VERSION "created by canmatrix"

NS_ :

BS_:

BU_: RadarFrontCenter VideoFrontCenter DASy ReceiveECU

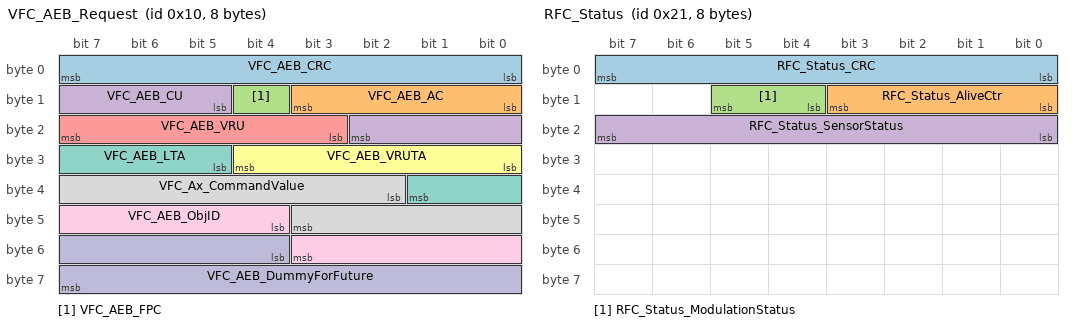
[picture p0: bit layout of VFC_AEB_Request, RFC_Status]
BO_ 16 VFC_AEB_Request: 8 VideoFrontCenter
 SG_ VFC_AEB_CRC : 0|8@1+ (1,0) [0|255] ""  DASy
 SG_ VFC_AEB_AC : 8|4@1+ (1,0) [0|15] ""  DASy
 SG_ VFC_AEB_FPC : 12|1@1+ (1,0) [0|1] ""  DASy
 SG_ VFC_AEB_CU : 13|6@1+ (1,0) [0|63] ""  DASy
 SG_ VFC_AEB_VRU : 19|5@1+ (1,0) [0|31] ""  DASy
 SG_ VFC_AEB_VRUTA : 24|5@1+ (1,0) [0|31] ""  DASy
 SG_ VFC_AEB_LTA : 29|5@1+ (1,0) [0|31] ""  DASy
 SG_ VFC_Ax_CommandValue : 34|10@1+ (0.024,-20.016) [-20.016|4.536] "m/s^2"  DASy
 SG_ VFC_AEB_ObjID : 44|8@1+ (1,0) [0|255] ""  DASy
 SG_ VFC_AEB_DummyForFuture : 52|12@1+ (1,0) [0|4095] ""  DASy

BO_ 32 VFC_Status: 20 VideoFrontCenter
 SG_ VFC_Status_CRC : 0|16@1+ (1,0) [0|65535] ""  DASy
 SG_ VFC_Status_AliveCtr : 16|8@1+ (1,0) [0|255] ""  DASy
 SG_ VFC_Status_SensorOrientYaw : 24|10@1+ (0.0005,-0.256) [-0.256|0.2555] "rad"  DASy
 SG_ VFC_Status_SensorOrientPitch : 34|10@1+ (0.0005,-0.256) [-0.256|0.2555] "rad"  DASy
 SG_ VFC_Status_SensorOrientRoll : 44|10@1+ (0.0005,-0.256) [-0.256|0.2555] "rad"  DASy
 SG_ VFC_Status_TimeStampStatus : 56|8@1+ (1,0) [0|255] ""  DASy
 SG_ VFC_Status_TimeStamp : 64|26@1+ (1,0) [0|67108863] "ms"  DASy
 SG_ VFC_Status_FrameNumber : 96|16@1+ (1,0) [0|65535] ""  DASy
 SG_ VFC_Status_SensorOriginPointX : 112|13@1+ (0.001,-4.096) [-4.096|4.095] "m"  DASy
 SG_ VFC_Status_SensorOriginPointY : 125|12@1+ (0.001,-2.048) [-2.048|2.047] "m"  DASy
 SG_ VFC_Status_SensorOriginPointZ : 137|13@1+ (0.001,0) [0|5] "m"  DASy
 SG_ VFC_Status_RollerBenchState : 150|2@1+ (1,0) [0|3] ""  DASy
 SG_ VFC_Status_SensorState : 152|4@1+ (1,0) [0|15] ""  DASy
 SG_ VFC_Status_CalibrationState : 156|3@1+ (1,0) [0|7] ""  DASy
 SG_ VFC_Status_TrafficFlowType : 159|1@1+ (1,0) [0|1] ""  DASy

BO_ 33 RFC_Status: 8 RadarFrontCenter
 SG_ RFC_Status_CRC : 0|8@1+ (1,0) [0|255] ""  VideoFrontCenter,DASy
 SG_ RFC_Status_AliveCtr : 8|4@1+ (1,0) [0|15] ""  VideoFrontCenter,DASy
 SG_ RFC_Status_ModulationStatus : 12|2@1+ (1,0) [0|3] ""  VideoFrontCenter,DASy
 SG_ RFC_Status_SensorStatus : 16|8@1+ (1,0) [0|255] ""  VideoFrontCenter,DASy

BO_ 52 VFC_ObjectHdr: 24 VideoFrontCenter
 SG_ VFC_ObjHdr_CRC : 0|16@1+ (1,0) [0|65535] ""  DASy
 SG_ VFC_ObjHdr_AliveCtr : 16|8@1+ (1,0) [0|255] ""  DASy
 SG_ VFC_ObjHdr_ProtBlockCtr : 24|4@1+ (1,0) [0|15] ""  DASy
 SG_ VFC_ObjHdr_IfVersionIdMajor : 32|8@1+ (1,0) [0|255] ""  DASy
 SG_ VFC_ObjHdr_IfVersionIdMinor : 40|8@1+ (1,0) [0|255] ""  DASy
 SG_ VFC_ObjHdr_NumValidObjects : 48|6@1+ (1,0) [0|32] ""  DASy
 SG_ VFC_ObjHdr_TimeStampStatus : 56|8@1+ (1,0) [0|255] ""  DASy
 SG_ VFC_ObjHdr_TimeStamp : 64|26@1+ (1,0) [0|67108863] "ms"  DASy
 SG_ VFC_ObjHdr_SensorStatus : 96|3@1+ (1,0) [0|7] ""  DASy
 SG_ VFC_ObjHdr_FocalLengthX : 112|8@1+ (1,1572) [1572|1827] "pixel"  DASy
 SG_ VFC_ObjHdr_FocalLengthY : 120|8@1+ (1,1572) [1572|1827] "pixel"  DASy
 SG_ VFC_ObjHdr_PrincipalPointU : 128|11@1+ (1,0) [0|2047] "pixel"  DASy
 SG_ VFC_ObjHdr_PrincipalPointV : 139|10@1+ (1,0) [0|1023] "pixel"  DASy

BO_ 54 VFC_Object00: 64 VideoFrontCenter
 SG_ VFC_Obj00_CRC : 0|16@1+ (1,0) [0|65535] ""  DASy
 SG_ VFC_Obj00_AliveCtr : 16|8@1+ (1,0) [0|255] ""  DASy
 SG_ VFC_Obj00_ProtBlockCtr : 24|4@1+ (1,0) [0|15] ""  DASy
 SG_ VFC_Obj00_ExistProb : 32|6@1+ (2,0) [0|100] "%"  DASy
 SG_ VFC_Obj00_MeasurementStatus : 38|2@1+ (1,0) [0|3] ""  DASy
 SG_ VFC_Obj00_ObjId : 40|6@1+ (1,0) [1|63] ""  DASy
 SG_ VFC_Obj00_Type : 46|4@1+ (1,0) [0|15] ""  DASy
 SG_ VFC_Obj00_TypeConf : 50|6@1+ (2,0) [0|100] "%"  DASy
 SG_ VFC_Obj00_VisibleView : 56|3@1+ (1,0) [0|7] ""  DASy
 SG_ VFC_Obj00_ClassifiedView : 59|3@1+ (1,0) [0|7] ""  DASy
 SG_ VFC_Obj00_Px : 62|12@1+ (0.05,0) [0|204.75] "m"  DASy
 SG_ VFC_Obj00_Py : 74|14@1+ (0.01,-81.92) [-81.92|81.91] "m"  DASy
 SG_ VFC_Obj00_PxStdDev : 88|10@1+ (0.05,0) [0|51.15] "m"  DASy
 SG_ VFC_Obj00_PyStdDev : 98|10@1+ (0.02,0) [0|20.46] "m"  DASy
 SG_ VFC_Obj00_OrientationYaw : 108|9@1+ (0.01,-2.56) [-1.57|1.57] "rad"  DASy
 SG_ VFC_Obj00_OrientationYawStdDev : 117|6@1+ (0.01,0) [0|0.63] "rad"  DASy
 SG_ VFC_Obj00_Length : 123|9@1+ (0.05,0) [0|25.55] "m"  DASy
 SG_ VFC_Obj00_Width : 132|10@1+ (0.01,0) [0|10.23] "m"  DASy
 SG_ VFC_Obj00_Height : 142|9@1+ (0.01,0) [0|5.11] "m"  DASy
 SG_ VFC_Obj00_LengthStdDev : 151|7@1+ (0.05,0) [0|6.35] "m"  DASy
 SG_ VFC_Obj00_WidthStdDev : 158|7@1+ (0.01,0) [0|1.27] "m"  DASy
 SG_ VFC_Obj00_HeightStdDev : 165|7@1+ (0.01,0) [0|1.27] "m"  DASy
 SG_ VFC_Obj00_Vx : 172|11@1+ (0.1,-154) [-154|50.7] "m/s"  DASy
 SG_ VFC_Obj00_Vy : 183|10@1+ (0.1,-51.2) [-51.2|51.1] "m/s"  DASy
 SG_ VFC_Obj00_VxStdDev : 193|10@1+ (0.1,0) [0|102.3] "m/s"  DASy
 SG_ VFC_Obj00_VyStdDev : 203|9@1+ (0.1,0) [0|51.1] "m/s"  DASy
 SG_ VFC_Obj00_Ax : 212|9@1+ (0.1,-25.6) [-25.6|25.5] "m/s^2"  DASy
 SG_ VFC_Obj00_LightStatTurnIndicator : 221|3@1+ (1,0) [0|7] ""  DASy
 SG_ VFC_Obj00_Ay : 224|8@1+ (0.1,-12.8) [-12.8|12.7] "m/s^2"  DASy
 SG_ VFC_Obj00_AxStdDev : 232|8@1+ (0.1,0) [0|25.5] "m/s^2"  DASy
 SG_ VFC_Obj00_AyStdDev : 240|8@1+ (0.1,0) [0|25.5] "m/s^2"  DASy
 SG_ VFC_Obj00_MovementProbLat : 248|6@1+ (2,0) [0|100] "%"  DASy
 SG_ VFC_Obj00_MovementProbLong : 254|6@1+ (2,0) [0|100] "%"  DASy
 SG_ VFC_Obj00_2DAngPosEdgeLeft : 260|13@1+ (0.00025,-1.024) [-1.024|1.02375] "unitless"  DASy
 SG_ VFC_Obj00_2DAngPosEdgeRight : 273|13@1+ (0.00025,-1.024) [-1.024|1.02375] "unitless"  DASy
 SG_ VFC_Obj00_2DAngPosEdgeFar : 286|13@1+ (0.00025,-1.024) [-1.024|1.02375] "unitless"  DASy
 SG_ VFC_Obj00_2DAngPosEdgeBot : 299|12@1+ (0.00025,-0.512) [-0.512|0.51175] "unitless"  DASy
 SG_ VFC_Obj00_OutsideRoad : 311|1@1+ (1,0) [0|1] "unitless"  DASy
 SG_ VFC_Obj00_2DAngPosEdgeLeftStdDev : 312|8@1+ (0.0002,0) [0|0.051] "unitless"  DASy
 SG_ VFC_Obj00_2DAngPosEdgeRightStdDe : 320|8@1+ (0.0002,0) [0|0.051] "unitless"  DASy
 SG_ VFC_Obj00_2DAngPosEdgeFarStdDev : 328|8@1+ (0.0002,0) [0|0.051] "unitless"  DASy
 SG_ VFC_Obj00_2DAngPosEdgeBotStdDev : 336|8@1+ (0.0002,0) [0|0.051] "unitless"  DASy
 SG_ VFC_Obj00_2DNormVx : 344|16@1+ (0.001,-40) [-40|25.535] "1/s"  DASy
 SG_ VFC_Obj00_2DNormVy : 360|13@1+ (0.001,-4.096) [-4.096|4.095] "1/s"  DASy
 SG_ VFC_Obj00_2DNormAx : 373|13@1+ (0.002,-10) [-10|6.382] "1/s^2"  DASy
 SG_ VFC_Obj00_2DNormVxStdDev : 386|10@1+ (0.001,0) [0|1.023] "1/s"  DASy
 SG_ VFC_Obj00_MeasurementSource : 396|4@1+ (1,0) [0|15] ""  DASy
 SG_ VFC_Obj00_2DNormVyStdDev : 400|8@1+ (0.001,0) [0|0.255] "1/s"  DASy
 SG_ VFC_Obj00_2DNormAxStdDev : 408|10@1+ (0.0025,0) [0|2.5575] "1/s^2"  DASy
 SG_ VFC_Obj00_2DScaleChange : 418|14@1+ (0.0001,0.5) [0.5|2.1383] "unitless"  DASy
 SG_ VFC_Obj00_2DScaleChangeStdDev : 432|10@1+ (0.0001,0) [0|0.1023] "unitless"  DASy
 SG_ VFC_Obj00_Reliability : 442|6@1+ (1,0) [0|63] ""  DASy
 SG_ VFC_Obj00_LightStatBrakeLight : 448|3@1+ (1,0) [0|7] ""  DASy
 SG_ VFC_Obj00_OutsideRoadMeasStatus : 451|2@1+ (1,0) [0|3] ""  DASy
 SG_ VFC_Obj00_Oncoming : 453|1@1+ (1,0) [0|1] "unitless"  DASy
 SG_ VFC_Obj00_OncomingMeasStatus : 454|2@1+ (1,0) [0|3] ""  DASy
 SG_ VFC_Obj00_MovementStanding : 456|1@1+ (1,0) [0|1] "unitless"  DASy
 SG_ VFC_Obj00_MovementStandingMeasSt : 457|2@1+ (1,0) [0|3] ""  DASy
 SG_ VFC_Obj00_MovementObserved : 459|1@1+ (1,0) [0|1] "unitless"  DASy
 SG_ VFC_Obj00_MovementObservedMeasSt : 460|1@1+ (1,0) [0|1] ""  DASy
 SG_ VFC_Obj00_TargetObjTypeAcc : 461|3@1+ (1,0) [0|7] ""  DASy
 SG_ VFC_Obj00_TargetObjTypeAccConf : 464|6@1+ (2,0) [0|100] "%"  DASy

BO_ 55 VFC_Object01: 64 VideoFrontCenter
 SG_ VFC_Obj01_CRC : 0|16@1+ (1,0) [0|65535] ""  DASy
 SG_ VFC_Obj01_AliveCtr : 16|8@1+ (1,0) [0|255] ""  DASy
 SG_ VFC_Obj01_ProtBlockCtr : 24|4@1+ (1,0) [0|15] ""  DASy
 SG_ VFC_Obj01_ExistProb : 32|6@1+ (2,0) [0|100] "%"  DASy
 SG_ VFC_Obj01_MeasurementStatus : 38|2@1+ (1,0) [0|3] ""  DASy
 SG_ VFC_Obj01_ObjId : 40|6@1+ (1,0) [1|63] ""  DASy
 SG_ VFC_Obj01_Type : 46|4@1+ (1,0) [0|15] ""  DASy
 SG_ VFC_Obj01_TypeConf : 50|6@1+ (2,0) [0|100] "%"  DASy
 SG_ VFC_Obj01_VisibleView : 56|3@1+ (1,0) [0|7] ""  DASy
 SG_ VFC_Obj01_ClassifiedView : 59|3@1+ (1,0) [0|7] ""  DASy
 SG_ VFC_Obj01_Px : 62|12@1+ (0.05,0) [0|204.75] "m"  DASy
 SG_ VFC_Obj01_Py : 74|14@1+ (0.01,-81.92) [-81.92|81.91] "m"  DASy
 SG_ VFC_Obj01_PxStdDev : 88|10@1+ (0.05,0) [0|51.15] "m"  DASy
 SG_ VFC_Obj01_PyStdDev : 98|10@1+ (0.02,0) [0|20.46] "m"  DASy
 SG_ VFC_Obj01_OrientationYaw : 108|9@1+ (0.01,-2.56) [-1.57|1.57] "rad"  DASy
 SG_ VFC_Obj01_OrientationYawStdDev : 117|6@1+ (0.01,0) [0|0.63] "rad"  DASy
 SG_ VFC_Obj01_Length : 123|9@1+ (0.05,0) [0|25.55] "m"  DASy
 SG_ VFC_Obj01_Width : 132|10@1+ (0.01,0) [0|10.23] "m"  DASy
 SG_ VFC_Obj01_Height : 142|9@1+ (0.01,0) [0|5.11] "m"  DASy
 SG_ VFC_Obj01_LengthStdDev : 151|7@1+ (0.05,0) [0|6.35] "m"  DASy
 SG_ VFC_Obj01_WidthStdDev : 158|7@1+ (0.01,0) [0|1.27] "m"  DASy
 SG_ VFC_Obj01_HeightStdDev : 165|7@1+ (0.01,0) [0|1.27] "m"  DASy
 SG_ VFC_Obj01_Vx : 172|11@1+ (0.1,-154) [-154|50.7] "m/s"  DASy
 SG_ VFC_Obj01_Vy : 183|10@1+ (0.1,-51.2) [-51.2|51.1] "m/s"  DASy
 SG_ VFC_Obj01_VxStdDev : 193|10@1+ (0.1,0) [0|102.3] "m/s"  DASy
 SG_ VFC_Obj01_VyStdDev : 203|9@1+ (0.1,0) [0|51.1] "m/s"  DASy
 SG_ VFC_Obj01_Ax : 212|9@1+ (0.1,-25.6) [-25.6|25.5] "m/s^2"  DASy
 SG_ VFC_Obj01_LightStatTurnIndicator : 221|3@1+ (1,0) [0|7] ""  DASy
 SG_ VFC_Obj01_Ay : 224|8@1+ (0.1,-12.8) [-12.8|12.7] "m/s^2"  DASy
 SG_ VFC_Obj01_AxStdDev : 232|8@1+ (0.1,0) [0|25.5] "m/s^2"  DASy
 SG_ VFC_Obj01_AyStdDev : 240|8@1+ (0.1,0) [0|25.5] "m/s^2"  DASy
 SG_ VFC_Obj01_MovementProbLat : 248|6@1+ (2,0) [0|100] "%"  DASy
 SG_ VFC_Obj01_MovementProbLong : 254|6@1+ (2,0) [0|100] "%"  DASy
 SG_ VFC_Obj01_2DAngPosEdgeLeft : 260|13@1+ (0.00025,-1.024) [-1.024|1.02375] "unitless"  DASy
 SG_ VFC_Obj01_2DAngPosEdgeRight : 273|13@1+ (0.00025,-1.024) [-1.024|1.02375] "unitless"  DASy
 SG_ VFC_Obj01_2DAngPosEdgeFar : 286|13@1+ (0.00025,-1.024) [-1.024|1.02375] "unitless"  DASy
 SG_ VFC_Obj01_2DAngPosEdgeBot : 299|12@1+ (0.00025,-0.512) [-0.512|0.51175] "unitless"  DASy
 SG_ VFC_Obj01_OutsideRoad : 311|1@1+ (1,0) [0|1] "unitless"  DASy
 SG_ VFC_Obj01_2DAngPosEdgeLeftStdDev : 312|8@1+ (0.0002,0) [0|0.051] "unitless"  DASy
 SG_ VFC_Obj01_2DAngPosEdgeRightStdDe : 320|8@1+ (0.0002,0) [0|0.051] "unitless"  DASy
 SG_ VFC_Obj01_2DAngPosEdgeFarStdDev : 328|8@1+ (0.0002,0) [0|0.051] "unitless"  DASy
 SG_ VFC_Obj01_2DAngPosEdgeBotStdDev : 336|8@1+ (0.0002,0) [0|0.051] "unitless"  DASy
 SG_ VFC_Obj01_2DNormVx : 344|16@1+ (0.001,-40) [-40|25.535] "1/s"  DASy
 SG_ VFC_Obj01_2DNormVy : 360|13@1+ (0.001,-4.096) [-4.096|4.095] "1/s"  DASy
 SG_ VFC_Obj01_2DNormAx : 373|13@1+ (0.002,-10) [-10|6.382] "1/s^2"  DASy
 SG_ VFC_Obj01_2DNormVxStdDev : 386|10@1+ (0.001,0) [0|1.023] "1/s"  DASy
 SG_ VFC_Obj01_MeasurementSource : 396|4@1+ (1,0) [0|15] ""  DASy
 SG_ VFC_Obj01_2DNormVyStdDev : 400|8@1+ (0.001,0) [0|0.255] "1/s"  DASy
 SG_ VFC_Obj01_2DNormAxStdDev : 408|10@1+ (0.0025,0) [0|2.5575] "1/s^2"  DASy
 SG_ VFC_Obj01_2DScaleChange : 418|14@1+ (0.0001,0.5) [0.5|2.1383] "unitless"  DASy
 SG_ VFC_Obj01_2DScaleChangeStdDev : 432|10@1+ (0.0001,0) [0|0.1023] "unitless"  DASy
 SG_ VFC_Obj01_Reliability : 442|6@1+ (1,0) [0|63] ""  DASy
 SG_ VFC_Obj01_LightStatBrakeLight : 448|3@1+ (1,0) [0|7] ""  DASy
 SG_ VFC_Obj01_OutsideRoadMeasStatus : 451|2@1+ (1,0) [0|3] ""  DASy
 SG_ VFC_Obj01_Oncoming : 453|1@1+ (1,0) [0|1] "unitless"  DASy
 SG_ VFC_Obj01_OncomingMeasStatus : 454|2@1+ (1,0) [0|3] ""  DASy
 SG_ VFC_Obj01_MovementStanding : 456|1@1+ (1,0) [0|1] "unitless"  DASy
 SG_ VFC_Obj01_MovementStandingMeasSt : 457|2@1+ (1,0) [0|3] ""  DASy
 SG_ VFC_Obj01_MovementObserved : 459|1@1+ (1,0) [0|1] "unitless"  DASy
 SG_ VFC_Obj01_MovementObservedMeasSt : 460|1@1+ (1,0) [0|1] ""  DASy
 SG_ VFC_Obj01_TargetObjTypeAcc : 461|3@1+ (1,0) [0|7] ""  DASy
 SG_ VFC_Obj01_TargetObjTypeAccConf : 464|6@1+ (2,0) [0|100] "%"  DASy

BO_ 56 VFC_Object02: 64 VideoFrontCenter
 SG_ VFC_Obj02_CRC : 0|16@1+ (1,0) [0|65535] ""  DASy
 SG_ VFC_Obj02_AliveCtr : 16|8@1+ (1,0) [0|255] ""  DASy
 SG_ VFC_Obj02_ProtBlockCtr : 24|4@1+ (1,0) [0|15] ""  DASy
 SG_ VFC_Obj02_ExistProb : 32|6@1+ (2,0) [0|100] "%"  DASy
 SG_ VFC_Obj02_MeasurementStatus : 38|2@1+ (1,0) [0|3] ""  DASy
 SG_ VFC_Obj02_ObjId : 40|6@1+ (1,0) [1|63] ""  DASy
 SG_ VFC_Obj02_Type : 46|4@1+ (1,0) [0|15] ""  DASy
 SG_ VFC_Obj02_TypeConf : 50|6@1+ (2,0) [0|100] "%"  DASy
 SG_ VFC_Obj02_VisibleView : 56|3@1+ (1,0) [0|7] ""  DASy
 SG_ VFC_Obj02_ClassifiedView : 59|3@1+ (1,0) [0|7] ""  DASy
 SG_ VFC_Obj02_Px : 62|12@1+ (0.05,0) [0|204.75] "m"  DASy
 SG_ VFC_Obj02_Py : 74|14@1+ (0.01,-81.92) [-81.92|81.91] "m"  DASy
 SG_ VFC_Obj02_PxStdDev : 88|10@1+ (0.05,0) [0|51.15] "m"  DASy
 SG_ VFC_Obj02_PyStdDev : 98|10@1+ (0.02,0) [0|20.46] "m"  DASy
 SG_ VFC_Obj02_OrientationYaw : 108|9@1+ (0.01,-2.56) [-1.57|1.57] "rad"  DASy
 SG_ VFC_Obj02_OrientationYawStdDev : 117|6@1+ (0.01,0) [0|0.63] "rad"  DASy
 SG_ VFC_Obj02_Length : 123|9@1+ (0.05,0) [0|25.55] "m"  DASy
 SG_ VFC_Obj02_Width : 132|10@1+ (0.01,0) [0|10.23] "m"  DASy
 SG_ VFC_Obj02_Height : 142|9@1+ (0.01,0) [0|5.11] "m"  DASy
 SG_ VFC_Obj02_LengthStdDev : 151|7@1+ (0.05,0) [0|6.35] "m"  DASy
 SG_ VFC_Obj02_WidthStdDev : 158|7@1+ (0.01,0) [0|1.27] "m"  DASy
 SG_ VFC_Obj02_HeightStdDev : 165|7@1+ (0.01,0) [0|1.27] "m"  DASy
 SG_ VFC_Obj02_Vx : 172|11@1+ (0.1,-154) [-154|50.7] "m/s"  DASy
 SG_ VFC_Obj02_Vy : 183|10@1+ (0.1,-51.2) [-51.2|51.1] "m/s"  DASy
 SG_ VFC_Obj02_VxStdDev : 193|10@1+ (0.1,0) [0|102.3] "m/s"  DASy
 SG_ VFC_Obj02_VyStdDev : 203|9@1+ (0.1,0) [0|51.1] "m/s"  DASy
 SG_ VFC_Obj02_Ax : 212|9@1+ (0.1,-25.6) [-25.6|25.5] "m/s^2"  DASy
 SG_ VFC_Obj02_LightStatTurnIndicator : 221|3@1+ (1,0) [0|7] ""  DASy
 SG_ VFC_Obj02_Ay : 224|8@1+ (0.1,-12.8) [-12.8|12.7] "m/s^2"  DASy
 SG_ VFC_Obj02_AxStdDev : 232|8@1+ (0.1,0) [0|25.5] "m/s^2"  DASy
 SG_ VFC_Obj02_AyStdDev : 240|8@1+ (0.1,0) [0|25.5] "m/s^2"  DASy
 SG_ VFC_Obj02_MovementProbLat : 248|6@1+ (2,0) [0|100] "%"  DASy
 SG_ VFC_Obj02_MovementProbLong : 254|6@1+ (2,0) [0|100] "%"  DASy
 SG_ VFC_Obj02_2DAngPosEdgeLeft : 260|13@1+ (0.00025,-1.024) [-1.024|1.02375] "unitless"  DASy
 SG_ VFC_Obj02_2DAngPosEdgeRight : 273|13@1+ (0.00025,-1.024) [-1.024|1.02375] "unitless"  DASy
 SG_ VFC_Obj02_2DAngPosEdgeFar : 286|13@1+ (0.00025,-1.024) [-1.024|1.02375] "unitless"  DASy
 SG_ VFC_Obj02_2DAngPosEdgeBot : 299|12@1+ (0.00025,-0.512) [-0.512|0.51175] "unitless"  DASy
 SG_ VFC_Obj02_OutsideRoad : 311|1@1+ (1,0) [0|1] "unitless"  DASy
 SG_ VFC_Obj02_2DAngPosEdgeLeftStdDev : 312|8@1+ (0.0002,0) [0|0.051] "unitless"  DASy
 SG_ VFC_Obj02_2DAngPosEdgeRightStdDe : 320|8@1+ (0.0002,0) [0|0.051] "unitless"  DASy
 SG_ VFC_Obj02_2DAngPosEdgeFarStdDev : 328|8@1+ (0.0002,0) [0|0.051] "unitless"  DASy
 SG_ VFC_Obj02_2DAngPosEdgeBotStdDev : 336|8@1+ (0.0002,0) [0|0.051] "unitless"  DASy
 SG_ VFC_Obj02_2DNormVx : 344|16@1+ (0.001,-40) [-40|25.535] "1/s"  DASy
 SG_ VFC_Obj02_2DNormVy : 360|13@1+ (0.001,-4.096) [-4.096|4.095] "1/s"  DASy
 SG_ VFC_Obj02_2DNormAx : 373|13@1+ (0.002,-10) [-10|6.382] "1/s^2"  DASy
 SG_ VFC_Obj02_2DNormVxStdDev : 386|10@1+ (0.001,0) [0|1.023] "1/s"  DASy
 SG_ VFC_Obj02_MeasurementSource : 396|4@1+ (1,0) [0|15] ""  DASy
 SG_ VFC_Obj02_2DNormVyStdDev : 400|8@1+ (0.001,0) [0|0.255] "1/s"  DASy
 SG_ VFC_Obj02_2DNormAxStdDev : 408|10@1+ (0.0025,0) [0|2.5575] "1/s^2"  DASy
 SG_ VFC_Obj02_2DScaleChange : 418|14@1+ (0.0001,0.5) [0.5|2.1383] "unitless"  DASy
 SG_ VFC_Obj02_2DScaleChangeStdDev : 432|10@1+ (0.0001,0) [0|0.1023] "unitless"  DASy
 SG_ VFC_Obj02_Reliability : 442|6@1+ (1,0) [0|63] ""  DASy
 SG_ VFC_Obj02_LightStatBrakeLight : 448|3@1+ (1,0) [0|7] ""  DASy
 SG_ VFC_Obj02_OutsideRoadMeasStatus : 451|2@1+ (1,0) [0|3] ""  DASy
 SG_ VFC_Obj02_Oncoming : 453|1@1+ (1,0) [0|1] "unitless"  DASy
 SG_ VFC_Obj02_OncomingMeasStatus : 454|2@1+ (1,0) [0|3] ""  DASy
 SG_ VFC_Obj02_MovementStanding : 456|1@1+ (1,0) [0|1] "unitless"  DASy
 SG_ VFC_Obj02_MovementStandingMeasSt : 457|2@1+ (1,0) [0|3] ""  DASy
 SG_ VFC_Obj02_MovementObserved : 459|1@1+ (1,0) [0|1] "unitless"  DASy
 SG_ VFC_Obj02_MovementObservedMeasSt : 460|1@1+ (1,0) [0|1] ""  DASy
 SG_ VFC_Obj02_TargetObjTypeAcc : 461|3@1+ (1,0) [0|7] ""  DASy
 SG_ VFC_Obj02_TargetObjTypeAccConf : 464|6@1+ (2,0) [0|100] "%"  DASy

BO_ 57 VFC_Object03: 64 VideoFrontCenter
 SG_ VFC_Obj03_CRC : 0|16@1+ (1,0) [0|65535] ""  DASy
 SG_ VFC_Obj03_AliveCtr : 16|8@1+ (1,0) [0|255] ""  DASy
 SG_ VFC_Obj03_ProtBlockCtr : 24|4@1+ (1,0) [0|15] ""  DASy
 SG_ VFC_Obj03_ExistProb : 32|6@1+ (2,0) [0|100] "%"  DASy
 SG_ VFC_Obj03_MeasurementStatus : 38|2@1+ (1,0) [0|3] ""  DASy
 SG_ VFC_Obj03_ObjId : 40|6@1+ (1,0) [1|63] ""  DASy
 SG_ VFC_Obj03_Type : 46|4@1+ (1,0) [0|15] ""  DASy
 SG_ VFC_Obj03_TypeConf : 50|6@1+ (2,0) [0|100] "%"  DASy
 SG_ VFC_Obj03_VisibleView : 56|3@1+ (1,0) [0|7] ""  DASy
 SG_ VFC_Obj03_ClassifiedView : 59|3@1+ (1,0) [0|7] ""  DASy
 SG_ VFC_Obj03_Px : 62|12@1+ (0.05,0) [0|204.75] "m"  DASy
 SG_ VFC_Obj03_Py : 74|14@1+ (0.01,-81.92) [-81.92|81.91] "m"  DASy
 SG_ VFC_Obj03_PxStdDev : 88|10@1+ (0.05,0) [0|51.15] "m"  DASy
 SG_ VFC_Obj03_PyStdDev : 98|10@1+ (0.02,0) [0|20.46] "m"  DASy
 SG_ VFC_Obj03_OrientationYaw : 108|9@1+ (0.01,-2.56) [-1.57|1.57] "rad"  DASy
 SG_ VFC_Obj03_OrientationYawStdDev : 117|6@1+ (0.01,0) [0|0.63] "rad"  DASy
 SG_ VFC_Obj03_Length : 123|9@1+ (0.05,0) [0|25.55] "m"  DASy
 SG_ VFC_Obj03_Width : 132|10@1+ (0.01,0) [0|10.23] "m"  DASy
 SG_ VFC_Obj03_Height : 142|9@1+ (0.01,0) [0|5.11] "m"  DASy
 SG_ VFC_Obj03_LengthStdDev : 151|7@1+ (0.05,0) [0|6.35] "m"  DASy
 SG_ VFC_Obj03_WidthStdDev : 158|7@1+ (0.01,0) [0|1.27] "m"  DASy
 SG_ VFC_Obj03_HeightStdDev : 165|7@1+ (0.01,0) [0|1.27] "m"  DASy
 SG_ VFC_Obj03_Vx : 172|11@1+ (0.1,-154) [-154|50.7] "m/s"  DASy
 SG_ VFC_Obj03_Vy : 183|10@1+ (0.1,-51.2) [-51.2|51.1] "m/s"  DASy
 SG_ VFC_Obj03_VxStdDev : 193|10@1+ (0.1,0) [0|102.3] "m/s"  DASy
 SG_ VFC_Obj03_VyStdDev : 203|9@1+ (0.1,0) [0|51.1] "m/s"  DASy
 SG_ VFC_Obj03_Ax : 212|9@1+ (0.1,-25.6) [-25.6|25.5] "m/s^2"  DASy
 SG_ VFC_Obj03_LightStatTurnIndicator : 221|3@1+ (1,0) [0|7] ""  DASy
 SG_ VFC_Obj03_Ay : 224|8@1+ (0.1,-12.8) [-12.8|12.7] "m/s^2"  DASy
 SG_ VFC_Obj03_AxStdDev : 232|8@1+ (0.1,0) [0|25.5] "m/s^2"  DASy
 SG_ VFC_Obj03_AyStdDev : 240|8@1+ (0.1,0) [0|25.5] "m/s^2"  DASy
 SG_ VFC_Obj03_MovementProbLat : 248|6@1+ (2,0) [0|100] "%"  DASy
 SG_ VFC_Obj03_MovementProbLong : 254|6@1+ (2,0) [0|100] "%"  DASy
 SG_ VFC_Obj03_2DAngPosEdgeLeft : 260|13@1+ (0.00025,-1.024) [-1.024|1.02375] "unitless"  DASy
 SG_ VFC_Obj03_2DAngPosEdgeRight : 273|13@1+ (0.00025,-1.024) [-1.024|1.02375] "unitless"  DASy
 SG_ VFC_Obj03_2DAngPosEdgeFar : 286|13@1+ (0.00025,-1.024) [-1.024|1.02375] "unitless"  DASy
 SG_ VFC_Obj03_2DAngPosEdgeBot : 299|12@1+ (0.00025,-0.512) [-0.512|0.51175] "unitless"  DASy
 SG_ VFC_Obj03_OutsideRoad : 311|1@1+ (1,0) [0|1] "unitless"  DASy
 SG_ VFC_Obj03_2DAngPosEdgeLeftStdDev : 312|8@1+ (0.0002,0) [0|0.051] "unitless"  DASy
 SG_ VFC_Obj03_2DAngPosEdgeRightStdDe : 320|8@1+ (0.0002,0) [0|0.051] "unitless"  DASy
 SG_ VFC_Obj03_2DAngPosEdgeFarStdDev : 328|8@1+ (0.0002,0) [0|0.051] "unitless"  DASy
 SG_ VFC_Obj03_2DAngPosEdgeBotStdDev : 336|8@1+ (0.0002,0) [0|0.051] "unitless"  DASy
 SG_ VFC_Obj03_2DNormVx : 344|16@1+ (0.001,-40) [-40|25.535] "1/s"  DASy
 SG_ VFC_Obj03_2DNormVy : 360|13@1+ (0.001,-4.096) [-4.096|4.095] "1/s"  DASy
 SG_ VFC_Obj03_2DNormAx : 373|13@1+ (0.002,-10) [-10|6.382] "1/s^2"  DASy
 SG_ VFC_Obj03_2DNormVxStdDev : 386|10@1+ (0.001,0) [0|1.023] "1/s"  DASy
 SG_ VFC_Obj03_MeasurementSource : 396|4@1+ (1,0) [0|15] ""  DASy
 SG_ VFC_Obj03_2DNormVyStdDev : 400|8@1+ (0.001,0) [0|0.255] "1/s"  DASy
 SG_ VFC_Obj03_2DNormAxStdDev : 408|10@1+ (0.0025,0) [0|2.5575] "1/s^2"  DASy
 SG_ VFC_Obj03_2DScaleChange : 418|14@1+ (0.0001,0.5) [0.5|2.1383] "unitless"  DASy
 SG_ VFC_Obj03_2DScaleChangeStdDev : 432|10@1+ (0.0001,0) [0|0.1023] "unitless"  DASy
 SG_ VFC_Obj03_Reliability : 442|6@1+ (1,0) [0|63] ""  DASy
 SG_ VFC_Obj03_LightStatBrakeLight : 448|3@1+ (1,0) [0|7] ""  DASy
 SG_ VFC_Obj03_OutsideRoadMeasStatus : 451|2@1+ (1,0) [0|3] ""  DASy
 SG_ VFC_Obj03_Oncoming : 453|1@1+ (1,0) [0|1] "unitless"  DASy
 SG_ VFC_Obj03_OncomingMeasStatus : 454|2@1+ (1,0) [0|3] ""  DASy
 SG_ VFC_Obj03_MovementStanding : 456|1@1+ (1,0) [0|1] "unitless"  DASy
 SG_ VFC_Obj03_MovementStandingMeasSt : 457|2@1+ (1,0) [0|3] ""  DASy
 SG_ VFC_Obj03_MovementObserved : 459|1@1+ (1,0) [0|1] "unitless"  DASy
 SG_ VFC_Obj03_MovementObservedMeasSt : 460|1@1+ (1,0) [0|1] ""  DASy
 SG_ VFC_Obj03_TargetObjTypeAcc : 461|3@1+ (1,0) [0|7] ""  DASy
 SG_ VFC_Obj03_TargetObjTypeAccConf : 464|6@1+ (2,0) [0|100] "%"  DASy

BO_ 58 VFC_Object04: 64 VideoFrontCenter
 SG_ VFC_Obj04_CRC : 0|16@1+ (1,0) [0|65535] ""  DASy
 SG_ VFC_Obj04_AliveCtr : 16|8@1+ (1,0) [0|255] ""  DASy
 SG_ VFC_Obj04_ProtBlockCtr : 24|4@1+ (1,0) [0|15] ""  DASy
 SG_ VFC_Obj04_ExistProb : 32|6@1+ (2,0) [0|100] "%"  DASy
 SG_ VFC_Obj04_MeasurementStatus : 38|2@1+ (1,0) [0|3] ""  DASy
 SG_ VFC_Obj04_ObjId : 40|6@1+ (1,0) [1|63] ""  DASy
 SG_ VFC_Obj04_Type : 46|4@1+ (1,0) [0|15] ""  DASy
 SG_ VFC_Obj04_TypeConf : 50|6@1+ (2,0) [0|100] "%"  DASy
 SG_ VFC_Obj04_VisibleView : 56|3@1+ (1,0) [0|7] ""  DASy
 SG_ VFC_Obj04_ClassifiedView : 59|3@1+ (1,0) [0|7] ""  DASy
 SG_ VFC_Obj04_Px : 62|12@1+ (0.05,0) [0|204.75] "m"  DASy
 SG_ VFC_Obj04_Py : 74|14@1+ (0.01,-81.92) [-81.92|81.91] "m"  DASy
 SG_ VFC_Obj04_PxStdDev : 88|10@1+ (0.05,0) [0|51.15] "m"  DASy
 SG_ VFC_Obj04_PyStdDev : 98|10@1+ (0.02,0) [0|20.46] "m"  DASy
 SG_ VFC_Obj04_OrientationYaw : 108|9@1+ (0.01,-2.56) [-1.57|1.57] "rad"  DASy
 SG_ VFC_Obj04_OrientationYawStdDev : 117|6@1+ (0.01,0) [0|0.63] "rad"  DASy
 SG_ VFC_Obj04_Length : 123|9@1+ (0.05,0) [0|25.55] "m"  DASy
 SG_ VFC_Obj04_Width : 132|10@1+ (0.01,0) [0|10.23] "m"  DASy
 SG_ VFC_Obj04_Height : 142|9@1+ (0.01,0) [0|5.11] "m"  DASy
 SG_ VFC_Obj04_LengthStdDev : 151|7@1+ (0.05,0) [0|6.35] "m"  DASy
 SG_ VFC_Obj04_WidthStdDev : 158|7@1+ (0.01,0) [0|1.27] "m"  DASy
 SG_ VFC_Obj04_HeightStdDev : 165|7@1+ (0.01,0) [0|1.27] "m"  DASy
 SG_ VFC_Obj04_Vx : 172|11@1+ (0.1,-154) [-154|50.7] "m/s"  DASy
 SG_ VFC_Obj04_Vy : 183|10@1+ (0.1,-51.2) [-51.2|51.1] "m/s"  DASy
 SG_ VFC_Obj04_VxStdDev : 193|10@1+ (0.1,0) [0|102.3] "m/s"  DASy
 SG_ VFC_Obj04_VyStdDev : 203|9@1+ (0.1,0) [0|51.1] "m/s"  DASy
 SG_ VFC_Obj04_Ax : 212|9@1+ (0.1,-25.6) [-25.6|25.5] "m/s^2"  DASy
 SG_ VFC_Obj04_LightStatTurnIndicator : 221|3@1+ (1,0) [0|7] ""  DASy
 SG_ VFC_Obj04_Ay : 224|8@1+ (0.1,-12.8) [-12.8|12.7] "m/s^2"  DASy
 SG_ VFC_Obj04_AxStdDev : 232|8@1+ (0.1,0) [0|25.5] "m/s^2"  DASy
 SG_ VFC_Obj04_AyStdDev : 240|8@1+ (0.1,0) [0|25.5] "m/s^2"  DASy
 SG_ VFC_Obj04_MovementProbLat : 248|6@1+ (2,0) [0|100] "%"  DASy
 SG_ VFC_Obj04_MovementProbLong : 254|6@1+ (2,0) [0|100] "%"  DASy
 SG_ VFC_Obj04_2DAngPosEdgeLeft : 260|13@1+ (0.00025,-1.024) [-1.024|1.02375] "unitless"  DASy
 SG_ VFC_Obj04_2DAngPosEdgeRight : 273|13@1+ (0.00025,-1.024) [-1.024|1.02375] "unitless"  DASy
 SG_ VFC_Obj04_2DAngPosEdgeFar : 286|13@1+ (0.00025,-1.024) [-1.024|1.02375] "unitless"  DASy
 SG_ VFC_Obj04_2DAngPosEdgeBot : 299|12@1+ (0.00025,-0.512) [-0.512|0.51175] "unitless"  DASy
 SG_ VFC_Obj04_OutsideRoad : 311|1@1+ (1,0) [0|1] "unitless"  DASy
 SG_ VFC_Obj04_2DAngPosEdgeLeftStdDev : 312|8@1+ (0.0002,0) [0|0.051] "unitless"  DASy
 SG_ VFC_Obj04_2DAngPosEdgeRightStdDe : 320|8@1+ (0.0002,0) [0|0.051] "unitless"  DASy
 SG_ VFC_Obj04_2DAngPosEdgeFarStdDev : 328|8@1+ (0.0002,0) [0|0.051] "unitless"  DASy
 SG_ VFC_Obj04_2DAngPosEdgeBotStdDev : 336|8@1+ (0.0002,0) [0|0.051] "unitless"  DASy
 SG_ VFC_Obj04_2DNormVx : 344|16@1+ (0.001,-40) [-40|25.535] "1/s"  DASy
 SG_ VFC_Obj04_2DNormVy : 360|13@1+ (0.001,-4.096) [-4.096|4.095] "1/s"  DASy
 SG_ VFC_Obj04_2DNormAx : 373|13@1+ (0.002,-10) [-10|6.382] "1/s^2"  DASy
 SG_ VFC_Obj04_2DNormVxStdDev : 386|10@1+ (0.001,0) [0|1.023] "1/s"  DASy
 SG_ VFC_Obj04_MeasurementSource : 396|4@1+ (1,0) [0|15] ""  DASy
 SG_ VFC_Obj04_2DNormVyStdDev : 400|8@1+ (0.001,0) [0|0.255] "1/s"  DASy
 SG_ VFC_Obj04_2DNormAxStdDev : 408|10@1+ (0.0025,0) [0|2.5575] "1/s^2"  DASy
 SG_ VFC_Obj04_2DScaleChange : 418|14@1+ (0.0001,0.5) [0.5|2.1383] "unitless"  DASy
 SG_ VFC_Obj04_2DScaleChangeStdDev : 432|10@1+ (0.0001,0) [0|0.1023] "unitless"  DASy
 SG_ VFC_Obj04_Reliability : 442|6@1+ (1,0) [0|63] ""  DASy
 SG_ VFC_Obj04_LightStatBrakeLight : 448|3@1+ (1,0) [0|7] ""  DASy
 SG_ VFC_Obj04_OutsideRoadMeasStatus : 451|2@1+ (1,0) [0|3] ""  DASy
 SG_ VFC_Obj04_Oncoming : 453|1@1+ (1,0) [0|1] "unitless"  DASy
 SG_ VFC_Obj04_OncomingMeasStatus : 454|2@1+ (1,0) [0|3] ""  DASy
 SG_ VFC_Obj04_MovementStanding : 456|1@1+ (1,0) [0|1] "unitless"  DASy
 SG_ VFC_Obj04_MovementStandingMeasSt : 457|2@1+ (1,0) [0|3] ""  DASy
 SG_ VFC_Obj04_MovementObserved : 459|1@1+ (1,0) [0|1] "unitless"  DASy
 SG_ VFC_Obj04_MovementObservedMeasSt : 460|1@1+ (1,0) [0|1] ""  DASy
 SG_ VFC_Obj04_TargetObjTypeAcc : 461|3@1+ (1,0) [0|7] ""  DASy
 SG_ VFC_Obj04_TargetObjTypeAccConf : 464|6@1+ (2,0) [0|100] "%"  DASy

BO_ 59 VFC_Object05: 64 VideoFrontCenter
 SG_ VFC_Obj05_CRC : 0|16@1+ (1,0) [0|65535] ""  DASy
 SG_ VFC_Obj05_AliveCtr : 16|8@1+ (1,0) [0|255] ""  DASy
 SG_ VFC_Obj05_ProtBlockCtr : 24|4@1+ (1,0) [0|15] ""  DASy
 SG_ VFC_Obj05_ExistProb : 32|6@1+ (2,0) [0|100] "%"  DASy
 SG_ VFC_Obj05_MeasurementStatus : 38|2@1+ (1,0) [0|3] ""  DASy
 SG_ VFC_Obj05_ObjId : 40|6@1+ (1,0) [1|63] ""  DASy
 SG_ VFC_Obj05_Type : 46|4@1+ (1,0) [0|15] ""  DASy
 SG_ VFC_Obj05_TypeConf : 50|6@1+ (2,0) [0|100] "%"  DASy
 SG_ VFC_Obj05_VisibleView : 56|3@1+ (1,0) [0|7] ""  DASy
 SG_ VFC_Obj05_ClassifiedView : 59|3@1+ (1,0) [0|7] ""  DASy
 SG_ VFC_Obj05_Px : 62|12@1+ (0.05,0) [0|204.75] "m"  DASy
 SG_ VFC_Obj05_Py : 74|14@1+ (0.01,-81.92) [-81.92|81.91] "m"  DASy
 SG_ VFC_Obj05_PxStdDev : 88|10@1+ (0.05,0) [0|51.15] "m"  DASy
 SG_ VFC_Obj05_PyStdDev : 98|10@1+ (0.02,0) [0|20.46] "m"  DASy
 SG_ VFC_Obj05_OrientationYaw : 108|9@1+ (0.01,-2.56) [-1.57|1.57] "rad"  DASy
 SG_ VFC_Obj05_OrientationYawStdDev : 117|6@1+ (0.01,0) [0|0.63] "rad"  DASy
 SG_ VFC_Obj05_Length : 123|9@1+ (0.05,0) [0|25.55] "m"  DASy
 SG_ VFC_Obj05_Width : 132|10@1+ (0.01,0) [0|10.23] "m"  DASy
 SG_ VFC_Obj05_Height : 142|9@1+ (0.01,0) [0|5.11] "m"  DASy
 SG_ VFC_Obj05_LengthStdDev : 151|7@1+ (0.05,0) [0|6.35] "m"  DASy
 SG_ VFC_Obj05_WidthStdDev : 158|7@1+ (0.01,0) [0|1.27] "m"  DASy
 SG_ VFC_Obj05_HeightStdDev : 165|7@1+ (0.01,0) [0|1.27] "m"  DASy
 SG_ VFC_Obj05_Vx : 172|11@1+ (0.1,-154) [-154|50.7] "m/s"  DASy
 SG_ VFC_Obj05_Vy : 183|10@1+ (0.1,-51.2) [-51.2|51.1] "m/s"  DASy
 SG_ VFC_Obj05_VxStdDev : 193|10@1+ (0.1,0) [0|102.3] "m/s"  DASy
 SG_ VFC_Obj05_VyStdDev : 203|9@1+ (0.1,0) [0|51.1] "m/s"  DASy
 SG_ VFC_Obj05_Ax : 212|9@1+ (0.1,-25.6) [-25.6|25.5] "m/s^2"  DASy
 SG_ VFC_Obj05_LightStatTurnIndicator : 221|3@1+ (1,0) [0|7] ""  DASy
 SG_ VFC_Obj05_Ay : 224|8@1+ (0.1,-12.8) [-12.8|12.7] "m/s^2"  DASy
 SG_ VFC_Obj05_AxStdDev : 232|8@1+ (0.1,0) [0|25.5] "m/s^2"  DASy
 SG_ VFC_Obj05_AyStdDev : 240|8@1+ (0.1,0) [0|25.5] "m/s^2"  DASy
 SG_ VFC_Obj05_MovementProbLat : 248|6@1+ (2,0) [0|100] "%"  DASy
 SG_ VFC_Obj05_MovementProbLong : 254|6@1+ (2,0) [0|100] "%"  DASy
 SG_ VFC_Obj05_2DAngPosEdgeLeft : 260|13@1+ (0.00025,-1.024) [-1.024|1.02375] "unitless"  DASy
 SG_ VFC_Obj05_2DAngPosEdgeRight : 273|13@1+ (0.00025,-1.024) [-1.024|1.02375] "unitless"  DASy
 SG_ VFC_Obj05_2DAngPosEdgeFar : 286|13@1+ (0.00025,-1.024) [-1.024|1.02375] "unitless"  DASy
 SG_ VFC_Obj05_2DAngPosEdgeBot : 299|12@1+ (0.00025,-0.512) [-0.512|0.51175] "unitless"  DASy
 SG_ VFC_Obj05_OutsideRoad : 311|1@1+ (1,0) [0|1] "unitless"  DASy
 SG_ VFC_Obj05_2DAngPosEdgeLeftStdDev : 312|8@1+ (0.0002,0) [0|0.051] "unitless"  DASy
 SG_ VFC_Obj05_2DAngPosEdgeRightStdDe : 320|8@1+ (0.0002,0) [0|0.051] "unitless"  DASy
 SG_ VFC_Obj05_2DAngPosEdgeFarStdDev : 328|8@1+ (0.0002,0) [0|0.051] "unitless"  DASy
 SG_ VFC_Obj05_2DAngPosEdgeBotStdDev : 336|8@1+ (0.0002,0) [0|0.051] "unitless"  DASy
 SG_ VFC_Obj05_2DNormVx : 344|16@1+ (0.001,-40) [-40|25.535] "1/s"  DASy
 SG_ VFC_Obj05_2DNormVy : 360|13@1+ (0.001,-4.096) [-4.096|4.095] "1/s"  DASy
 SG_ VFC_Obj05_2DNormAx : 373|13@1+ (0.002,-10) [-10|6.382] "1/s^2"  DASy
 SG_ VFC_Obj05_2DNormVxStdDev : 386|10@1+ (0.001,0) [0|1.023] "1/s"  DASy
 SG_ VFC_Obj05_MeasurementSource : 396|4@1+ (1,0) [0|15] ""  DASy
 SG_ VFC_Obj05_2DNormVyStdDev : 400|8@1+ (0.001,0) [0|0.255] "1/s"  DASy
 SG_ VFC_Obj05_2DNormAxStdDev : 408|10@1+ (0.0025,0) [0|2.5575] "1/s^2"  DASy
 SG_ VFC_Obj05_2DScaleChange : 418|14@1+ (0.0001,0.5) [0.5|2.1383] "unitless"  DASy
 SG_ VFC_Obj05_2DScaleChangeStdDev : 432|10@1+ (0.0001,0) [0|0.1023] "unitless"  DASy
 SG_ VFC_Obj05_Reliability : 442|6@1+ (1,0) [0|63] ""  DASy
 SG_ VFC_Obj05_LightStatBrakeLight : 448|3@1+ (1,0) [0|7] ""  DASy
 SG_ VFC_Obj05_OutsideRoadMeasStatus : 451|2@1+ (1,0) [0|3] ""  DASy
 SG_ VFC_Obj05_Oncoming : 453|1@1+ (1,0) [0|1] "unitless"  DASy
 SG_ VFC_Obj05_OncomingMeasStatus : 454|2@1+ (1,0) [0|3] ""  DASy
 SG_ VFC_Obj05_MovementStanding : 456|1@1+ (1,0) [0|1] "unitless"  DASy
 SG_ VFC_Obj05_MovementStandingMeasSt : 457|2@1+ (1,0) [0|3] ""  DASy
 SG_ VFC_Obj05_MovementObserved : 459|1@1+ (1,0) [0|1] "unitless"  DASy
 SG_ VFC_Obj05_MovementObservedMeasSt : 460|1@1+ (1,0) [0|1] ""  DASy
 SG_ VFC_Obj05_TargetObjTypeAcc : 461|3@1+ (1,0) [0|7] ""  DASy
 SG_ VFC_Obj05_TargetObjTypeAccConf : 464|6@1+ (2,0) [0|100] "%"  DASy

BO_ 60 VFC_Object06: 64 VideoFrontCenter
 SG_ VFC_Obj06_CRC : 0|16@1+ (1,0) [0|65535] ""  DASy
 SG_ VFC_Obj06_AliveCtr : 16|8@1+ (1,0) [0|255] ""  DASy
 SG_ VFC_Obj06_ProtBlockCtr : 24|4@1+ (1,0) [0|15] ""  DASy
 SG_ VFC_Obj06_ExistProb : 32|6@1+ (2,0) [0|100] "%"  DASy
 SG_ VFC_Obj06_MeasurementStatus : 38|2@1+ (1,0) [0|3] ""  DASy
 SG_ VFC_Obj06_ObjId : 40|6@1+ (1,0) [1|63] ""  DASy
 SG_ VFC_Obj06_Type : 46|4@1+ (1,0) [0|15] ""  DASy
 SG_ VFC_Obj06_TypeConf : 50|6@1+ (2,0) [0|100] "%"  DASy
 SG_ VFC_Obj06_VisibleView : 56|3@1+ (1,0) [0|7] ""  DASy
 SG_ VFC_Obj06_ClassifiedView : 59|3@1+ (1,0) [0|7] ""  DASy
 SG_ VFC_Obj06_Px : 62|12@1+ (0.05,0) [0|204.75] "m"  DASy
 SG_ VFC_Obj06_Py : 74|14@1+ (0.01,-81.92) [-81.92|81.91] "m"  DASy
 SG_ VFC_Obj06_PxStdDev : 88|10@1+ (0.05,0) [0|51.15] "m"  DASy
 SG_ VFC_Obj06_PyStdDev : 98|10@1+ (0.02,0) [0|20.46] "m"  DASy
 SG_ VFC_Obj06_OrientationYaw : 108|9@1+ (0.01,-2.56) [-1.57|1.57] "rad"  DASy
 SG_ VFC_Obj06_OrientationYawStdDev : 117|6@1+ (0.01,0) [0|0.63] "rad"  DASy
 SG_ VFC_Obj06_Length : 123|9@1+ (0.05,0) [0|25.55] "m"  DASy
 SG_ VFC_Obj06_Width : 132|10@1+ (0.01,0) [0|10.23] "m"  DASy
 SG_ VFC_Obj06_Height : 142|9@1+ (0.01,0) [0|5.11] "m"  DASy
 SG_ VFC_Obj06_LengthStdDev : 151|7@1+ (0.05,0) [0|6.35] "m"  DASy
 SG_ VFC_Obj06_WidthStdDev : 158|7@1+ (0.01,0) [0|1.27] "m"  DASy
 SG_ VFC_Obj06_HeightStdDev : 165|7@1+ (0.01,0) [0|1.27] "m"  DASy
 SG_ VFC_Obj06_Vx : 172|11@1+ (0.1,-154) [-154|50.7] "m/s"  DASy
 SG_ VFC_Obj06_Vy : 183|10@1+ (0.1,-51.2) [-51.2|51.1] "m/s"  DASy
 SG_ VFC_Obj06_VxStdDev : 193|10@1+ (0.1,0) [0|102.3] "m/s"  DASy
 SG_ VFC_Obj06_VyStdDev : 203|9@1+ (0.1,0) [0|51.1] "m/s"  DASy
 SG_ VFC_Obj06_Ax : 212|9@1+ (0.1,-25.6) [-25.6|25.5] "m/s^2"  DASy
 SG_ VFC_Obj06_LightStatTurnIndicator : 221|3@1+ (1,0) [0|7] ""  DASy
 SG_ VFC_Obj06_Ay : 224|8@1+ (0.1,-12.8) [-12.8|12.7] "m/s^2"  DASy
 SG_ VFC_Obj06_AxStdDev : 232|8@1+ (0.1,0) [0|25.5] "m/s^2"  DASy
 SG_ VFC_Obj06_AyStdDev : 240|8@1+ (0.1,0) [0|25.5] "m/s^2"  DASy
 SG_ VFC_Obj06_MovementProbLat : 248|6@1+ (2,0) [0|100] "%"  DASy
 SG_ VFC_Obj06_MovementProbLong : 254|6@1+ (2,0) [0|100] "%"  DASy
 SG_ VFC_Obj06_2DAngPosEdgeLeft : 260|13@1+ (0.00025,-1.024) [-1.024|1.02375] "unitless"  DASy
 SG_ VFC_Obj06_2DAngPosEdgeRight : 273|13@1+ (0.00025,-1.024) [-1.024|1.02375] "unitless"  DASy
 SG_ VFC_Obj06_2DAngPosEdgeFar : 286|13@1+ (0.00025,-1.024) [-1.024|1.02375] "unitless"  DASy
 SG_ VFC_Obj06_2DAngPosEdgeBot : 299|12@1+ (0.00025,-0.512) [-0.512|0.51175] "unitless"  DASy
 SG_ VFC_Obj06_OutsideRoad : 311|1@1+ (1,0) [0|1] "unitless"  DASy
 SG_ VFC_Obj06_2DAngPosEdgeLeftStdDev : 312|8@1+ (0.0002,0) [0|0.051] "unitless"  DASy
 SG_ VFC_Obj06_2DAngPosEdgeRightStdDe : 320|8@1+ (0.0002,0) [0|0.051] "unitless"  DASy
 SG_ VFC_Obj06_2DAngPosEdgeFarStdDev : 328|8@1+ (0.0002,0) [0|0.051] "unitless"  DASy
 SG_ VFC_Obj06_2DAngPosEdgeBotStdDev : 336|8@1+ (0.0002,0) [0|0.051] "unitless"  DASy
 SG_ VFC_Obj06_2DNormVx : 344|16@1+ (0.001,-40) [-40|25.535] "1/s"  DASy
 SG_ VFC_Obj06_2DNormVy : 360|13@1+ (0.001,-4.096) [-4.096|4.095] "1/s"  DASy
 SG_ VFC_Obj06_2DNormAx : 373|13@1+ (0.002,-10) [-10|6.382] "1/s^2"  DASy
 SG_ VFC_Obj06_2DNormVxStdDev : 386|10@1+ (0.001,0) [0|1.023] "1/s"  DASy
 SG_ VFC_Obj06_MeasurementSource : 396|4@1+ (1,0) [0|15] ""  DASy
 SG_ VFC_Obj06_2DNormVyStdDev : 400|8@1+ (0.001,0) [0|0.255] "1/s"  DASy
 SG_ VFC_Obj06_2DNormAxStdDev : 408|10@1+ (0.0025,0) [0|2.5575] "1/s^2"  DASy
 SG_ VFC_Obj06_2DScaleChange : 418|14@1+ (0.0001,0.5) [0.5|2.1383] "unitless"  DASy
 SG_ VFC_Obj06_2DScaleChangeStdDev : 432|10@1+ (0.0001,0) [0|0.1023] "unitless"  DASy
 SG_ VFC_Obj06_Reliability : 442|6@1+ (1,0) [0|63] ""  DASy
 SG_ VFC_Obj06_LightStatBrakeLight : 448|3@1+ (1,0) [0|7] ""  DASy
 SG_ VFC_Obj06_OutsideRoadMeasStatus : 451|2@1+ (1,0) [0|3] ""  DASy
 SG_ VFC_Obj06_Oncoming : 453|1@1+ (1,0) [0|1] "unitless"  DASy
 SG_ VFC_Obj06_OncomingMeasStatus : 454|2@1+ (1,0) [0|3] ""  DASy
 SG_ VFC_Obj06_MovementStanding : 456|1@1+ (1,0) [0|1] "unitless"  DASy
 SG_ VFC_Obj06_MovementStandingMeasSt : 457|2@1+ (1,0) [0|3] ""  DASy
 SG_ VFC_Obj06_MovementObserved : 459|1@1+ (1,0) [0|1] "unitless"  DASy
 SG_ VFC_Obj06_MovementObservedMeasSt : 460|1@1+ (1,0) [0|1] ""  DASy
 SG_ VFC_Obj06_TargetObjTypeAcc : 461|3@1+ (1,0) [0|7] ""  DASy
 SG_ VFC_Obj06_TargetObjTypeAccConf : 464|6@1+ (2,0) [0|100] "%"  DASy

BO_ 61 VFC_Object07: 64 VideoFrontCenter
 SG_ VFC_Obj07_CRC : 0|16@1+ (1,0) [0|65535] ""  DASy
 SG_ VFC_Obj07_AliveCtr : 16|8@1+ (1,0) [0|255] ""  DASy
 SG_ VFC_Obj07_ProtBlockCtr : 24|4@1+ (1,0) [0|15] ""  DASy
 SG_ VFC_Obj07_ExistProb : 32|6@1+ (2,0) [0|100] "%"  DASy
 SG_ VFC_Obj07_MeasurementStatus : 38|2@1+ (1,0) [0|3] ""  DASy
 SG_ VFC_Obj07_ObjId : 40|6@1+ (1,0) [1|63] ""  DASy
 SG_ VFC_Obj07_Type : 46|4@1+ (1,0) [0|15] ""  DASy
 SG_ VFC_Obj07_TypeConf : 50|6@1+ (2,0) [0|100] "%"  DASy
 SG_ VFC_Obj07_VisibleView : 56|3@1+ (1,0) [0|7] ""  DASy
 SG_ VFC_Obj07_ClassifiedView : 59|3@1+ (1,0) [0|7] ""  DASy
 SG_ VFC_Obj07_Px : 62|12@1+ (0.05,0) [0|204.75] "m"  DASy
 SG_ VFC_Obj07_Py : 74|14@1+ (0.01,-81.92) [-81.92|81.91] "m"  DASy
 SG_ VFC_Obj07_PxStdDev : 88|10@1+ (0.05,0) [0|51.15] "m"  DASy
 SG_ VFC_Obj07_PyStdDev : 98|10@1+ (0.02,0) [0|20.46] "m"  DASy
 SG_ VFC_Obj07_OrientationYaw : 108|9@1+ (0.01,-2.56) [-1.57|1.57] "rad"  DASy
 SG_ VFC_Obj07_OrientationYawStdDev : 117|6@1+ (0.01,0) [0|0.63] "rad"  DASy
 SG_ VFC_Obj07_Length : 123|9@1+ (0.05,0) [0|25.55] "m"  DASy
 SG_ VFC_Obj07_Width : 132|10@1+ (0.01,0) [0|10.23] "m"  DASy
 SG_ VFC_Obj07_Height : 142|9@1+ (0.01,0) [0|5.11] "m"  DASy
 SG_ VFC_Obj07_LengthStdDev : 151|7@1+ (0.05,0) [0|6.35] "m"  DASy
 SG_ VFC_Obj07_WidthStdDev : 158|7@1+ (0.01,0) [0|1.27] "m"  DASy
 SG_ VFC_Obj07_HeightStdDev : 165|7@1+ (0.01,0) [0|1.27] "m"  DASy
 SG_ VFC_Obj07_Vx : 172|11@1+ (0.1,-154) [-154|50.7] "m/s"  DASy
 SG_ VFC_Obj07_Vy : 183|10@1+ (0.1,-51.2) [-51.2|51.1] "m/s"  DASy
 SG_ VFC_Obj07_VxStdDev : 193|10@1+ (0.1,0) [0|102.3] "m/s"  DASy
 SG_ VFC_Obj07_VyStdDev : 203|9@1+ (0.1,0) [0|51.1] "m/s"  DASy
 SG_ VFC_Obj07_Ax : 212|9@1+ (0.1,-25.6) [-25.6|25.5] "m/s^2"  DASy
 SG_ VFC_Obj07_LightStatTurnIndicator : 221|3@1+ (1,0) [0|7] ""  DASy
 SG_ VFC_Obj07_Ay : 224|8@1+ (0.1,-12.8) [-12.8|12.7] "m/s^2"  DASy
 SG_ VFC_Obj07_AxStdDev : 232|8@1+ (0.1,0) [0|25.5] "m/s^2"  DASy
 SG_ VFC_Obj07_AyStdDev : 240|8@1+ (0.1,0) [0|25.5] "m/s^2"  DASy
 SG_ VFC_Obj07_MovementProbLat : 248|6@1+ (2,0) [0|100] "%"  DASy
 SG_ VFC_Obj07_MovementProbLong : 254|6@1+ (2,0) [0|100] "%"  DASy
 SG_ VFC_Obj07_2DAngPosEdgeLeft : 260|13@1+ (0.00025,-1.024) [-1.024|1.02375] "unitless"  DASy
 SG_ VFC_Obj07_2DAngPosEdgeRight : 273|13@1+ (0.00025,-1.024) [-1.024|1.02375] "unitless"  DASy
 SG_ VFC_Obj07_2DAngPosEdgeFar : 286|13@1+ (0.00025,-1.024) [-1.024|1.02375] "unitless"  DASy
 SG_ VFC_Obj07_2DAngPosEdgeBot : 299|12@1+ (0.00025,-0.512) [-0.512|0.51175] "unitless"  DASy
 SG_ VFC_Obj07_OutsideRoad : 311|1@1+ (1,0) [0|1] "unitless"  DASy
 SG_ VFC_Obj07_2DAngPosEdgeLeftStdDev : 312|8@1+ (0.0002,0) [0|0.051] "unitless"  DASy
 SG_ VFC_Obj07_2DAngPosEdgeRightStdDe : 320|8@1+ (0.0002,0) [0|0.051] "unitless"  DASy
 SG_ VFC_Obj07_2DAngPosEdgeFarStdDev : 328|8@1+ (0.0002,0) [0|0.051] "unitless"  DASy
 SG_ VFC_Obj07_2DAngPosEdgeBotStdDev : 336|8@1+ (0.0002,0) [0|0.051] "unitless"  DASy
 SG_ VFC_Obj07_2DNormVx : 344|16@1+ (0.001,-40) [-40|25.535] "1/s"  DASy
 SG_ VFC_Obj07_2DNormVy : 360|13@1+ (0.001,-4.096) [-4.096|4.095] "1/s"  DASy
 SG_ VFC_Obj07_2DNormAx : 373|13@1+ (0.002,-10) [-10|6.382] "1/s^2"  DASy
 SG_ VFC_Obj07_2DNormVxStdDev : 386|10@1+ (0.001,0) [0|1.023] "1/s"  DASy
 SG_ VFC_Obj07_MeasurementSource : 396|4@1+ (1,0) [0|15] ""  DASy
 SG_ VFC_Obj07_2DNormVyStdDev : 400|8@1+ (0.001,0) [0|0.255] "1/s"  DASy
 SG_ VFC_Obj07_2DNormAxStdDev : 408|10@1+ (0.0025,0) [0|2.5575] "1/s^2"  DASy
 SG_ VFC_Obj07_2DScaleChange : 418|14@1+ (0.0001,0.5) [0.5|2.1383] "unitless"  DASy
 SG_ VFC_Obj07_2DScaleChangeStdDev : 432|10@1+ (0.0001,0) [0|0.1023] "unitless"  DASy
 SG_ VFC_Obj07_Reliability : 442|6@1+ (1,0) [0|63] ""  DASy
 SG_ VFC_Obj07_LightStatBrakeLight : 448|3@1+ (1,0) [0|7] ""  DASy
 SG_ VFC_Obj07_OutsideRoadMeasStatus : 451|2@1+ (1,0) [0|3] ""  DASy
 SG_ VFC_Obj07_Oncoming : 453|1@1+ (1,0) [0|1] "unitless"  DASy
 SG_ VFC_Obj07_OncomingMeasStatus : 454|2@1+ (1,0) [0|3] ""  DASy
 SG_ VFC_Obj07_MovementStanding : 456|1@1+ (1,0) [0|1] "unitless"  DASy
 SG_ VFC_Obj07_MovementStandingMeasSt : 457|2@1+ (1,0) [0|3] ""  DASy
 SG_ VFC_Obj07_MovementObserved : 459|1@1+ (1,0) [0|1] "unitless"  DASy
 SG_ VFC_Obj07_MovementObservedMeasSt : 460|1@1+ (1,0) [0|1] ""  DASy
 SG_ VFC_Obj07_TargetObjTypeAcc : 461|3@1+ (1,0) [0|7] ""  DASy
 SG_ VFC_Obj07_TargetObjTypeAccConf : 464|6@1+ (2,0) [0|100] "%"  DASy

BO_ 62 VFC_Object08: 64 VideoFrontCenter
 SG_ VFC_Obj08_CRC : 0|16@1+ (1,0) [0|65535] ""  DASy
 SG_ VFC_Obj08_AliveCtr : 16|8@1+ (1,0) [0|255] ""  DASy
 SG_ VFC_Obj08_ProtBlockCtr : 24|4@1+ (1,0) [0|15] ""  DASy
 SG_ VFC_Obj08_ExistProb : 32|6@1+ (2,0) [0|100] "%"  DASy
 SG_ VFC_Obj08_MeasurementStatus : 38|2@1+ (1,0) [0|3] ""  DASy
 SG_ VFC_Obj08_ObjId : 40|6@1+ (1,0) [1|63] ""  DASy
 SG_ VFC_Obj08_Type : 46|4@1+ (1,0) [0|15] ""  DASy
 SG_ VFC_Obj08_TypeConf : 50|6@1+ (2,0) [0|100] "%"  DASy
 SG_ VFC_Obj08_VisibleView : 56|3@1+ (1,0) [0|7] ""  DASy
 SG_ VFC_Obj08_ClassifiedView : 59|3@1+ (1,0) [0|7] ""  DASy
 SG_ VFC_Obj08_Px : 62|12@1+ (0.05,0) [0|204.75] "m"  DASy
 SG_ VFC_Obj08_Py : 74|14@1+ (0.01,-81.92) [-81.92|81.91] "m"  DASy
 SG_ VFC_Obj08_PxStdDev : 88|10@1+ (0.05,0) [0|51.15] "m"  DASy
 SG_ VFC_Obj08_PyStdDev : 98|10@1+ (0.02,0) [0|20.46] "m"  DASy
 SG_ VFC_Obj08_OrientationYaw : 108|9@1+ (0.01,-2.56) [-1.57|1.57] "rad"  DASy
 SG_ VFC_Obj08_OrientationYawStdDev : 117|6@1+ (0.01,0) [0|0.63] "rad"  DASy
 SG_ VFC_Obj08_Length : 123|9@1+ (0.05,0) [0|25.55] "m"  DASy
 SG_ VFC_Obj08_Width : 132|10@1+ (0.01,0) [0|10.23] "m"  DASy
 SG_ VFC_Obj08_Height : 142|9@1+ (0.01,0) [0|5.11] "m"  DASy
 SG_ VFC_Obj08_LengthStdDev : 151|7@1+ (0.05,0) [0|6.35] "m"  DASy
 SG_ VFC_Obj08_WidthStdDev : 158|7@1+ (0.01,0) [0|1.27] "m"  DASy
 SG_ VFC_Obj08_HeightStdDev : 165|7@1+ (0.01,0) [0|1.27] "m"  DASy
 SG_ VFC_Obj08_Vx : 172|11@1+ (0.1,-154) [-154|50.7] "m/s"  DASy
 SG_ VFC_Obj08_Vy : 183|10@1+ (0.1,-51.2) [-51.2|51.1] "m/s"  DASy
 SG_ VFC_Obj08_VxStdDev : 193|10@1+ (0.1,0) [0|102.3] "m/s"  DASy
 SG_ VFC_Obj08_VyStdDev : 203|9@1+ (0.1,0) [0|51.1] "m/s"  DASy
 SG_ VFC_Obj08_Ax : 212|9@1+ (0.1,-25.6) [-25.6|25.5] "m/s^2"  DASy
 SG_ VFC_Obj08_LightStatTurnIndicator : 221|3@1+ (1,0) [0|7] ""  DASy
 SG_ VFC_Obj08_Ay : 224|8@1+ (0.1,-12.8) [-12.8|12.7] "m/s^2"  DASy
 SG_ VFC_Obj08_AxStdDev : 232|8@1+ (0.1,0) [0|25.5] "m/s^2"  DASy
 SG_ VFC_Obj08_AyStdDev : 240|8@1+ (0.1,0) [0|25.5] "m/s^2"  DASy
 SG_ VFC_Obj08_MovementProbLat : 248|6@1+ (2,0) [0|100] "%"  DASy
 SG_ VFC_Obj08_MovementProbLong : 254|6@1+ (2,0) [0|100] "%"  DASy
 SG_ VFC_Obj08_2DAngPosEdgeLeft : 260|13@1+ (0.00025,-1.024) [-1.024|1.02375] "unitless"  DASy
 SG_ VFC_Obj08_2DAngPosEdgeRight : 273|13@1+ (0.00025,-1.024) [-1.024|1.02375] "unitless"  DASy
 SG_ VFC_Obj08_2DAngPosEdgeFar : 286|13@1+ (0.00025,-1.024) [-1.024|1.02375] "unitless"  DASy
 SG_ VFC_Obj08_2DAngPosEdgeBot : 299|12@1+ (0.00025,-0.512) [-0.512|0.51175] "unitless"  DASy
 SG_ VFC_Obj08_OutsideRoad : 311|1@1+ (1,0) [0|1] "unitless"  DASy
 SG_ VFC_Obj08_2DAngPosEdgeLeftStdDev : 312|8@1+ (0.0002,0) [0|0.051] "unitless"  DASy
 SG_ VFC_Obj08_2DAngPosEdgeRightStdDe : 320|8@1+ (0.0002,0) [0|0.051] "unitless"  DASy
 SG_ VFC_Obj08_2DAngPosEdgeFarStdDev : 328|8@1+ (0.0002,0) [0|0.051] "unitless"  DASy
 SG_ VFC_Obj08_2DAngPosEdgeBotStdDev : 336|8@1+ (0.0002,0) [0|0.051] "unitless"  DASy
 SG_ VFC_Obj08_2DNormVx : 344|16@1+ (0.001,-40) [-40|25.535] "1/s"  DASy
 SG_ VFC_Obj08_2DNormVy : 360|13@1+ (0.001,-4.096) [-4.096|4.095] "1/s"  DASy
 SG_ VFC_Obj08_2DNormAx : 373|13@1+ (0.002,-10) [-10|6.382] "1/s^2"  DASy
 SG_ VFC_Obj08_2DNormVxStdDev : 386|10@1+ (0.001,0) [0|1.023] "1/s"  DASy
 SG_ VFC_Obj08_MeasurementSource : 396|4@1+ (1,0) [0|15] ""  DASy
 SG_ VFC_Obj08_2DNormVyStdDev : 400|8@1+ (0.001,0) [0|0.255] "1/s"  DASy
 SG_ VFC_Obj08_2DNormAxStdDev : 408|10@1+ (0.0025,0) [0|2.5575] "1/s^2"  DASy
 SG_ VFC_Obj08_2DScaleChange : 418|14@1+ (0.0001,0.5) [0.5|2.1383] "unitless"  DASy
 SG_ VFC_Obj08_2DScaleChangeStdDev : 432|10@1+ (0.0001,0) [0|0.1023] "unitless"  DASy
 SG_ VFC_Obj08_Reliability : 442|6@1+ (1,0) [0|63] ""  DASy
 SG_ VFC_Obj08_LightStatBrakeLight : 448|3@1+ (1,0) [0|7] ""  DASy
 SG_ VFC_Obj08_OutsideRoadMeasStatus : 451|2@1+ (1,0) [0|3] ""  DASy
 SG_ VFC_Obj08_Oncoming : 453|1@1+ (1,0) [0|1] "unitless"  DASy
 SG_ VFC_Obj08_OncomingMeasStatus : 454|2@1+ (1,0) [0|3] ""  DASy
 SG_ VFC_Obj08_MovementStanding : 456|1@1+ (1,0) [0|1] "unitless"  DASy
 SG_ VFC_Obj08_MovementStandingMeasSt : 457|2@1+ (1,0) [0|3] ""  DASy
 SG_ VFC_Obj08_MovementObserved : 459|1@1+ (1,0) [0|1] "unitless"  DASy
 SG_ VFC_Obj08_MovementObservedMeasSt : 460|1@1+ (1,0) [0|1] ""  DASy
 SG_ VFC_Obj08_TargetObjTypeAcc : 461|3@1+ (1,0) [0|7] ""  DASy
 SG_ VFC_Obj08_TargetObjTypeAccConf : 464|6@1+ (2,0) [0|100] "%"  DASy

BO_ 63 VFC_Object09: 64 VideoFrontCenter
 SG_ VFC_Obj09_CRC : 0|16@1+ (1,0) [0|65535] ""  DASy
 SG_ VFC_Obj09_AliveCtr : 16|8@1+ (1,0) [0|255] ""  DASy
 SG_ VFC_Obj09_ProtBlockCtr : 24|4@1+ (1,0) [0|15] ""  DASy
 SG_ VFC_Obj09_ExistProb : 32|6@1+ (2,0) [0|100] "%"  DASy
 SG_ VFC_Obj09_MeasurementStatus : 38|2@1+ (1,0) [0|3] ""  DASy
 SG_ VFC_Obj09_ObjId : 40|6@1+ (1,0) [1|63] ""  DASy
 SG_ VFC_Obj09_Type : 46|4@1+ (1,0) [0|15] ""  DASy
 SG_ VFC_Obj09_TypeConf : 50|6@1+ (2,0) [0|100] "%"  DASy
 SG_ VFC_Obj09_VisibleView : 56|3@1+ (1,0) [0|7] ""  DASy
 SG_ VFC_Obj09_ClassifiedView : 59|3@1+ (1,0) [0|7] ""  DASy
 SG_ VFC_Obj09_Px : 62|12@1+ (0.05,0) [0|204.75] "m"  DASy
 SG_ VFC_Obj09_Py : 74|14@1+ (0.01,-81.92) [-81.92|81.91] "m"  DASy
 SG_ VFC_Obj09_PxStdDev : 88|10@1+ (0.05,0) [0|51.15] "m"  DASy
 SG_ VFC_Obj09_PyStdDev : 98|10@1+ (0.02,0) [0|20.46] "m"  DASy
 SG_ VFC_Obj09_OrientationYaw : 108|9@1+ (0.01,-2.56) [-1.57|1.57] "rad"  DASy
 SG_ VFC_Obj09_OrientationYawStdDev : 117|6@1+ (0.01,0) [0|0.63] "rad"  DASy
 SG_ VFC_Obj09_Length : 123|9@1+ (0.05,0) [0|25.55] "m"  DASy
 SG_ VFC_Obj09_Width : 132|10@1+ (0.01,0) [0|10.23] "m"  DASy
 SG_ VFC_Obj09_Height : 142|9@1+ (0.01,0) [0|5.11] "m"  DASy
 SG_ VFC_Obj09_LengthStdDev : 151|7@1+ (0.05,0) [0|6.35] "m"  DASy
 SG_ VFC_Obj09_WidthStdDev : 158|7@1+ (0.01,0) [0|1.27] "m"  DASy
 SG_ VFC_Obj09_HeightStdDev : 165|7@1+ (0.01,0) [0|1.27] "m"  DASy
 SG_ VFC_Obj09_Vx : 172|11@1+ (0.1,-154) [-154|50.7] "m/s"  DASy
 SG_ VFC_Obj09_Vy : 183|10@1+ (0.1,-51.2) [-51.2|51.1] "m/s"  DASy
 SG_ VFC_Obj09_VxStdDev : 193|10@1+ (0.1,0) [0|102.3] "m/s"  DASy
 SG_ VFC_Obj09_VyStdDev : 203|9@1+ (0.1,0) [0|51.1] "m/s"  DASy
 SG_ VFC_Obj09_Ax : 212|9@1+ (0.1,-25.6) [-25.6|25.5] "m/s^2"  DASy
 SG_ VFC_Obj09_LightStatTurnIndicator : 221|3@1+ (1,0) [0|7] ""  DASy
 SG_ VFC_Obj09_Ay : 224|8@1+ (0.1,-12.8) [-12.8|12.7] "m/s^2"  DASy
 SG_ VFC_Obj09_AxStdDev : 232|8@1+ (0.1,0) [0|25.5] "m/s^2"  DASy
 SG_ VFC_Obj09_AyStdDev : 240|8@1+ (0.1,0) [0|25.5] "m/s^2"  DASy
 SG_ VFC_Obj09_MovementProbLat : 248|6@1+ (2,0) [0|100] "%"  DASy
 SG_ VFC_Obj09_MovementProbLong : 254|6@1+ (2,0) [0|100] "%"  DASy
 SG_ VFC_Obj09_2DAngPosEdgeLeft : 260|13@1+ (0.00025,-1.024) [-1.024|1.02375] "unitless"  DASy
 SG_ VFC_Obj09_2DAngPosEdgeRight : 273|13@1+ (0.00025,-1.024) [-1.024|1.02375] "unitless"  DASy
 SG_ VFC_Obj09_2DAngPosEdgeFar : 286|13@1+ (0.00025,-1.024) [-1.024|1.02375] "unitless"  DASy
 SG_ VFC_Obj09_2DAngPosEdgeBot : 299|12@1+ (0.00025,-0.512) [-0.512|0.51175] "unitless"  DASy
 SG_ VFC_Obj09_OutsideRoad : 311|1@1+ (1,0) [0|1] "unitless"  DASy
 SG_ VFC_Obj09_2DAngPosEdgeLeftStdDev : 312|8@1+ (0.0002,0) [0|0.051] "unitless"  DASy
 SG_ VFC_Obj09_2DAngPosEdgeRightStdDe : 320|8@1+ (0.0002,0) [0|0.051] "unitless"  DASy
 SG_ VFC_Obj09_2DAngPosEdgeFarStdDev : 328|8@1+ (0.0002,0) [0|0.051] "unitless"  DASy
 SG_ VFC_Obj09_2DAngPosEdgeBotStdDev : 336|8@1+ (0.0002,0) [0|0.051] "unitless"  DASy
 SG_ VFC_Obj09_2DNormVx : 344|16@1+ (0.001,-40) [-40|25.535] "1/s"  DASy
 SG_ VFC_Obj09_2DNormVy : 360|13@1+ (0.001,-4.096) [-4.096|4.095] "1/s"  DASy
 SG_ VFC_Obj09_2DNormAx : 373|13@1+ (0.002,-10) [-10|6.382] "1/s^2"  DASy
 SG_ VFC_Obj09_2DNormVxStdDev : 386|10@1+ (0.001,0) [0|1.023] "1/s"  DASy
 SG_ VFC_Obj09_MeasurementSource : 396|4@1+ (1,0) [0|15] ""  DASy
 SG_ VFC_Obj09_2DNormVyStdDev : 400|8@1+ (0.001,0) [0|0.255] "1/s"  DASy
 SG_ VFC_Obj09_2DNormAxStdDev : 408|10@1+ (0.0025,0) [0|2.5575] "1/s^2"  DASy
 SG_ VFC_Obj09_2DScaleChange : 418|14@1+ (0.0001,0.5) [0.5|2.1383] "unitless"  DASy
 SG_ VFC_Obj09_2DScaleChangeStdDev : 432|10@1+ (0.0001,0) [0|0.1023] "unitless"  DASy
 SG_ VFC_Obj09_Reliability : 442|6@1+ (1,0) [0|63] ""  DASy
 SG_ VFC_Obj09_LightStatBrakeLight : 448|3@1+ (1,0) [0|7] ""  DASy
 SG_ VFC_Obj09_OutsideRoadMeasStatus : 451|2@1+ (1,0) [0|3] ""  DASy
 SG_ VFC_Obj09_Oncoming : 453|1@1+ (1,0) [0|1] "unitless"  DASy
 SG_ VFC_Obj09_OncomingMeasStatus : 454|2@1+ (1,0) [0|3] ""  DASy
 SG_ VFC_Obj09_MovementStanding : 456|1@1+ (1,0) [0|1] "unitless"  DASy
 SG_ VFC_Obj09_MovementStandingMeasSt : 457|2@1+ (1,0) [0|3] ""  DASy
 SG_ VFC_Obj09_MovementObserved : 459|1@1+ (1,0) [0|1] "unitless"  DASy
 SG_ VFC_Obj09_MovementObservedMeasSt : 460|1@1+ (1,0) [0|1] ""  DASy
 SG_ VFC_Obj09_TargetObjTypeAcc : 461|3@1+ (1,0) [0|7] ""  DASy
 SG_ VFC_Obj09_TargetObjTypeAccConf : 464|6@1+ (2,0) [0|100] "%"  DASy

CM_ SG_ 16 VFC_AEB_CRC "CRC - E2E Profile decision by customer project. Possible options: AUTOSAR Profile 1A,1B,1C,2,11A,11C,22, OEM specified E2E profile (Platform proposal Profile 22)";
CM_ SG_ 16 VFC_AEB_AC "Alive Counter - E2E Profile decision by customer project. Possible options: AUTOSAR Profile 1A,1B,1C,2,11A,11C,22, OEM specified E2E profile (Platform proposal Profile 22)";
CM_ SG_ 16 VFC_AEB_FPC "Trigger recommendation of AEB FPC (Front Pre Crash)";
CM_ SG_ 16 VFC_AEB_CU "Trigger recommendations of AEB CU (CityUrban)
Bit 0 : AEB_CU_EMERGENCY_BRAKE 
Bit 1 : AEB_CU_WARNING
Bit 2 : AEB_CU_EBA_REACTION
Bit 3 : AEB_CU_PREFILL
Bit 4 : AEB_CU_HAPTIC
Bit 5 : AEB_CU_PARTIAL_BRAKE";
CM_ SG_ 16 VFC_AEB_VRU "Trigger recommendations of AEB VRU (Vulnerable Road User)
Bit 0 : AEB_VRU_EMERGENCY_BRAKE
Bit 1 : AEB_VRU_WARNINGÂ 
Bit 2 : AEB_VRU_PREFILL
Bit 3 : AEB_VRU_EBA_REACTION
Bit 4 : AEB_VRU_HAPTIC";
CM_ SG_ 16 VFC_AEB_VRUTA "Trigger recommendations of AEB VRUTA (Vulnerable Road User Turning Assist)
Bit 0 :  AEB_VRUTA_EMERGENCY_BRAKE
Bit 1 :  AEB_VRUTA_WARNING 
Bit 2 :  AEB_VRUTA_EBA_REACTION
Bit 3 :  AEB_VRUTA_PREFILL
Bit 4 :  AEB_VRUTA_HAPTIC";
CM_ SG_ 16 VFC_AEB_LTA "Trigger recommendations of AEB LTA (Left Turn Assist)
Bit 0 : AEB_LTA_EMERGENCY_BRAKE
Bit 1 : AEB_LTA_WARNING 
Bit 2 : AEB_LTA_EBA_REACTION
Bit 3 : AEB_LTA_PREFILL
Bit 4 : AEB_LTA_HAPTIC";
CM_ SG_ 16 VFC_AEB_ObjID "Object ID of AEB event";
CM_ SG_ 32 VFC_Status_CRC "CRC - Autosar E2E Profile 5";
CM_ SG_ 32 VFC_Status_AliveCtr "Alive counter - Autosar E2E Profile 5";
CM_ SG_ 32 VFC_Status_SensorOrientYaw "The calibrated yaw angle of the camera. Only similar to ISO 23150:2023: Sensor orientation {yaw} - header (A.1.23) but with high dynamic orientation estimation";
CM_ SG_ 32 VFC_Status_SensorOrientPitch "The calibrated pitch angle of the camera ISO 23150:2023: Sensor orientation {pitch} - header (A.1.23) but with high dynamic orientation estimation";
CM_ SG_ 32 VFC_Status_SensorOrientRoll "The calibrated roll angle of the camera ISO 23150:2023: Sensor orientation {roll} - header (A.1.23) but with high dynamic orientation estimation";
CM_ SG_ 32 VFC_Status_TimeStampStatus "Autosar StbM_TimeBaseStatusType bitfield with extension:
Bit 0: TIMEOUT
Bit 1: Reserved1
Bit 2: SYNC_TO_GATEWAY
Bit 3: GLOBAL_TIME_BASE
Bit 4: TIMELEAP_FUTURE
Bit 5: TIMELEAP_PAST
Bit 6: Reserved6
Bit 7: Extension: GENERAL_ERROR";
CM_ SG_ 32 VFC_Status_TimeStamp "TimeStamp of frame ISO 23150:2023: Time stamp - measurement (A.1.5.2)";
CM_ SG_ 32 VFC_Status_FrameNumber "The frame number that the data belongs to";
CM_ SG_ 32 VFC_Status_SensorOriginPointX "The current estimation of mounting position of the camera in the longitudinal direction, similar to ISO 23150:2023: Sensor origin point {X} - header (A.1.21) but contains only the initial calibration value";
CM_ SG_ 32 VFC_Status_SensorOriginPointY "The current estimation of mounting position of the camera in the lateral direction similar to ISO 23150:2023: Sensor origin point {y} - header (A.1.21) but contains only the initial calibration value";
CM_ SG_ 32 VFC_Status_SensorOriginPointZ "The current estimation of mounting position of the camera in the vertical direction similar to ISO 23150:2023: Sensor origin point {z} - header (A.1.21) but contains only the initial calibration value";
CM_ SG_ 32 VFC_Status_RollerBenchState "The state of the roller bench test mode";
CM_ SG_ 32 VFC_Status_SensorState "The current state of the camera system";
CM_ SG_ 32 VFC_Status_CalibrationState "The calibration state of the camera system";
CM_ SG_ 32 VFC_Status_TrafficFlowType "ISO 23150:2023: Current traffic flow type (A.6.51)";
CM_ SG_ 33 RFC_Status_CRC "CRC - E2E Profile decision by customer project. Possible options: AUTOSAR Profile 1A,1B,1C,2,11A,11C,22, OEM specified E2E profile (Platform proposal Profile 22)";
CM_ SG_ 33 RFC_Status_AliveCtr "Alive counter - E2E Profile decision by customer project. Possible options: AUTOSAR Profile 1A,1B,1C,2,11A,11C,22, OEM specified E2E profile (Platform proposal Profile 22)";
CM_ SG_ 33 RFC_Status_ModulationStatus "Reflect if there is any problem with the modulation of the radar";
CM_ SG_ 33 RFC_Status_SensorStatus "Bit 0: HW MALFUNCTION
Bit 1: DSP ISSUES
Bit 2: COMMUNICATION ERRORS
Bit 3: MISALIGNMENT (OUT OF SPEC)
Bit 4: SENSOR BLIDNESS DETECTED
Bit 5: SENSOR DISTURBED
Bit 6: OTHER ISSUES
Bit 7: RESERVED
Value 0: no event
Value 1: event occured";
CM_ SG_ 52 VFC_ObjHdr_CRC "CRC - Autosar E2E Profile 5";
CM_ SG_ 52 VFC_ObjHdr_AliveCtr "Alive counter - Autosar E2E Profile 5";
CM_ SG_ 52 VFC_ObjHdr_ProtBlockCtr "Protocol-Signal: Block-Counter";
CM_ SG_ 52 VFC_ObjHdr_IfVersionIdMajor "Version information of the interface. e. g. version 1.0: Major = 1. ISO 23150:2023: Interface version ID {major, minor, patch} (A.1.1)";
CM_ SG_ 52 VFC_ObjHdr_IfVersionIdMinor "Version information of the interface. e. g. version 1.0: Minor = 0. ISO 23150:2023: Interface version ID {major, minor, patch} (A.1.1)";
CM_ SG_ 52 VFC_ObjHdr_NumValidObjects "Number of valid objects. ISO 23150:2023: Number of valid potentially moving objects (A.1.12.1)";
CM_ SG_ 52 VFC_ObjHdr_TimeStampStatus "Autosar StbM_TimeBaseStatusType bitfield with extension:
Bit 0: TIMEOUT
Bit 1: Reserved1
Bit 2: SYNC_TO_GATEWAY
Bit 3: GLOBAL_TIME_BASE
Bit 4: TIMELEAP_FUTURE
Bit 5: TIMELEAP_PAST
Bit 6: Reserved6
Bit 7: Extension: GENERAL_ERROR";
CM_ SG_ 52 VFC_ObjHdr_TimeStamp "ISO 23150:2023: Time stamp - prediction (A.1.5.1)";
CM_ SG_ 52 VFC_ObjHdr_SensorStatus "The current status of the object detection system. Similar to ISO 23150:2023: Data qualifier (A.1.9)";
CM_ SG_ 52 VFC_ObjHdr_FocalLengthX "Focal length of the camera coordinate system (camera coordinate system, origin in the camera center)";
CM_ SG_ 52 VFC_ObjHdr_FocalLengthY "Focal length of the camera coordinate system (camera coordinate system, origin in the camera center)";
CM_ SG_ 52 VFC_ObjHdr_PrincipalPointU "Principal point of the image coordinate system (in CV coordinates, origin top left)";
CM_ SG_ 52 VFC_ObjHdr_PrincipalPointV "Principal point of the image coordinate system (in CV coordinates, origin top left)";
CM_ SG_ 54 VFC_Obj00_CRC "CRC - Autosar E2E Profile 5";
CM_ SG_ 54 VFC_Obj00_AliveCtr "Alive counter - Autosar E2E Profile 5";
CM_ SG_ 54 VFC_Obj00_ProtBlockCtr "Protocol-Signal: Block-Counter";
CM_ SG_ 54 VFC_Obj00_ExistProb "Object existence probability. ISO 23150:2023: Existence probability - object level (A.2.1)";
CM_ SG_ 54 VFC_Obj00_MeasurementStatus "Indicator if the object detected is measured or predicted. ISO 23150:2023: Measurement status - object level (A.2.9)";
CM_ SG_ 54 VFC_Obj00_ObjId "Unique Object ID. ISO 23150:2023: Object ID (A.2.2)";
CM_ SG_ 54 VFC_Obj00_Type "Classification of the object. ISO 23150:2023: Potentially moving object classification type (A.2.12)";
CM_ SG_ 54 VFC_Obj00_TypeConf "Confidence of the classified object type. ISO 23150:2023: Potentially moving object classification type - confidence (A.2.13)";
CM_ SG_ 54 VFC_Obj00_VisibleView "The visible view of the detected object. Reference point is in the middle of CLASSIC (front/rear) or SIDE (left/right). Related to ISO 23150:2023: Reference point (A.2.14)";
CM_ SG_ 54 VFC_Obj00_ClassifiedView "The classified view of object to be used in connection with VisibleView and Heading angle. Related to ISO 23150:2023: Reference point (A.2.14)";
CM_ SG_ 54 VFC_Obj00_Px "Object distance in longitudinal direction. ISO 23150:2023: Position - object level {x, y, z} (A.2.15)";
CM_ SG_ 54 VFC_Obj00_Py "Object distance in lateral direction. ISO 23150:2023: Position - object level {x, y, z} (A.2.15)";
CM_ SG_ 54 VFC_Obj00_PxStdDev "Standard deviation of Object distance in longitudinal direction. ISO 23150:2023: Position - object level {x, y, z} - error (A.2.16)";
CM_ SG_ 54 VFC_Obj00_PyStdDev "Standard deviation of Object distance in lateral direction. ISO 23150:2023: Position - object level {x, y, z} - error (A.2.16)";
CM_ SG_ 54 VFC_Obj00_OrientationYaw "Heading angle of the object. ISO 23150:2023: Orientation {yaw, pitch, roll} (A.2.17)";
CM_ SG_ 54 VFC_Obj00_OrientationYawStdDev "Standard deviation of object Heading angle. ISO 23150:2023: Orientation {yaw, pitch, roll} - error (A.2.18)";
CM_ SG_ 54 VFC_Obj00_Length "Length of the object. ISO 23150:2023: Bounding box extent {length, width, height} (A.2.20)";
CM_ SG_ 54 VFC_Obj00_Width "Width of the object. ISO 23150:2023: Bounding box extent {length, width, height} (A.2.20)";
CM_ SG_ 54 VFC_Obj00_Height "Height of the object. ISO 23150:2023: Bounding box extent {length, width, height} (A.2.20)";
CM_ SG_ 54 VFC_Obj00_LengthStdDev "Standard deviation of object length. ISO 23150:2023: Bounding box extent {length, width, height} - error (A.2.21)";
CM_ SG_ 54 VFC_Obj00_WidthStdDev "Standard deviation of object width. ISO 23150:2023: Bounding box extent {length, width, height} - error (A.2.21)";
CM_ SG_ 54 VFC_Obj00_HeightStdDev "Standard deviation of object height. ISO 23150:2023: Bounding box extent {length, width, height} - error (A.2.21)";
CM_ SG_ 54 VFC_Obj00_Vx "Object velocity in longitudinal direction. ISO 23150:2023: Velocity {x, y, z} - object level (A.2.24)";
CM_ SG_ 54 VFC_Obj00_Vy "Object velocity in lateral direction. ISO 23150:2023: Velocity {x, y, z} - object level (A.2.24)";
CM_ SG_ 54 VFC_Obj00_VxStdDev "Standard deviation of Object velocity in longitudinal direction. ISO 23150:2023: Velocity {x, y, z} - object level - error (A.2.25)";
CM_ SG_ 54 VFC_Obj00_VyStdDev "Standard deviation of Object velocity in lateral direction. ISO 23150:2023: Velocity {x, y, z} - object level - error (A.2.25)";
CM_ SG_ 54 VFC_Obj00_Ax "Object acceleration in longitudinal direction. ISO 23150:2023: Acceleration {x, y, z} (A.2.26)";
CM_ SG_ 54 VFC_Obj00_LightStatTurnIndicator "The detected direction indicator lights. Similar to ISO 23150:2023: Light status (A.2.35)";
CM_ SG_ 54 VFC_Obj00_Ay "Object acceleration in lateral direction. ISO 23150:2023: Acceleration {x, y, z} (A.2.26)";
CM_ SG_ 54 VFC_Obj00_AxStdDev "Standard deviation of Object acceleration in longitudinal direction. ISO 23150:2023: Acceleration {x, y, z} - error (A.2.27)";
CM_ SG_ 54 VFC_Obj00_AyStdDev "Standard deviation of Object acceleration in lateral direction. ISO 23150:2023: Acceleration {x, y, z} - error (A.2.27)";
CM_ SG_ 54 VFC_Obj00_MovementProbLat "Probability of object moving laterally (current state, not if moved at all in object history). Related to ISO 23150:2023: Movement status (A.2.32)";
CM_ SG_ 54 VFC_Obj00_MovementProbLong "Probability of object moving longitudinally (current state, not if moved at all in object history). Related to ISO 23150:2023: Movement status (A.2.32)";
CM_ SG_ 54 VFC_Obj00_2DAngPosEdgeLeft "Bounding box left edge in sensor coordinate system in ACCS coordinates; corresponds to tan(viewing angle of  object edge). ISO 23150:2023: Angular position {azimuth} (A.2.68)";
CM_ SG_ 54 VFC_Obj00_2DAngPosEdgeRight "Bounding box right edge in sensor coordinate system in ACCS coordinates; corresponds to tan(viewing angle of  object edge). ISO 23150:2023: Angular position {azimuth} (A.2.68)";
CM_ SG_ 54 VFC_Obj00_2DAngPosEdgeFar "Bounding box far edge in sensor coordinate system in ACCS coordinates; corresponds to tan(viewing angle of  object edge). ISO 23150:2023: Angular position {azimuth} (A.2.68)";
CM_ SG_ 54 VFC_Obj00_2DAngPosEdgeBot "Bounding box bottom edge in sensor coordinate system in ACCS coordinates; corresponds to tan(viewing angle of  object edge). Sign: upward direction negative value. ISO 23150:2023: Angular position {azimuth} (A.2.68)";
CM_ SG_ 54 VFC_Obj00_OutsideRoad "2D object is located outside road boundary (if signal is available)";
CM_ SG_ 54 VFC_Obj00_2DAngPosEdgeLeftStdDev "Standard deviation of the bounding box left edge";
CM_ SG_ 54 VFC_Obj00_2DAngPosEdgeRightStdDe "Standard deviation of the bounding box right edge";
CM_ SG_ 54 VFC_Obj00_2DAngPosEdgeFarStdDev "Standard deviation of the bounding box far edge";
CM_ SG_ 54 VFC_Obj00_2DAngPosEdgeBotStdDev "Standard deviation of the bounding box bottom edge";
CM_ SG_ 54 VFC_Obj00_2DNormVx "Normalised Object velocity in longitudinal direction (vx/dx_cam). Related to ISO 23150:2023: Angular velocity {azimuth} (A.2.69)";
CM_ SG_ 54 VFC_Obj00_2DNormVy "Normalised Object velocity in lateral direction (vy/dx_cam)";
CM_ SG_ 54 VFC_Obj00_2DNormAx "Normalised Object acceleration in longitudinal direction (ax/dx_cam)";
CM_ SG_ 54 VFC_Obj00_2DNormVxStdDev "Standard deviation of Normalised Object velocity in longitudinal direction";
CM_ SG_ 54 VFC_Obj00_MeasurementSource "Bitfield for the measurement programs from which this object originates
Bit 0: MOD
Bit 1: PDET
Bit 2: OFT
Bit 3: INVALID";
CM_ SG_ 54 VFC_Obj00_2DNormVyStdDev "Standard deviation of Normalised Object velocity in lateral direction";
CM_ SG_ 54 VFC_Obj00_2DNormAxStdDev "Standard deviation of Normalised Object acceleration in longitudinal direction";
CM_ SG_ 54 VFC_Obj00_2DScaleChange "Change in scale of the object in sensor's projection plane. ISO 23150:2023: Scale change - object level (A.2.70)";
CM_ SG_ 54 VFC_Obj00_2DScaleChangeStdDev "Standard deviation of object scale change";
CM_ SG_ 54 VFC_Obj00_Reliability "The bitfield shows if the signal quality is assumed to be sufficient for functions with safety target -no false positives-
Bit 0: DYNAMIC
Bit 1: SEMSEG_SURFACE
Bit 2: WDD_CRITICAL
Bit 3: GOD_CONFIRMED
Bit 4: RESTRICTED
Bit 5: ISO26262_SAFE";
CM_ SG_ 54 VFC_Obj00_LightStatBrakeLight "The number of detected lights. More confident if more lights are detected. Similar to ISO 23150:2023: Light status (A.2.35)";
CM_ SG_ 54 VFC_Obj00_OutsideRoadMeasStatus "2D object outside road boundary measurement status, indicator if it is measured or predicted (if signal is available)";
CM_ SG_ 54 VFC_Obj00_Oncoming "Object is oncoming (if signal is available)";
CM_ SG_ 54 VFC_Obj00_OncomingMeasStatus "Object oncoming measurement status, indicator if it is measured or predicted (if signal is available)";
CM_ SG_ 54 VFC_Obj00_MovementStanding "Object is standing (if signal is available). Related to ISO 23150:2023: Movement status (A.2.32)";
CM_ SG_ 54 VFC_Obj00_MovementStandingMeasSt "Object standing measurement status, indicator if it is measured or predicted (if signal is available)";
CM_ SG_ 54 VFC_Obj00_MovementObserved "Object has been observed moving over the ground since it was first detected (if signal is available). Related to ISO 23150:2023: Movement status (A.2.32)";
CM_ SG_ 54 VFC_Obj00_MovementObservedMeasSt "Measurement status for object has been observed moving (if signal is available)";
CM_ SG_ 54 VFC_Obj00_TargetObjTypeAcc "2D target object type for ACC (if signal is available)";
CM_ SG_ 54 VFC_Obj00_TargetObjTypeAccConf "Confidence of 2D target object type detection for ACC (if signal is available)";
CM_ SG_ 55 VFC_Obj01_CRC "CRC - Autosar E2E Profile 5";
CM_ SG_ 55 VFC_Obj01_AliveCtr "Alive counter - Autosar E2E Profile 5";
CM_ SG_ 55 VFC_Obj01_ProtBlockCtr "Protocol-Signal: Block-Counter";
CM_ SG_ 55 VFC_Obj01_ExistProb "Object existence probability. ISO 23150:2023: Existence probability - object level (A.2.1)";
CM_ SG_ 55 VFC_Obj01_MeasurementStatus "Indicator if the object detected is measured or predicted. ISO 23150:2023: Measurement status - object level (A.2.9)";
CM_ SG_ 55 VFC_Obj01_ObjId "Unique Object ID. ISO 23150:2023: Object ID (A.2.2)";
CM_ SG_ 55 VFC_Obj01_Type "Classification of the object. ISO 23150:2023: Potentially moving object classification type (A.2.12)";
CM_ SG_ 55 VFC_Obj01_TypeConf "Confidence of the classified object type. ISO 23150:2023: Potentially moving object classification type - confidence (A.2.13)";
CM_ SG_ 55 VFC_Obj01_VisibleView "The visible view of the detected object. Reference point is in the middle of CLASSIC (front/rear) or SIDE (left/right). Related to ISO 23150:2023: Reference point (A.2.14)";
CM_ SG_ 55 VFC_Obj01_ClassifiedView "The classified view of object to be used in connection with VisibleView and Heading angle. Related to ISO 23150:2023: Reference point (A.2.14)";
CM_ SG_ 55 VFC_Obj01_Px "Object distance in longitudinal direction. ISO 23150:2023: Position - object level {x, y, z} (A.2.15)";
CM_ SG_ 55 VFC_Obj01_Py "Object distance in lateral direction. ISO 23150:2023: Position - object level {x, y, z} (A.2.15)";
CM_ SG_ 55 VFC_Obj01_PxStdDev "Standard deviation of Object distance in longitudinal direction. ISO 23150:2023: Position - object level {x, y, z} - error (A.2.16)";
CM_ SG_ 55 VFC_Obj01_PyStdDev "Standard deviation of Object distance in lateral direction. ISO 23150:2023: Position - object level {x, y, z} - error (A.2.16)";
CM_ SG_ 55 VFC_Obj01_OrientationYaw "Heading angle of the object. ISO 23150:2023: Orientation {yaw, pitch, roll} (A.2.17)";
CM_ SG_ 55 VFC_Obj01_OrientationYawStdDev "Standard deviation of object Heading angle. ISO 23150:2023: Orientation {yaw, pitch, roll} - error (A.2.18)";
CM_ SG_ 55 VFC_Obj01_Length "Length of the object. ISO 23150:2023: Bounding box extent {length, width, height} (A.2.20)";
CM_ SG_ 55 VFC_Obj01_Width "Width of the object. ISO 23150:2023: Bounding box extent {length, width, height} (A.2.20)";
CM_ SG_ 55 VFC_Obj01_Height "Height of the object. ISO 23150:2023: Bounding box extent {length, width, height} (A.2.20)";
CM_ SG_ 55 VFC_Obj01_LengthStdDev "Standard deviation of object length. ISO 23150:2023: Bounding box extent {length, width, height} - error (A.2.21)";
CM_ SG_ 55 VFC_Obj01_WidthStdDev "Standard deviation of object width. ISO 23150:2023: Bounding box extent {length, width, height} - error (A.2.21)";
CM_ SG_ 55 VFC_Obj01_HeightStdDev "Standard deviation of object height. ISO 23150:2023: Bounding box extent {length, width, height} - error (A.2.21)";
CM_ SG_ 55 VFC_Obj01_Vx "Object velocity in longitudinal direction. ISO 23150:2023: Velocity {x, y, z} - object level (A.2.24)";
CM_ SG_ 55 VFC_Obj01_Vy "Object velocity in lateral direction. ISO 23150:2023: Velocity {x, y, z} - object level (A.2.24)";
CM_ SG_ 55 VFC_Obj01_VxStdDev "Standard deviation of Object velocity in longitudinal direction. ISO 23150:2023: Velocity {x, y, z} - object level - error (A.2.25)";
CM_ SG_ 55 VFC_Obj01_VyStdDev "Standard deviation of Object velocity in lateral direction. ISO 23150:2023: Velocity {x, y, z} - object level - error (A.2.25)";
CM_ SG_ 55 VFC_Obj01_Ax "Object acceleration in longitudinal direction. ISO 23150:2023: Acceleration {x, y, z} (A.2.26)";
CM_ SG_ 55 VFC_Obj01_LightStatTurnIndicator "The detected direction indicator lights. Similar to ISO 23150:2023: Light status (A.2.35)";
CM_ SG_ 55 VFC_Obj01_Ay "Object acceleration in lateral direction. ISO 23150:2023: Acceleration {x, y, z} (A.2.26)";
CM_ SG_ 55 VFC_Obj01_AxStdDev "Standard deviation of Object acceleration in longitudinal direction. ISO 23150:2023: Acceleration {x, y, z} - error (A.2.27)";
CM_ SG_ 55 VFC_Obj01_AyStdDev "Standard deviation of Object acceleration in lateral direction. ISO 23150:2023: Acceleration {x, y, z} - error (A.2.27)";
CM_ SG_ 55 VFC_Obj01_MovementProbLat "Probability of object moving laterally (current state, not if moved at all in object history). Related to ISO 23150:2023: Movement status (A.2.32)";
CM_ SG_ 55 VFC_Obj01_MovementProbLong "Probability of object moving longitudinally (current state, not if moved at all in object history). Related to ISO 23150:2023: Movement status (A.2.32)";
CM_ SG_ 55 VFC_Obj01_2DAngPosEdgeLeft "Bounding box left edge in sensor coordinate system in ACCS coordinates; corresponds to tan(viewing angle of  object edge). ISO 23150:2023: Angular position {azimuth} (A.2.68)";
CM_ SG_ 55 VFC_Obj01_2DAngPosEdgeRight "Bounding box right edge in sensor coordinate system in ACCS coordinates; corresponds to tan(viewing angle of  object edge). ISO 23150:2023: Angular position {azimuth} (A.2.68)";
CM_ SG_ 55 VFC_Obj01_2DAngPosEdgeFar "Bounding box far edge in sensor coordinate system in ACCS coordinates; corresponds to tan(viewing angle of  object edge). ISO 23150:2023: Angular position {azimuth} (A.2.68)";
CM_ SG_ 55 VFC_Obj01_2DAngPosEdgeBot "Bounding box bottom edge in sensor coordinate system in ACCS coordinates; corresponds to tan(viewing angle of  object edge). Sign: upward direction negative value. ISO 23150:2023: Angular position {azimuth} (A.2.68)";
CM_ SG_ 55 VFC_Obj01_OutsideRoad "2D object is located outside road boundary (if signal is available)";
CM_ SG_ 55 VFC_Obj01_2DAngPosEdgeLeftStdDev "Standard deviation of the bounding box left edge";
CM_ SG_ 55 VFC_Obj01_2DAngPosEdgeRightStdDe "Standard deviation of the bounding box right edge";
CM_ SG_ 55 VFC_Obj01_2DAngPosEdgeFarStdDev "Standard deviation of the bounding box far edge";
CM_ SG_ 55 VFC_Obj01_2DAngPosEdgeBotStdDev "Standard deviation of the bounding box bottom edge";
CM_ SG_ 55 VFC_Obj01_2DNormVx "Normalised Object velocity in longitudinal direction (vx/dx_cam). Related to ISO 23150:2023: Angular velocity {azimuth} (A.2.69)";
CM_ SG_ 55 VFC_Obj01_2DNormVy "Normalised Object velocity in lateral direction (vy/dx_cam)";
CM_ SG_ 55 VFC_Obj01_2DNormAx "Normalised Object acceleration in longitudinal direction (ax/dx_cam)";
CM_ SG_ 55 VFC_Obj01_2DNormVxStdDev "Standard deviation of Normalised Object velocity in longitudinal direction";
CM_ SG_ 55 VFC_Obj01_MeasurementSource "Bitfield for the measurement programs from which this object originates
Bit 0: MOD
Bit 1: PDET
Bit 2: OFT
Bit 3: INVALID";
CM_ SG_ 55 VFC_Obj01_2DNormVyStdDev "Standard deviation of Normalised Object velocity in lateral direction";
CM_ SG_ 55 VFC_Obj01_2DNormAxStdDev "Standard deviation of Normalised Object acceleration in longitudinal direction";
CM_ SG_ 55 VFC_Obj01_2DScaleChange "Change in scale of the object in sensor's projection plane. ISO 23150:2023: Scale change - object level (A.2.70)";
CM_ SG_ 55 VFC_Obj01_2DScaleChangeStdDev "Standard deviation of object scale change";
CM_ SG_ 55 VFC_Obj01_Reliability "The bitfield shows if the signal quality is assumed to be sufficient for functions with safety target -no false positives-
Bit 0: DYNAMIC
Bit 1: SEMSEG_SURFACE
Bit 2: WDD_CRITICAL
Bit 3: GOD_CONFIRMED
Bit 4: RESTRICTED
Bit 5: ISO26262_SAFE";
CM_ SG_ 55 VFC_Obj01_LightStatBrakeLight "The number of detected lights. More confident if more lights are detected. Similar to ISO 23150:2023: Light status (A.2.35)";
CM_ SG_ 55 VFC_Obj01_OutsideRoadMeasStatus "2D object outside road boundary measurement status, indicator if it is measured or predicted (if signal is available)";
CM_ SG_ 55 VFC_Obj01_Oncoming "Object is oncoming (if signal is available)";
CM_ SG_ 55 VFC_Obj01_OncomingMeasStatus "Object oncoming measurement status, indicator if it is measured or predicted (if signal is available)";
CM_ SG_ 55 VFC_Obj01_MovementStanding "Object is standing (if signal is available). Related to ISO 23150:2023: Movement status (A.2.32)";
CM_ SG_ 55 VFC_Obj01_MovementStandingMeasSt "Object standing measurement status, indicator if it is measured or predicted (if signal is available)";
CM_ SG_ 55 VFC_Obj01_MovementObserved "Object has been observed moving over the ground since it was first detected (if signal is available). Related to ISO 23150:2023: Movement status (A.2.32)";
CM_ SG_ 55 VFC_Obj01_MovementObservedMeasSt "Measurement status for object has been observed moving (if signal is available)";
CM_ SG_ 55 VFC_Obj01_TargetObjTypeAcc "2D target object type for ACC (if signal is available)";
CM_ SG_ 55 VFC_Obj01_TargetObjTypeAccConf "Confidence of 2D target object type detection for ACC (if signal is available)";
CM_ SG_ 56 VFC_Obj02_CRC "CRC - Autosar E2E Profile 5";
CM_ SG_ 56 VFC_Obj02_AliveCtr "Alive counter - Autosar E2E Profile 5";
CM_ SG_ 56 VFC_Obj02_ProtBlockCtr "Protocol-Signal: Block-Counter";
CM_ SG_ 56 VFC_Obj02_ExistProb "Object existence probability. ISO 23150:2023: Existence probability - object level (A.2.1)";
CM_ SG_ 56 VFC_Obj02_MeasurementStatus "Indicator if the object detected is measured or predicted. ISO 23150:2023: Measurement status - object level (A.2.9)";
CM_ SG_ 56 VFC_Obj02_ObjId "Unique Object ID. ISO 23150:2023: Object ID (A.2.2)";
CM_ SG_ 56 VFC_Obj02_Type "Classification of the object. ISO 23150:2023: Potentially moving object classification type (A.2.12)";
CM_ SG_ 56 VFC_Obj02_TypeConf "Confidence of the classified object type. ISO 23150:2023: Potentially moving object classification type - confidence (A.2.13)";
CM_ SG_ 56 VFC_Obj02_VisibleView "The visible view of the detected object. Reference point is in the middle of CLASSIC (front/rear) or SIDE (left/right). Related to ISO 23150:2023: Reference point (A.2.14)";
CM_ SG_ 56 VFC_Obj02_ClassifiedView "The classified view of object to be used in connection with VisibleView and Heading angle. Related to ISO 23150:2023: Reference point (A.2.14)";
CM_ SG_ 56 VFC_Obj02_Px "Object distance in longitudinal direction. ISO 23150:2023: Position - object level {x, y, z} (A.2.15)";
CM_ SG_ 56 VFC_Obj02_Py "Object distance in lateral direction. ISO 23150:2023: Position - object level {x, y, z} (A.2.15)";
CM_ SG_ 56 VFC_Obj02_PxStdDev "Standard deviation of Object distance in longitudinal direction. ISO 23150:2023: Position - object level {x, y, z} - error (A.2.16)";
CM_ SG_ 56 VFC_Obj02_PyStdDev "Standard deviation of Object distance in lateral direction. ISO 23150:2023: Position - object level {x, y, z} - error (A.2.16)";
CM_ SG_ 56 VFC_Obj02_OrientationYaw "Heading angle of the object. ISO 23150:2023: Orientation {yaw, pitch, roll} (A.2.17)";
CM_ SG_ 56 VFC_Obj02_OrientationYawStdDev "Standard deviation of object Heading angle. ISO 23150:2023: Orientation {yaw, pitch, roll} - error (A.2.18)";
CM_ SG_ 56 VFC_Obj02_Length "Length of the object. ISO 23150:2023: Bounding box extent {length, width, height} (A.2.20)";
CM_ SG_ 56 VFC_Obj02_Width "Width of the object. ISO 23150:2023: Bounding box extent {length, width, height} (A.2.20)";
CM_ SG_ 56 VFC_Obj02_Height "Height of the object. ISO 23150:2023: Bounding box extent {length, width, height} (A.2.20)";
CM_ SG_ 56 VFC_Obj02_LengthStdDev "Standard deviation of object length. ISO 23150:2023: Bounding box extent {length, width, height} - error (A.2.21)";
CM_ SG_ 56 VFC_Obj02_WidthStdDev "Standard deviation of object width. ISO 23150:2023: Bounding box extent {length, width, height} - error (A.2.21)";
CM_ SG_ 56 VFC_Obj02_HeightStdDev "Standard deviation of object height. ISO 23150:2023: Bounding box extent {length, width, height} - error (A.2.21)";
CM_ SG_ 56 VFC_Obj02_Vx "Object velocity in longitudinal direction. ISO 23150:2023: Velocity {x, y, z} - object level (A.2.24)";
CM_ SG_ 56 VFC_Obj02_Vy "Object velocity in lateral direction. ISO 23150:2023: Velocity {x, y, z} - object level (A.2.24)";
CM_ SG_ 56 VFC_Obj02_VxStdDev "Standard deviation of Object velocity in longitudinal direction. ISO 23150:2023: Velocity {x, y, z} - object level - error (A.2.25)";
CM_ SG_ 56 VFC_Obj02_VyStdDev "Standard deviation of Object velocity in lateral direction. ISO 23150:2023: Velocity {x, y, z} - object level - error (A.2.25)";
CM_ SG_ 56 VFC_Obj02_Ax "Object acceleration in longitudinal direction. ISO 23150:2023: Acceleration {x, y, z} (A.2.26)";
CM_ SG_ 56 VFC_Obj02_LightStatTurnIndicator "The detected direction indicator lights. Similar to ISO 23150:2023: Light status (A.2.35)";
CM_ SG_ 56 VFC_Obj02_Ay "Object acceleration in lateral direction. ISO 23150:2023: Acceleration {x, y, z} (A.2.26)";
CM_ SG_ 56 VFC_Obj02_AxStdDev "Standard deviation of Object acceleration in longitudinal direction. ISO 23150:2023: Acceleration {x, y, z} - error (A.2.27)";
CM_ SG_ 56 VFC_Obj02_AyStdDev "Standard deviation of Object acceleration in lateral direction. ISO 23150:2023: Acceleration {x, y, z} - error (A.2.27)";
CM_ SG_ 56 VFC_Obj02_MovementProbLat "Probability of object moving laterally (current state, not if moved at all in object history). Related to ISO 23150:2023: Movement status (A.2.32)";
CM_ SG_ 56 VFC_Obj02_MovementProbLong "Probability of object moving longitudinally (current state, not if moved at all in object history). Related to ISO 23150:2023: Movement status (A.2.32)";
CM_ SG_ 56 VFC_Obj02_2DAngPosEdgeLeft "Bounding box left edge in sensor coordinate system in ACCS coordinates; corresponds to tan(viewing angle of  object edge). ISO 23150:2023: Angular position {azimuth} (A.2.68)";
CM_ SG_ 56 VFC_Obj02_2DAngPosEdgeRight "Bounding box right edge in sensor coordinate system in ACCS coordinates; corresponds to tan(viewing angle of  object edge). ISO 23150:2023: Angular position {azimuth} (A.2.68)";
CM_ SG_ 56 VFC_Obj02_2DAngPosEdgeFar "Bounding box far edge in sensor coordinate system in ACCS coordinates; corresponds to tan(viewing angle of  object edge). ISO 23150:2023: Angular position {azimuth} (A.2.68)";
CM_ SG_ 56 VFC_Obj02_2DAngPosEdgeBot "Bounding box bottom edge in sensor coordinate system in ACCS coordinates; corresponds to tan(viewing angle of  object edge). Sign: upward direction negative value. ISO 23150:2023: Angular position {azimuth} (A.2.68)";
CM_ SG_ 56 VFC_Obj02_OutsideRoad "2D object is located outside road boundary (if signal is available)";
CM_ SG_ 56 VFC_Obj02_2DAngPosEdgeLeftStdDev "Standard deviation of the bounding box left edge";
CM_ SG_ 56 VFC_Obj02_2DAngPosEdgeRightStdDe "Standard deviation of the bounding box right edge";
CM_ SG_ 56 VFC_Obj02_2DAngPosEdgeFarStdDev "Standard deviation of the bounding box far edge";
CM_ SG_ 56 VFC_Obj02_2DAngPosEdgeBotStdDev "Standard deviation of the bounding box bottom edge";
CM_ SG_ 56 VFC_Obj02_2DNormVx "Normalised Object velocity in longitudinal direction (vx/dx_cam). Related to ISO 23150:2023: Angular velocity {azimuth} (A.2.69)";
CM_ SG_ 56 VFC_Obj02_2DNormVy "Normalised Object velocity in lateral direction (vy/dx_cam)";
CM_ SG_ 56 VFC_Obj02_2DNormAx "Normalised Object acceleration in longitudinal direction (ax/dx_cam)";
CM_ SG_ 56 VFC_Obj02_2DNormVxStdDev "Standard deviation of Normalised Object velocity in longitudinal direction";
CM_ SG_ 56 VFC_Obj02_MeasurementSource "Bitfield for the measurement programs from which this object originates
Bit 0: MOD
Bit 1: PDET
Bit 2: OFT
Bit 3: INVALID";
CM_ SG_ 56 VFC_Obj02_2DNormVyStdDev "Standard deviation of Normalised Object velocity in lateral direction";
CM_ SG_ 56 VFC_Obj02_2DNormAxStdDev "Standard deviation of Normalised Object acceleration in longitudinal direction";
CM_ SG_ 56 VFC_Obj02_2DScaleChange "Change in scale of the object in sensor's projection plane. ISO 23150:2023: Scale change - object level (A.2.70)";
CM_ SG_ 56 VFC_Obj02_2DScaleChangeStdDev "Standard deviation of object scale change";
CM_ SG_ 56 VFC_Obj02_Reliability "The bitfield shows if the signal quality is assumed to be sufficient for functions with safety target -no false positives-
Bit 0: DYNAMIC
Bit 1: SEMSEG_SURFACE
Bit 2: WDD_CRITICAL
Bit 3: GOD_CONFIRMED
Bit 4: RESTRICTED
Bit 5: ISO26262_SAFE";
CM_ SG_ 56 VFC_Obj02_LightStatBrakeLight "The number of detected lights. More confident if more lights are detected. Similar to ISO 23150:2023: Light status (A.2.35)";
CM_ SG_ 56 VFC_Obj02_OutsideRoadMeasStatus "2D object outside road boundary measurement status, indicator if it is measured or predicted (if signal is available)";
CM_ SG_ 56 VFC_Obj02_Oncoming "Object is oncoming (if signal is available)";
CM_ SG_ 56 VFC_Obj02_OncomingMeasStatus "Object oncoming measurement status, indicator if it is measured or predicted (if signal is available)";
CM_ SG_ 56 VFC_Obj02_MovementStanding "Object is standing (if signal is available). Related to ISO 23150:2023: Movement status (A.2.32)";
CM_ SG_ 56 VFC_Obj02_MovementStandingMeasSt "Object standing measurement status, indicator if it is measured or predicted (if signal is available)";
CM_ SG_ 56 VFC_Obj02_MovementObserved "Object has been observed moving over the ground since it was first detected (if signal is available). Related to ISO 23150:2023: Movement status (A.2.32)";
CM_ SG_ 56 VFC_Obj02_MovementObservedMeasSt "Measurement status for object has been observed moving (if signal is available)";
CM_ SG_ 56 VFC_Obj02_TargetObjTypeAcc "2D target object type for ACC (if signal is available)";
CM_ SG_ 56 VFC_Obj02_TargetObjTypeAccConf "Confidence of 2D target object type detection for ACC (if signal is available)";
CM_ SG_ 57 VFC_Obj03_CRC "CRC - Autosar E2E Profile 5";
CM_ SG_ 57 VFC_Obj03_AliveCtr "Alive counter - Autosar E2E Profile 5";
CM_ SG_ 57 VFC_Obj03_ProtBlockCtr "Protocol-Signal: Block-Counter";
CM_ SG_ 57 VFC_Obj03_ExistProb "Object existence probability. ISO 23150:2023: Existence probability - object level (A.2.1)";
CM_ SG_ 57 VFC_Obj03_MeasurementStatus "Indicator if the object detected is measured or predicted. ISO 23150:2023: Measurement status - object level (A.2.9)";
CM_ SG_ 57 VFC_Obj03_ObjId "Unique Object ID. ISO 23150:2023: Object ID (A.2.2)";
CM_ SG_ 57 VFC_Obj03_Type "Classification of the object. ISO 23150:2023: Potentially moving object classification type (A.2.12)";
CM_ SG_ 57 VFC_Obj03_TypeConf "Confidence of the classified object type. ISO 23150:2023: Potentially moving object classification type - confidence (A.2.13)";
CM_ SG_ 57 VFC_Obj03_VisibleView "The visible view of the detected object. Reference point is in the middle of CLASSIC (front/rear) or SIDE (left/right). Related to ISO 23150:2023: Reference point (A.2.14)";
CM_ SG_ 57 VFC_Obj03_ClassifiedView "The classified view of object to be used in connection with VisibleView and Heading angle. Related to ISO 23150:2023: Reference point (A.2.14)";
CM_ SG_ 57 VFC_Obj03_Px "Object distance in longitudinal direction. ISO 23150:2023: Position - object level {x, y, z} (A.2.15)";
CM_ SG_ 57 VFC_Obj03_Py "Object distance in lateral direction. ISO 23150:2023: Position - object level {x, y, z} (A.2.15)";
CM_ SG_ 57 VFC_Obj03_PxStdDev "Standard deviation of Object distance in longitudinal direction. ISO 23150:2023: Position - object level {x, y, z} - error (A.2.16)";
CM_ SG_ 57 VFC_Obj03_PyStdDev "Standard deviation of Object distance in lateral direction. ISO 23150:2023: Position - object level {x, y, z} - error (A.2.16)";
CM_ SG_ 57 VFC_Obj03_OrientationYaw "Heading angle of the object. ISO 23150:2023: Orientation {yaw, pitch, roll} (A.2.17)";
CM_ SG_ 57 VFC_Obj03_OrientationYawStdDev "Standard deviation of object Heading angle. ISO 23150:2023: Orientation {yaw, pitch, roll} - error (A.2.18)";
CM_ SG_ 57 VFC_Obj03_Length "Length of the object. ISO 23150:2023: Bounding box extent {length, width, height} (A.2.20)";
CM_ SG_ 57 VFC_Obj03_Width "Width of the object. ISO 23150:2023: Bounding box extent {length, width, height} (A.2.20)";
CM_ SG_ 57 VFC_Obj03_Height "Height of the object. ISO 23150:2023: Bounding box extent {length, width, height} (A.2.20)";
CM_ SG_ 57 VFC_Obj03_LengthStdDev "Standard deviation of object length. ISO 23150:2023: Bounding box extent {length, width, height} - error (A.2.21)";
CM_ SG_ 57 VFC_Obj03_WidthStdDev "Standard deviation of object width. ISO 23150:2023: Bounding box extent {length, width, height} - error (A.2.21)";
CM_ SG_ 57 VFC_Obj03_HeightStdDev "Standard deviation of object height. ISO 23150:2023: Bounding box extent {length, width, height} - error (A.2.21)";
CM_ SG_ 57 VFC_Obj03_Vx "Object velocity in longitudinal direction. ISO 23150:2023: Velocity {x, y, z} - object level (A.2.24)";
CM_ SG_ 57 VFC_Obj03_Vy "Object velocity in lateral direction. ISO 23150:2023: Velocity {x, y, z} - object level (A.2.24)";
CM_ SG_ 57 VFC_Obj03_VxStdDev "Standard deviation of Object velocity in longitudinal direction. ISO 23150:2023: Velocity {x, y, z} - object level - error (A.2.25)";
CM_ SG_ 57 VFC_Obj03_VyStdDev "Standard deviation of Object velocity in lateral direction. ISO 23150:2023: Velocity {x, y, z} - object level - error (A.2.25)";
CM_ SG_ 57 VFC_Obj03_Ax "Object acceleration in longitudinal direction. ISO 23150:2023: Acceleration {x, y, z} (A.2.26)";
CM_ SG_ 57 VFC_Obj03_LightStatTurnIndicator "The detected direction indicator lights. Similar to ISO 23150:2023: Light status (A.2.35)";
CM_ SG_ 57 VFC_Obj03_Ay "Object acceleration in lateral direction. ISO 23150:2023: Acceleration {x, y, z} (A.2.26)";
CM_ SG_ 57 VFC_Obj03_AxStdDev "Standard deviation of Object acceleration in longitudinal direction. ISO 23150:2023: Acceleration {x, y, z} - error (A.2.27)";
CM_ SG_ 57 VFC_Obj03_AyStdDev "Standard deviation of Object acceleration in lateral direction. ISO 23150:2023: Acceleration {x, y, z} - error (A.2.27)";
CM_ SG_ 57 VFC_Obj03_MovementProbLat "Probability of object moving laterally (current state, not if moved at all in object history). Related to ISO 23150:2023: Movement status (A.2.32)";
CM_ SG_ 57 VFC_Obj03_MovementProbLong "Probability of object moving longitudinally (current state, not if moved at all in object history). Related to ISO 23150:2023: Movement status (A.2.32)";
CM_ SG_ 57 VFC_Obj03_2DAngPosEdgeLeft "Bounding box left edge in sensor coordinate system in ACCS coordinates; corresponds to tan(viewing angle of  object edge). ISO 23150:2023: Angular position {azimuth} (A.2.68)";
CM_ SG_ 57 VFC_Obj03_2DAngPosEdgeRight "Bounding box right edge in sensor coordinate system in ACCS coordinates; corresponds to tan(viewing angle of  object edge). ISO 23150:2023: Angular position {azimuth} (A.2.68)";
CM_ SG_ 57 VFC_Obj03_2DAngPosEdgeFar "Bounding box far edge in sensor coordinate system in ACCS coordinates; corresponds to tan(viewing angle of  object edge). ISO 23150:2023: Angular position {azimuth} (A.2.68)";
CM_ SG_ 57 VFC_Obj03_2DAngPosEdgeBot "Bounding box bottom edge in sensor coordinate system in ACCS coordinates; corresponds to tan(viewing angle of  object edge). Sign: upward direction negative value. ISO 23150:2023: Angular position {azimuth} (A.2.68)";
CM_ SG_ 57 VFC_Obj03_OutsideRoad "2D object is located outside road boundary (if signal is available)";
CM_ SG_ 57 VFC_Obj03_2DAngPosEdgeLeftStdDev "Standard deviation of the bounding box left edge";
CM_ SG_ 57 VFC_Obj03_2DAngPosEdgeRightStdDe "Standard deviation of the bounding box right edge";
CM_ SG_ 57 VFC_Obj03_2DAngPosEdgeFarStdDev "Standard deviation of the bounding box far edge";
CM_ SG_ 57 VFC_Obj03_2DAngPosEdgeBotStdDev "Standard deviation of the bounding box bottom edge";
CM_ SG_ 57 VFC_Obj03_2DNormVx "Normalised Object velocity in longitudinal direction (vx/dx_cam). Related to ISO 23150:2023: Angular velocity {azimuth} (A.2.69)";
CM_ SG_ 57 VFC_Obj03_2DNormVy "Normalised Object velocity in lateral direction (vy/dx_cam)";
CM_ SG_ 57 VFC_Obj03_2DNormAx "Normalised Object acceleration in longitudinal direction (ax/dx_cam)";
CM_ SG_ 57 VFC_Obj03_2DNormVxStdDev "Standard deviation of Normalised Object velocity in longitudinal direction";
CM_ SG_ 57 VFC_Obj03_MeasurementSource "Bitfield for the measurement programs from which this object originates
Bit 0: MOD
Bit 1: PDET
Bit 2: OFT
Bit 3: INVALID";
CM_ SG_ 57 VFC_Obj03_2DNormVyStdDev "Standard deviation of Normalised Object velocity in lateral direction";
CM_ SG_ 57 VFC_Obj03_2DNormAxStdDev "Standard deviation of Normalised Object acceleration in longitudinal direction";
CM_ SG_ 57 VFC_Obj03_2DScaleChange "Change in scale of the object in sensor's projection plane. ISO 23150:2023: Scale change - object level (A.2.70)";
CM_ SG_ 57 VFC_Obj03_2DScaleChangeStdDev "Standard deviation of object scale change";
CM_ SG_ 57 VFC_Obj03_Reliability "The bitfield shows if the signal quality is assumed to be sufficient for functions with safety target -no false positives-
Bit 0: DYNAMIC
Bit 1: SEMSEG_SURFACE
Bit 2: WDD_CRITICAL
Bit 3: GOD_CONFIRMED
Bit 4: RESTRICTED
Bit 5: ISO26262_SAFE";
CM_ SG_ 57 VFC_Obj03_LightStatBrakeLight "The number of detected lights. More confident if more lights are detected. Similar to ISO 23150:2023: Light status (A.2.35)";
CM_ SG_ 57 VFC_Obj03_OutsideRoadMeasStatus "2D object outside road boundary measurement status, indicator if it is measured or predicted (if signal is available)";
CM_ SG_ 57 VFC_Obj03_Oncoming "Object is oncoming (if signal is available)";
CM_ SG_ 57 VFC_Obj03_OncomingMeasStatus "Object oncoming measurement status, indicator if it is measured or predicted (if signal is available)";
CM_ SG_ 57 VFC_Obj03_MovementStanding "Object is standing (if signal is available). Related to ISO 23150:2023: Movement status (A.2.32)";
CM_ SG_ 57 VFC_Obj03_MovementStandingMeasSt "Object standing measurement status, indicator if it is measured or predicted (if signal is available)";
CM_ SG_ 57 VFC_Obj03_MovementObserved "Object has been observed moving over the ground since it was first detected (if signal is available). Related to ISO 23150:2023: Movement status (A.2.32)";
CM_ SG_ 57 VFC_Obj03_MovementObservedMeasSt "Measurement status for object has been observed moving (if signal is available)";
CM_ SG_ 57 VFC_Obj03_TargetObjTypeAcc "2D target object type for ACC (if signal is available)";
CM_ SG_ 57 VFC_Obj03_TargetObjTypeAccConf "Confidence of 2D target object type detection for ACC (if signal is available)";
CM_ SG_ 58 VFC_Obj04_CRC "CRC - Autosar E2E Profile 5";
CM_ SG_ 58 VFC_Obj04_AliveCtr "Alive counter - Autosar E2E Profile 5";
CM_ SG_ 58 VFC_Obj04_ProtBlockCtr "Protocol-Signal: Block-Counter";
CM_ SG_ 58 VFC_Obj04_ExistProb "Object existence probability. ISO 23150:2023: Existence probability - object level (A.2.1)";
CM_ SG_ 58 VFC_Obj04_MeasurementStatus "Indicator if the object detected is measured or predicted. ISO 23150:2023: Measurement status - object level (A.2.9)";
CM_ SG_ 58 VFC_Obj04_ObjId "Unique Object ID. ISO 23150:2023: Object ID (A.2.2)";
CM_ SG_ 58 VFC_Obj04_Type "Classification of the object. ISO 23150:2023: Potentially moving object classification type (A.2.12)";
CM_ SG_ 58 VFC_Obj04_TypeConf "Confidence of the classified object type. ISO 23150:2023: Potentially moving object classification type - confidence (A.2.13)";
CM_ SG_ 58 VFC_Obj04_VisibleView "The visible view of the detected object. Reference point is in the middle of CLASSIC (front/rear) or SIDE (left/right). Related to ISO 23150:2023: Reference point (A.2.14)";
CM_ SG_ 58 VFC_Obj04_ClassifiedView "The classified view of object to be used in connection with VisibleView and Heading angle. Related to ISO 23150:2023: Reference point (A.2.14)";
CM_ SG_ 58 VFC_Obj04_Px "Object distance in longitudinal direction. ISO 23150:2023: Position - object level {x, y, z} (A.2.15)";
CM_ SG_ 58 VFC_Obj04_Py "Object distance in lateral direction. ISO 23150:2023: Position - object level {x, y, z} (A.2.15)";
CM_ SG_ 58 VFC_Obj04_PxStdDev "Standard deviation of Object distance in longitudinal direction. ISO 23150:2023: Position - object level {x, y, z} - error (A.2.16)";
CM_ SG_ 58 VFC_Obj04_PyStdDev "Standard deviation of Object distance in lateral direction. ISO 23150:2023: Position - object level {x, y, z} - error (A.2.16)";
CM_ SG_ 58 VFC_Obj04_OrientationYaw "Heading angle of the object. ISO 23150:2023: Orientation {yaw, pitch, roll} (A.2.17)";
CM_ SG_ 58 VFC_Obj04_OrientationYawStdDev "Standard deviation of object Heading angle. ISO 23150:2023: Orientation {yaw, pitch, roll} - error (A.2.18)";
CM_ SG_ 58 VFC_Obj04_Length "Length of the object. ISO 23150:2023: Bounding box extent {length, width, height} (A.2.20)";
CM_ SG_ 58 VFC_Obj04_Width "Width of the object. ISO 23150:2023: Bounding box extent {length, width, height} (A.2.20)";
CM_ SG_ 58 VFC_Obj04_Height "Height of the object. ISO 23150:2023: Bounding box extent {length, width, height} (A.2.20)";
CM_ SG_ 58 VFC_Obj04_LengthStdDev "Standard deviation of object length. ISO 23150:2023: Bounding box extent {length, width, height} - error (A.2.21)";
CM_ SG_ 58 VFC_Obj04_WidthStdDev "Standard deviation of object width. ISO 23150:2023: Bounding box extent {length, width, height} - error (A.2.21)";
CM_ SG_ 58 VFC_Obj04_HeightStdDev "Standard deviation of object height. ISO 23150:2023: Bounding box extent {length, width, height} - error (A.2.21)";
CM_ SG_ 58 VFC_Obj04_Vx "Object velocity in longitudinal direction. ISO 23150:2023: Velocity {x, y, z} - object level (A.2.24)";
CM_ SG_ 58 VFC_Obj04_Vy "Object velocity in lateral direction. ISO 23150:2023: Velocity {x, y, z} - object level (A.2.24)";
CM_ SG_ 58 VFC_Obj04_VxStdDev "Standard deviation of Object velocity in longitudinal direction. ISO 23150:2023: Velocity {x, y, z} - object level - error (A.2.25)";
CM_ SG_ 58 VFC_Obj04_VyStdDev "Standard deviation of Object velocity in lateral direction. ISO 23150:2023: Velocity {x, y, z} - object level - error (A.2.25)";
CM_ SG_ 58 VFC_Obj04_Ax "Object acceleration in longitudinal direction. ISO 23150:2023: Acceleration {x, y, z} (A.2.26)";
CM_ SG_ 58 VFC_Obj04_LightStatTurnIndicator "The detected direction indicator lights. Similar to ISO 23150:2023: Light status (A.2.35)";
CM_ SG_ 58 VFC_Obj04_Ay "Object acceleration in lateral direction. ISO 23150:2023: Acceleration {x, y, z} (A.2.26)";
CM_ SG_ 58 VFC_Obj04_AxStdDev "Standard deviation of Object acceleration in longitudinal direction. ISO 23150:2023: Acceleration {x, y, z} - error (A.2.27)";
CM_ SG_ 58 VFC_Obj04_AyStdDev "Standard deviation of Object acceleration in lateral direction. ISO 23150:2023: Acceleration {x, y, z} - error (A.2.27)";
CM_ SG_ 58 VFC_Obj04_MovementProbLat "Probability of object moving laterally (current state, not if moved at all in object history). Related to ISO 23150:2023: Movement status (A.2.32)";
CM_ SG_ 58 VFC_Obj04_MovementProbLong "Probability of object moving longitudinally (current state, not if moved at all in object history). Related to ISO 23150:2023: Movement status (A.2.32)";
CM_ SG_ 58 VFC_Obj04_2DAngPosEdgeLeft "Bounding box left edge in sensor coordinate system in ACCS coordinates; corresponds to tan(viewing angle of  object edge). ISO 23150:2023: Angular position {azimuth} (A.2.68)";
CM_ SG_ 58 VFC_Obj04_2DAngPosEdgeRight "Bounding box right edge in sensor coordinate system in ACCS coordinates; corresponds to tan(viewing angle of  object edge). ISO 23150:2023: Angular position {azimuth} (A.2.68)";
CM_ SG_ 58 VFC_Obj04_2DAngPosEdgeFar "Bounding box far edge in sensor coordinate system in ACCS coordinates; corresponds to tan(viewing angle of  object edge). ISO 23150:2023: Angular position {azimuth} (A.2.68)";
CM_ SG_ 58 VFC_Obj04_2DAngPosEdgeBot "Bounding box bottom edge in sensor coordinate system in ACCS coordinates; corresponds to tan(viewing angle of  object edge). Sign: upward direction negative value. ISO 23150:2023: Angular position {azimuth} (A.2.68)";
CM_ SG_ 58 VFC_Obj04_OutsideRoad "2D object is located outside road boundary (if signal is available)";
CM_ SG_ 58 VFC_Obj04_2DAngPosEdgeLeftStdDev "Standard deviation of the bounding box left edge";
CM_ SG_ 58 VFC_Obj04_2DAngPosEdgeRightStdDe "Standard deviation of the bounding box right edge";
CM_ SG_ 58 VFC_Obj04_2DAngPosEdgeFarStdDev "Standard deviation of the bounding box far edge";
CM_ SG_ 58 VFC_Obj04_2DAngPosEdgeBotStdDev "Standard deviation of the bounding box bottom edge";
CM_ SG_ 58 VFC_Obj04_2DNormVx "Normalised Object velocity in longitudinal direction (vx/dx_cam). Related to ISO 23150:2023: Angular velocity {azimuth} (A.2.69)";
CM_ SG_ 58 VFC_Obj04_2DNormVy "Normalised Object velocity in lateral direction (vy/dx_cam)";
CM_ SG_ 58 VFC_Obj04_2DNormAx "Normalised Object acceleration in longitudinal direction (ax/dx_cam)";
CM_ SG_ 58 VFC_Obj04_2DNormVxStdDev "Standard deviation of Normalised Object velocity in longitudinal direction";
CM_ SG_ 58 VFC_Obj04_MeasurementSource "Bitfield for the measurement programs from which this object originates
Bit 0: MOD
Bit 1: PDET
Bit 2: OFT
Bit 3: INVALID";
CM_ SG_ 58 VFC_Obj04_2DNormVyStdDev "Standard deviation of Normalised Object velocity in lateral direction";
CM_ SG_ 58 VFC_Obj04_2DNormAxStdDev "Standard deviation of Normalised Object acceleration in longitudinal direction";
CM_ SG_ 58 VFC_Obj04_2DScaleChange "Change in scale of the object in sensor's projection plane. ISO 23150:2023: Scale change - object level (A.2.70)";
CM_ SG_ 58 VFC_Obj04_2DScaleChangeStdDev "Standard deviation of object scale change";
CM_ SG_ 58 VFC_Obj04_Reliability "The bitfield shows if the signal quality is assumed to be sufficient for functions with safety target -no false positives-
Bit 0: DYNAMIC
Bit 1: SEMSEG_SURFACE
Bit 2: WDD_CRITICAL
Bit 3: GOD_CONFIRMED
Bit 4: RESTRICTED
Bit 5: ISO26262_SAFE";
CM_ SG_ 58 VFC_Obj04_LightStatBrakeLight "The number of detected lights. More confident if more lights are detected. Similar to ISO 23150:2023: Light status (A.2.35)";
CM_ SG_ 58 VFC_Obj04_OutsideRoadMeasStatus "2D object outside road boundary measurement status, indicator if it is measured or predicted (if signal is available)";
CM_ SG_ 58 VFC_Obj04_Oncoming "Object is oncoming (if signal is available)";
CM_ SG_ 58 VFC_Obj04_OncomingMeasStatus "Object oncoming measurement status, indicator if it is measured or predicted (if signal is available)";
CM_ SG_ 58 VFC_Obj04_MovementStanding "Object is standing (if signal is available). Related to ISO 23150:2023: Movement status (A.2.32)";
CM_ SG_ 58 VFC_Obj04_MovementStandingMeasSt "Object standing measurement status, indicator if it is measured or predicted (if signal is available)";
CM_ SG_ 58 VFC_Obj04_MovementObserved "Object has been observed moving over the ground since it was first detected (if signal is available). Related to ISO 23150:2023: Movement status (A.2.32)";
CM_ SG_ 58 VFC_Obj04_MovementObservedMeasSt "Measurement status for object has been observed moving (if signal is available)";
CM_ SG_ 58 VFC_Obj04_TargetObjTypeAcc "2D target object type for ACC (if signal is available)";
CM_ SG_ 58 VFC_Obj04_TargetObjTypeAccConf "Confidence of 2D target object type detection for ACC (if signal is available)";
CM_ SG_ 59 VFC_Obj05_CRC "CRC - Autosar E2E Profile 5";
CM_ SG_ 59 VFC_Obj05_AliveCtr "Alive counter - Autosar E2E Profile 5";
CM_ SG_ 59 VFC_Obj05_ProtBlockCtr "Protocol-Signal: Block-Counter";
CM_ SG_ 59 VFC_Obj05_ExistProb "Object existence probability. ISO 23150:2023: Existence probability - object level (A.2.1)";
CM_ SG_ 59 VFC_Obj05_MeasurementStatus "Indicator if the object detected is measured or predicted. ISO 23150:2023: Measurement status - object level (A.2.9)";
CM_ SG_ 59 VFC_Obj05_ObjId "Unique Object ID. ISO 23150:2023: Object ID (A.2.2)";
CM_ SG_ 59 VFC_Obj05_Type "Classification of the object. ISO 23150:2023: Potentially moving object classification type (A.2.12)";
CM_ SG_ 59 VFC_Obj05_TypeConf "Confidence of the classified object type. ISO 23150:2023: Potentially moving object classification type - confidence (A.2.13)";
CM_ SG_ 59 VFC_Obj05_VisibleView "The visible view of the detected object. Reference point is in the middle of CLASSIC (front/rear) or SIDE (left/right). Related to ISO 23150:2023: Reference point (A.2.14)";
CM_ SG_ 59 VFC_Obj05_ClassifiedView "The classified view of object to be used in connection with VisibleView and Heading angle. Related to ISO 23150:2023: Reference point (A.2.14)";
CM_ SG_ 59 VFC_Obj05_Px "Object distance in longitudinal direction. ISO 23150:2023: Position - object level {x, y, z} (A.2.15)";
CM_ SG_ 59 VFC_Obj05_Py "Object distance in lateral direction. ISO 23150:2023: Position - object level {x, y, z} (A.2.15)";
CM_ SG_ 59 VFC_Obj05_PxStdDev "Standard deviation of Object distance in longitudinal direction. ISO 23150:2023: Position - object level {x, y, z} - error (A.2.16)";
CM_ SG_ 59 VFC_Obj05_PyStdDev "Standard deviation of Object distance in lateral direction. ISO 23150:2023: Position - object level {x, y, z} - error (A.2.16)";
CM_ SG_ 59 VFC_Obj05_OrientationYaw "Heading angle of the object. ISO 23150:2023: Orientation {yaw, pitch, roll} (A.2.17)";
CM_ SG_ 59 VFC_Obj05_OrientationYawStdDev "Standard deviation of object Heading angle. ISO 23150:2023: Orientation {yaw, pitch, roll} - error (A.2.18)";
CM_ SG_ 59 VFC_Obj05_Length "Length of the object. ISO 23150:2023: Bounding box extent {length, width, height} (A.2.20)";
CM_ SG_ 59 VFC_Obj05_Width "Width of the object. ISO 23150:2023: Bounding box extent {length, width, height} (A.2.20)";
CM_ SG_ 59 VFC_Obj05_Height "Height of the object. ISO 23150:2023: Bounding box extent {length, width, height} (A.2.20)";
CM_ SG_ 59 VFC_Obj05_LengthStdDev "Standard deviation of object length. ISO 23150:2023: Bounding box extent {length, width, height} - error (A.2.21)";
CM_ SG_ 59 VFC_Obj05_WidthStdDev "Standard deviation of object width. ISO 23150:2023: Bounding box extent {length, width, height} - error (A.2.21)";
CM_ SG_ 59 VFC_Obj05_HeightStdDev "Standard deviation of object height. ISO 23150:2023: Bounding box extent {length, width, height} - error (A.2.21)";
CM_ SG_ 59 VFC_Obj05_Vx "Object velocity in longitudinal direction. ISO 23150:2023: Velocity {x, y, z} - object level (A.2.24)";
CM_ SG_ 59 VFC_Obj05_Vy "Object velocity in lateral direction. ISO 23150:2023: Velocity {x, y, z} - object level (A.2.24)";
CM_ SG_ 59 VFC_Obj05_VxStdDev "Standard deviation of Object velocity in longitudinal direction. ISO 23150:2023: Velocity {x, y, z} - object level - error (A.2.25)";
CM_ SG_ 59 VFC_Obj05_VyStdDev "Standard deviation of Object velocity in lateral direction. ISO 23150:2023: Velocity {x, y, z} - object level - error (A.2.25)";
CM_ SG_ 59 VFC_Obj05_Ax "Object acceleration in longitudinal direction. ISO 23150:2023: Acceleration {x, y, z} (A.2.26)";
CM_ SG_ 59 VFC_Obj05_LightStatTurnIndicator "The detected direction indicator lights. Similar to ISO 23150:2023: Light status (A.2.35)";
CM_ SG_ 59 VFC_Obj05_Ay "Object acceleration in lateral direction. ISO 23150:2023: Acceleration {x, y, z} (A.2.26)";
CM_ SG_ 59 VFC_Obj05_AxStdDev "Standard deviation of Object acceleration in longitudinal direction. ISO 23150:2023: Acceleration {x, y, z} - error (A.2.27)";
CM_ SG_ 59 VFC_Obj05_AyStdDev "Standard deviation of Object acceleration in lateral direction. ISO 23150:2023: Acceleration {x, y, z} - error (A.2.27)";
CM_ SG_ 59 VFC_Obj05_MovementProbLat "Probability of object moving laterally (current state, not if moved at all in object history). Related to ISO 23150:2023: Movement status (A.2.32)";
CM_ SG_ 59 VFC_Obj05_MovementProbLong "Probability of object moving longitudinally (current state, not if moved at all in object history). Related to ISO 23150:2023: Movement status (A.2.32)";
CM_ SG_ 59 VFC_Obj05_2DAngPosEdgeLeft "Bounding box left edge in sensor coordinate system in ACCS coordinates; corresponds to tan(viewing angle of  object edge). ISO 23150:2023: Angular position {azimuth} (A.2.68)";
CM_ SG_ 59 VFC_Obj05_2DAngPosEdgeRight "Bounding box right edge in sensor coordinate system in ACCS coordinates; corresponds to tan(viewing angle of  object edge). ISO 23150:2023: Angular position {azimuth} (A.2.68)";
CM_ SG_ 59 VFC_Obj05_2DAngPosEdgeFar "Bounding box far edge in sensor coordinate system in ACCS coordinates; corresponds to tan(viewing angle of  object edge). ISO 23150:2023: Angular position {azimuth} (A.2.68)";
CM_ SG_ 59 VFC_Obj05_2DAngPosEdgeBot "Bounding box bottom edge in sensor coordinate system in ACCS coordinates; corresponds to tan(viewing angle of  object edge). Sign: upward direction negative value. ISO 23150:2023: Angular position {azimuth} (A.2.68)";
CM_ SG_ 59 VFC_Obj05_OutsideRoad "2D object is located outside road boundary (if signal is available)";
CM_ SG_ 59 VFC_Obj05_2DAngPosEdgeLeftStdDev "Standard deviation of the bounding box left edge";
CM_ SG_ 59 VFC_Obj05_2DAngPosEdgeRightStdDe "Standard deviation of the bounding box right edge";
CM_ SG_ 59 VFC_Obj05_2DAngPosEdgeFarStdDev "Standard deviation of the bounding box far edge";
CM_ SG_ 59 VFC_Obj05_2DAngPosEdgeBotStdDev "Standard deviation of the bounding box bottom edge";
CM_ SG_ 59 VFC_Obj05_2DNormVx "Normalised Object velocity in longitudinal direction (vx/dx_cam). Related to ISO 23150:2023: Angular velocity {azimuth} (A.2.69)";
CM_ SG_ 59 VFC_Obj05_2DNormVy "Normalised Object velocity in lateral direction (vy/dx_cam)";
CM_ SG_ 59 VFC_Obj05_2DNormAx "Normalised Object acceleration in longitudinal direction (ax/dx_cam)";
CM_ SG_ 59 VFC_Obj05_2DNormVxStdDev "Standard deviation of Normalised Object velocity in longitudinal direction";
CM_ SG_ 59 VFC_Obj05_MeasurementSource "Bitfield for the measurement programs from which this object originates
Bit 0: MOD
Bit 1: PDET
Bit 2: OFT
Bit 3: INVALID";
CM_ SG_ 59 VFC_Obj05_2DNormVyStdDev "Standard deviation of Normalised Object velocity in lateral direction";
CM_ SG_ 59 VFC_Obj05_2DNormAxStdDev "Standard deviation of Normalised Object acceleration in longitudinal direction";
CM_ SG_ 59 VFC_Obj05_2DScaleChange "Change in scale of the object in sensor's projection plane. ISO 23150:2023: Scale change - object level (A.2.70)";
CM_ SG_ 59 VFC_Obj05_2DScaleChangeStdDev "Standard deviation of object scale change";
CM_ SG_ 59 VFC_Obj05_Reliability "The bitfield shows if the signal quality is assumed to be sufficient for functions with safety target -no false positives-
Bit 0: DYNAMIC
Bit 1: SEMSEG_SURFACE
Bit 2: WDD_CRITICAL
Bit 3: GOD_CONFIRMED
Bit 4: RESTRICTED
Bit 5: ISO26262_SAFE";
CM_ SG_ 59 VFC_Obj05_LightStatBrakeLight "The number of detected lights. More confident if more lights are detected. Similar to ISO 23150:2023: Light status (A.2.35)";
CM_ SG_ 59 VFC_Obj05_OutsideRoadMeasStatus "2D object outside road boundary measurement status, indicator if it is measured or predicted (if signal is available)";
CM_ SG_ 59 VFC_Obj05_Oncoming "Object is oncoming (if signal is available)";
CM_ SG_ 59 VFC_Obj05_OncomingMeasStatus "Object oncoming measurement status, indicator if it is measured or predicted (if signal is available)";
CM_ SG_ 59 VFC_Obj05_MovementStanding "Object is standing (if signal is available). Related to ISO 23150:2023: Movement status (A.2.32)";
CM_ SG_ 59 VFC_Obj05_MovementStandingMeasSt "Object standing measurement status, indicator if it is measured or predicted (if signal is available)";
CM_ SG_ 59 VFC_Obj05_MovementObserved "Object has been observed moving over the ground since it was first detected (if signal is available). Related to ISO 23150:2023: Movement status (A.2.32)";
CM_ SG_ 59 VFC_Obj05_MovementObservedMeasSt "Measurement status for object has been observed moving (if signal is available)";
CM_ SG_ 59 VFC_Obj05_TargetObjTypeAcc "2D target object type for ACC (if signal is available)";
CM_ SG_ 59 VFC_Obj05_TargetObjTypeAccConf "Confidence of 2D target object type detection for ACC (if signal is available)";
CM_ SG_ 60 VFC_Obj06_CRC "CRC - Autosar E2E Profile 5";
CM_ SG_ 60 VFC_Obj06_AliveCtr "Alive counter - Autosar E2E Profile 5";
CM_ SG_ 60 VFC_Obj06_ProtBlockCtr "Protocol-Signal: Block-Counter";
CM_ SG_ 60 VFC_Obj06_ExistProb "Object existence probability. ISO 23150:2023: Existence probability - object level (A.2.1)";
CM_ SG_ 60 VFC_Obj06_MeasurementStatus "Indicator if the object detected is measured or predicted. ISO 23150:2023: Measurement status - object level (A.2.9)";
CM_ SG_ 60 VFC_Obj06_ObjId "Unique Object ID. ISO 23150:2023: Object ID (A.2.2)";
CM_ SG_ 60 VFC_Obj06_Type "Classification of the object. ISO 23150:2023: Potentially moving object classification type (A.2.12)";
CM_ SG_ 60 VFC_Obj06_TypeConf "Confidence of the classified object type. ISO 23150:2023: Potentially moving object classification type - confidence (A.2.13)";
CM_ SG_ 60 VFC_Obj06_VisibleView "The visible view of the detected object. Reference point is in the middle of CLASSIC (front/rear) or SIDE (left/right). Related to ISO 23150:2023: Reference point (A.2.14)";
CM_ SG_ 60 VFC_Obj06_ClassifiedView "The classified view of object to be used in connection with VisibleView and Heading angle. Related to ISO 23150:2023: Reference point (A.2.14)";
CM_ SG_ 60 VFC_Obj06_Px "Object distance in longitudinal direction. ISO 23150:2023: Position - object level {x, y, z} (A.2.15)";
CM_ SG_ 60 VFC_Obj06_Py "Object distance in lateral direction. ISO 23150:2023: Position - object level {x, y, z} (A.2.15)";
CM_ SG_ 60 VFC_Obj06_PxStdDev "Standard deviation of Object distance in longitudinal direction. ISO 23150:2023: Position - object level {x, y, z} - error (A.2.16)";
CM_ SG_ 60 VFC_Obj06_PyStdDev "Standard deviation of Object distance in lateral direction. ISO 23150:2023: Position - object level {x, y, z} - error (A.2.16)";
CM_ SG_ 60 VFC_Obj06_OrientationYaw "Heading angle of the object. ISO 23150:2023: Orientation {yaw, pitch, roll} (A.2.17)";
CM_ SG_ 60 VFC_Obj06_OrientationYawStdDev "Standard deviation of object Heading angle. ISO 23150:2023: Orientation {yaw, pitch, roll} - error (A.2.18)";
CM_ SG_ 60 VFC_Obj06_Length "Length of the object. ISO 23150:2023: Bounding box extent {length, width, height} (A.2.20)";
CM_ SG_ 60 VFC_Obj06_Width "Width of the object. ISO 23150:2023: Bounding box extent {length, width, height} (A.2.20)";
CM_ SG_ 60 VFC_Obj06_Height "Height of the object. ISO 23150:2023: Bounding box extent {length, width, height} (A.2.20)";
CM_ SG_ 60 VFC_Obj06_LengthStdDev "Standard deviation of object length. ISO 23150:2023: Bounding box extent {length, width, height} - error (A.2.21)";
CM_ SG_ 60 VFC_Obj06_WidthStdDev "Standard deviation of object width. ISO 23150:2023: Bounding box extent {length, width, height} - error (A.2.21)";
CM_ SG_ 60 VFC_Obj06_HeightStdDev "Standard deviation of object height. ISO 23150:2023: Bounding box extent {length, width, height} - error (A.2.21)";
CM_ SG_ 60 VFC_Obj06_Vx "Object velocity in longitudinal direction. ISO 23150:2023: Velocity {x, y, z} - object level (A.2.24)";
CM_ SG_ 60 VFC_Obj06_Vy "Object velocity in lateral direction. ISO 23150:2023: Velocity {x, y, z} - object level (A.2.24)";
CM_ SG_ 60 VFC_Obj06_VxStdDev "Standard deviation of Object velocity in longitudinal direction. ISO 23150:2023: Velocity {x, y, z} - object level - error (A.2.25)";
CM_ SG_ 60 VFC_Obj06_VyStdDev "Standard deviation of Object velocity in lateral direction. ISO 23150:2023: Velocity {x, y, z} - object level - error (A.2.25)";
CM_ SG_ 60 VFC_Obj06_Ax "Object acceleration in longitudinal direction. ISO 23150:2023: Acceleration {x, y, z} (A.2.26)";
CM_ SG_ 60 VFC_Obj06_LightStatTurnIndicator "The detected direction indicator lights. Similar to ISO 23150:2023: Light status (A.2.35)";
CM_ SG_ 60 VFC_Obj06_Ay "Object acceleration in lateral direction. ISO 23150:2023: Acceleration {x, y, z} (A.2.26)";
CM_ SG_ 60 VFC_Obj06_AxStdDev "Standard deviation of Object acceleration in longitudinal direction. ISO 23150:2023: Acceleration {x, y, z} - error (A.2.27)";
CM_ SG_ 60 VFC_Obj06_AyStdDev "Standard deviation of Object acceleration in lateral direction. ISO 23150:2023: Acceleration {x, y, z} - error (A.2.27)";
CM_ SG_ 60 VFC_Obj06_MovementProbLat "Probability of object moving laterally (current state, not if moved at all in object history). Related to ISO 23150:2023: Movement status (A.2.32)";
CM_ SG_ 60 VFC_Obj06_MovementProbLong "Probability of object moving longitudinally (current state, not if moved at all in object history). Related to ISO 23150:2023: Movement status (A.2.32)";
CM_ SG_ 60 VFC_Obj06_2DAngPosEdgeLeft "Bounding box left edge in sensor coordinate system in ACCS coordinates; corresponds to tan(viewing angle of  object edge). ISO 23150:2023: Angular position {azimuth} (A.2.68)";
CM_ SG_ 60 VFC_Obj06_2DAngPosEdgeRight "Bounding box right edge in sensor coordinate system in ACCS coordinates; corresponds to tan(viewing angle of  object edge). ISO 23150:2023: Angular position {azimuth} (A.2.68)";
CM_ SG_ 60 VFC_Obj06_2DAngPosEdgeFar "Bounding box far edge in sensor coordinate system in ACCS coordinates; corresponds to tan(viewing angle of  object edge). ISO 23150:2023: Angular position {azimuth} (A.2.68)";
CM_ SG_ 60 VFC_Obj06_2DAngPosEdgeBot "Bounding box bottom edge in sensor coordinate system in ACCS coordinates; corresponds to tan(viewing angle of  object edge). Sign: upward direction negative value. ISO 23150:2023: Angular position {azimuth} (A.2.68)";
CM_ SG_ 60 VFC_Obj06_OutsideRoad "2D object is located outside road boundary (if signal is available)";
CM_ SG_ 60 VFC_Obj06_2DAngPosEdgeLeftStdDev "Standard deviation of the bounding box left edge";
CM_ SG_ 60 VFC_Obj06_2DAngPosEdgeRightStdDe "Standard deviation of the bounding box right edge";
CM_ SG_ 60 VFC_Obj06_2DAngPosEdgeFarStdDev "Standard deviation of the bounding box far edge";
CM_ SG_ 60 VFC_Obj06_2DAngPosEdgeBotStdDev "Standard deviation of the bounding box bottom edge";
CM_ SG_ 60 VFC_Obj06_2DNormVx "Normalised Object velocity in longitudinal direction (vx/dx_cam). Related to ISO 23150:2023: Angular velocity {azimuth} (A.2.69)";
CM_ SG_ 60 VFC_Obj06_2DNormVy "Normalised Object velocity in lateral direction (vy/dx_cam)";
CM_ SG_ 60 VFC_Obj06_2DNormAx "Normalised Object acceleration in longitudinal direction (ax/dx_cam)";
CM_ SG_ 60 VFC_Obj06_2DNormVxStdDev "Standard deviation of Normalised Object velocity in longitudinal direction";
CM_ SG_ 60 VFC_Obj06_MeasurementSource "Bitfield for the measurement programs from which this object originates
Bit 0: MOD
Bit 1: PDET
Bit 2: OFT
Bit 3: INVALID";
CM_ SG_ 60 VFC_Obj06_2DNormVyStdDev "Standard deviation of Normalised Object velocity in lateral direction";
CM_ SG_ 60 VFC_Obj06_2DNormAxStdDev "Standard deviation of Normalised Object acceleration in longitudinal direction";
CM_ SG_ 60 VFC_Obj06_2DScaleChange "Change in scale of the object in sensor's projection plane. ISO 23150:2023: Scale change - object level (A.2.70)";
CM_ SG_ 60 VFC_Obj06_2DScaleChangeStdDev "Standard deviation of object scale change";
CM_ SG_ 60 VFC_Obj06_Reliability "The bitfield shows if the signal quality is assumed to be sufficient for functions with safety target -no false positives-
Bit 0: DYNAMIC
Bit 1: SEMSEG_SURFACE
Bit 2: WDD_CRITICAL
Bit 3: GOD_CONFIRMED
Bit 4: RESTRICTED
Bit 5: ISO26262_SAFE";
CM_ SG_ 60 VFC_Obj06_LightStatBrakeLight "The number of detected lights. More confident if more lights are detected. Similar to ISO 23150:2023: Light status (A.2.35)";
CM_ SG_ 60 VFC_Obj06_OutsideRoadMeasStatus "2D object outside road boundary measurement status, indicator if it is measured or predicted (if signal is available)";
CM_ SG_ 60 VFC_Obj06_Oncoming "Object is oncoming (if signal is available)";
CM_ SG_ 60 VFC_Obj06_OncomingMeasStatus "Object oncoming measurement status, indicator if it is measured or predicted (if signal is available)";
CM_ SG_ 60 VFC_Obj06_MovementStanding "Object is standing (if signal is available). Related to ISO 23150:2023: Movement status (A.2.32)";
CM_ SG_ 60 VFC_Obj06_MovementStandingMeasSt "Object standing measurement status, indicator if it is measured or predicted (if signal is available)";
CM_ SG_ 60 VFC_Obj06_MovementObserved "Object has been observed moving over the ground since it was first detected (if signal is available). Related to ISO 23150:2023: Movement status (A.2.32)";
CM_ SG_ 60 VFC_Obj06_MovementObservedMeasSt "Measurement status for object has been observed moving (if signal is available)";
CM_ SG_ 60 VFC_Obj06_TargetObjTypeAcc "2D target object type for ACC (if signal is available)";
CM_ SG_ 60 VFC_Obj06_TargetObjTypeAccConf "Confidence of 2D target object type detection for ACC (if signal is available)";
CM_ SG_ 61 VFC_Obj07_CRC "CRC - Autosar E2E Profile 5";
CM_ SG_ 61 VFC_Obj07_AliveCtr "Alive counter - Autosar E2E Profile 5";
CM_ SG_ 61 VFC_Obj07_ProtBlockCtr "Protocol-Signal: Block-Counter";
CM_ SG_ 61 VFC_Obj07_ExistProb "Object existence probability. ISO 23150:2023: Existence probability - object level (A.2.1)";
CM_ SG_ 61 VFC_Obj07_MeasurementStatus "Indicator if the object detected is measured or predicted. ISO 23150:2023: Measurement status - object level (A.2.9)";
CM_ SG_ 61 VFC_Obj07_ObjId "Unique Object ID. ISO 23150:2023: Object ID (A.2.2)";
CM_ SG_ 61 VFC_Obj07_Type "Classification of the object. ISO 23150:2023: Potentially moving object classification type (A.2.12)";
CM_ SG_ 61 VFC_Obj07_TypeConf "Confidence of the classified object type. ISO 23150:2023: Potentially moving object classification type - confidence (A.2.13)";
CM_ SG_ 61 VFC_Obj07_VisibleView "The visible view of the detected object. Reference point is in the middle of CLASSIC (front/rear) or SIDE (left/right). Related to ISO 23150:2023: Reference point (A.2.14)";
CM_ SG_ 61 VFC_Obj07_ClassifiedView "The classified view of object to be used in connection with VisibleView and Heading angle. Related to ISO 23150:2023: Reference point (A.2.14)";
CM_ SG_ 61 VFC_Obj07_Px "Object distance in longitudinal direction. ISO 23150:2023: Position - object level {x, y, z} (A.2.15)";
CM_ SG_ 61 VFC_Obj07_Py "Object distance in lateral direction. ISO 23150:2023: Position - object level {x, y, z} (A.2.15)";
CM_ SG_ 61 VFC_Obj07_PxStdDev "Standard deviation of Object distance in longitudinal direction. ISO 23150:2023: Position - object level {x, y, z} - error (A.2.16)";
CM_ SG_ 61 VFC_Obj07_PyStdDev "Standard deviation of Object distance in lateral direction. ISO 23150:2023: Position - object level {x, y, z} - error (A.2.16)";
CM_ SG_ 61 VFC_Obj07_OrientationYaw "Heading angle of the object. ISO 23150:2023: Orientation {yaw, pitch, roll} (A.2.17)";
CM_ SG_ 61 VFC_Obj07_OrientationYawStdDev "Standard deviation of object Heading angle. ISO 23150:2023: Orientation {yaw, pitch, roll} - error (A.2.18)";
CM_ SG_ 61 VFC_Obj07_Length "Length of the object. ISO 23150:2023: Bounding box extent {length, width, height} (A.2.20)";
CM_ SG_ 61 VFC_Obj07_Width "Width of the object. ISO 23150:2023: Bounding box extent {length, width, height} (A.2.20)";
CM_ SG_ 61 VFC_Obj07_Height "Height of the object. ISO 23150:2023: Bounding box extent {length, width, height} (A.2.20)";
CM_ SG_ 61 VFC_Obj07_LengthStdDev "Standard deviation of object length. ISO 23150:2023: Bounding box extent {length, width, height} - error (A.2.21)";
CM_ SG_ 61 VFC_Obj07_WidthStdDev "Standard deviation of object width. ISO 23150:2023: Bounding box extent {length, width, height} - error (A.2.21)";
CM_ SG_ 61 VFC_Obj07_HeightStdDev "Standard deviation of object height. ISO 23150:2023: Bounding box extent {length, width, height} - error (A.2.21)";
CM_ SG_ 61 VFC_Obj07_Vx "Object velocity in longitudinal direction. ISO 23150:2023: Velocity {x, y, z} - object level (A.2.24)";
CM_ SG_ 61 VFC_Obj07_Vy "Object velocity in lateral direction. ISO 23150:2023: Velocity {x, y, z} - object level (A.2.24)";
CM_ SG_ 61 VFC_Obj07_VxStdDev "Standard deviation of Object velocity in longitudinal direction. ISO 23150:2023: Velocity {x, y, z} - object level - error (A.2.25)";
CM_ SG_ 61 VFC_Obj07_VyStdDev "Standard deviation of Object velocity in lateral direction. ISO 23150:2023: Velocity {x, y, z} - object level - error (A.2.25)";
CM_ SG_ 61 VFC_Obj07_Ax "Object acceleration in longitudinal direction. ISO 23150:2023: Acceleration {x, y, z} (A.2.26)";
CM_ SG_ 61 VFC_Obj07_LightStatTurnIndicator "The detected direction indicator lights. Similar to ISO 23150:2023: Light status (A.2.35)";
CM_ SG_ 61 VFC_Obj07_Ay "Object acceleration in lateral direction. ISO 23150:2023: Acceleration {x, y, z} (A.2.26)";
CM_ SG_ 61 VFC_Obj07_AxStdDev "Standard deviation of Object acceleration in longitudinal direction. ISO 23150:2023: Acceleration {x, y, z} - error (A.2.27)";
CM_ SG_ 61 VFC_Obj07_AyStdDev "Standard deviation of Object acceleration in lateral direction. ISO 23150:2023: Acceleration {x, y, z} - error (A.2.27)";
CM_ SG_ 61 VFC_Obj07_MovementProbLat "Probability of object moving laterally (current state, not if moved at all in object history). Related to ISO 23150:2023: Movement status (A.2.32)";
CM_ SG_ 61 VFC_Obj07_MovementProbLong "Probability of object moving longitudinally (current state, not if moved at all in object history). Related to ISO 23150:2023: Movement status (A.2.32)";
CM_ SG_ 61 VFC_Obj07_2DAngPosEdgeLeft "Bounding box left edge in sensor coordinate system in ACCS coordinates; corresponds to tan(viewing angle of  object edge). ISO 23150:2023: Angular position {azimuth} (A.2.68)";
CM_ SG_ 61 VFC_Obj07_2DAngPosEdgeRight "Bounding box right edge in sensor coordinate system in ACCS coordinates; corresponds to tan(viewing angle of  object edge). ISO 23150:2023: Angular position {azimuth} (A.2.68)";
CM_ SG_ 61 VFC_Obj07_2DAngPosEdgeFar "Bounding box far edge in sensor coordinate system in ACCS coordinates; corresponds to tan(viewing angle of  object edge). ISO 23150:2023: Angular position {azimuth} (A.2.68)";
CM_ SG_ 61 VFC_Obj07_2DAngPosEdgeBot "Bounding box bottom edge in sensor coordinate system in ACCS coordinates; corresponds to tan(viewing angle of  object edge). Sign: upward direction negative value. ISO 23150:2023: Angular position {azimuth} (A.2.68)";
CM_ SG_ 61 VFC_Obj07_OutsideRoad "2D object is located outside road boundary (if signal is available)";
CM_ SG_ 61 VFC_Obj07_2DAngPosEdgeLeftStdDev "Standard deviation of the bounding box left edge";
CM_ SG_ 61 VFC_Obj07_2DAngPosEdgeRightStdDe "Standard deviation of the bounding box right edge";
CM_ SG_ 61 VFC_Obj07_2DAngPosEdgeFarStdDev "Standard deviation of the bounding box far edge";
CM_ SG_ 61 VFC_Obj07_2DAngPosEdgeBotStdDev "Standard deviation of the bounding box bottom edge";
CM_ SG_ 61 VFC_Obj07_2DNormVx "Normalised Object velocity in longitudinal direction (vx/dx_cam). Related to ISO 23150:2023: Angular velocity {azimuth} (A.2.69)";
CM_ SG_ 61 VFC_Obj07_2DNormVy "Normalised Object velocity in lateral direction (vy/dx_cam)";
CM_ SG_ 61 VFC_Obj07_2DNormAx "Normalised Object acceleration in longitudinal direction (ax/dx_cam)";
CM_ SG_ 61 VFC_Obj07_2DNormVxStdDev "Standard deviation of Normalised Object velocity in longitudinal direction";
CM_ SG_ 61 VFC_Obj07_MeasurementSource "Bitfield for the measurement programs from which this object originates
Bit 0: MOD
Bit 1: PDET
Bit 2: OFT
Bit 3: INVALID";
CM_ SG_ 61 VFC_Obj07_2DNormVyStdDev "Standard deviation of Normalised Object velocity in lateral direction";
CM_ SG_ 61 VFC_Obj07_2DNormAxStdDev "Standard deviation of Normalised Object acceleration in longitudinal direction";
CM_ SG_ 61 VFC_Obj07_2DScaleChange "Change in scale of the object in sensor's projection plane. ISO 23150:2023: Scale change - object level (A.2.70)";
CM_ SG_ 61 VFC_Obj07_2DScaleChangeStdDev "Standard deviation of object scale change";
CM_ SG_ 61 VFC_Obj07_Reliability "The bitfield shows if the signal quality is assumed to be sufficient for functions with safety target -no false positives-
Bit 0: DYNAMIC
Bit 1: SEMSEG_SURFACE
Bit 2: WDD_CRITICAL
Bit 3: GOD_CONFIRMED
Bit 4: RESTRICTED
Bit 5: ISO26262_SAFE";
CM_ SG_ 61 VFC_Obj07_LightStatBrakeLight "The number of detected lights. More confident if more lights are detected. Similar to ISO 23150:2023: Light status (A.2.35)";
CM_ SG_ 61 VFC_Obj07_OutsideRoadMeasStatus "2D object outside road boundary measurement status, indicator if it is measured or predicted (if signal is available)";
CM_ SG_ 61 VFC_Obj07_Oncoming "Object is oncoming (if signal is available)";
CM_ SG_ 61 VFC_Obj07_OncomingMeasStatus "Object oncoming measurement status, indicator if it is measured or predicted (if signal is available)";
CM_ SG_ 61 VFC_Obj07_MovementStanding "Object is standing (if signal is available). Related to ISO 23150:2023: Movement status (A.2.32)";
CM_ SG_ 61 VFC_Obj07_MovementStandingMeasSt "Object standing measurement status, indicator if it is measured or predicted (if signal is available)";
CM_ SG_ 61 VFC_Obj07_MovementObserved "Object has been observed moving over the ground since it was first detected (if signal is available). Related to ISO 23150:2023: Movement status (A.2.32)";
CM_ SG_ 61 VFC_Obj07_MovementObservedMeasSt "Measurement status for object has been observed moving (if signal is available)";
CM_ SG_ 61 VFC_Obj07_TargetObjTypeAcc "2D target object type for ACC (if signal is available)";
CM_ SG_ 61 VFC_Obj07_TargetObjTypeAccConf "Confidence of 2D target object type detection for ACC (if signal is available)";
CM_ SG_ 62 VFC_Obj08_CRC "CRC - Autosar E2E Profile 5";
CM_ SG_ 62 VFC_Obj08_AliveCtr "Alive counter - Autosar E2E Profile 5";
CM_ SG_ 62 VFC_Obj08_ProtBlockCtr "Protocol-Signal: Block-Counter";
CM_ SG_ 62 VFC_Obj08_ExistProb "Object existence probability. ISO 23150:2023: Existence probability - object level (A.2.1)";
CM_ SG_ 62 VFC_Obj08_MeasurementStatus "Indicator if the object detected is measured or predicted. ISO 23150:2023: Measurement status - object level (A.2.9)";
CM_ SG_ 62 VFC_Obj08_ObjId "Unique Object ID. ISO 23150:2023: Object ID (A.2.2)";
CM_ SG_ 62 VFC_Obj08_Type "Classification of the object. ISO 23150:2023: Potentially moving object classification type (A.2.12)";
CM_ SG_ 62 VFC_Obj08_TypeConf "Confidence of the classified object type. ISO 23150:2023: Potentially moving object classification type - confidence (A.2.13)";
CM_ SG_ 62 VFC_Obj08_VisibleView "The visible view of the detected object. Reference point is in the middle of CLASSIC (front/rear) or SIDE (left/right). Related to ISO 23150:2023: Reference point (A.2.14)";
CM_ SG_ 62 VFC_Obj08_ClassifiedView "The classified view of object to be used in connection with VisibleView and Heading angle. Related to ISO 23150:2023: Reference point (A.2.14)";
CM_ SG_ 62 VFC_Obj08_Px "Object distance in longitudinal direction. ISO 23150:2023: Position - object level {x, y, z} (A.2.15)";
CM_ SG_ 62 VFC_Obj08_Py "Object distance in lateral direction. ISO 23150:2023: Position - object level {x, y, z} (A.2.15)";
CM_ SG_ 62 VFC_Obj08_PxStdDev "Standard deviation of Object distance in longitudinal direction. ISO 23150:2023: Position - object level {x, y, z} - error (A.2.16)";
CM_ SG_ 62 VFC_Obj08_PyStdDev "Standard deviation of Object distance in lateral direction. ISO 23150:2023: Position - object level {x, y, z} - error (A.2.16)";
CM_ SG_ 62 VFC_Obj08_OrientationYaw "Heading angle of the object. ISO 23150:2023: Orientation {yaw, pitch, roll} (A.2.17)";
CM_ SG_ 62 VFC_Obj08_OrientationYawStdDev "Standard deviation of object Heading angle. ISO 23150:2023: Orientation {yaw, pitch, roll} - error (A.2.18)";
CM_ SG_ 62 VFC_Obj08_Length "Length of the object. ISO 23150:2023: Bounding box extent {length, width, height} (A.2.20)";
CM_ SG_ 62 VFC_Obj08_Width "Width of the object. ISO 23150:2023: Bounding box extent {length, width, height} (A.2.20)";
CM_ SG_ 62 VFC_Obj08_Height "Height of the object. ISO 23150:2023: Bounding box extent {length, width, height} (A.2.20)";
CM_ SG_ 62 VFC_Obj08_LengthStdDev "Standard deviation of object length. ISO 23150:2023: Bounding box extent {length, width, height} - error (A.2.21)";
CM_ SG_ 62 VFC_Obj08_WidthStdDev "Standard deviation of object width. ISO 23150:2023: Bounding box extent {length, width, height} - error (A.2.21)";
CM_ SG_ 62 VFC_Obj08_HeightStdDev "Standard deviation of object height. ISO 23150:2023: Bounding box extent {length, width, height} - error (A.2.21)";
CM_ SG_ 62 VFC_Obj08_Vx "Object velocity in longitudinal direction. ISO 23150:2023: Velocity {x, y, z} - object level (A.2.24)";
CM_ SG_ 62 VFC_Obj08_Vy "Object velocity in lateral direction. ISO 23150:2023: Velocity {x, y, z} - object level (A.2.24)";
CM_ SG_ 62 VFC_Obj08_VxStdDev "Standard deviation of Object velocity in longitudinal direction. ISO 23150:2023: Velocity {x, y, z} - object level - error (A.2.25)";
CM_ SG_ 62 VFC_Obj08_VyStdDev "Standard deviation of Object velocity in lateral direction. ISO 23150:2023: Velocity {x, y, z} - object level - error (A.2.25)";
CM_ SG_ 62 VFC_Obj08_Ax "Object acceleration in longitudinal direction. ISO 23150:2023: Acceleration {x, y, z} (A.2.26)";
CM_ SG_ 62 VFC_Obj08_LightStatTurnIndicator "The detected direction indicator lights. Similar to ISO 23150:2023: Light status (A.2.35)";
CM_ SG_ 62 VFC_Obj08_Ay "Object acceleration in lateral direction. ISO 23150:2023: Acceleration {x, y, z} (A.2.26)";
CM_ SG_ 62 VFC_Obj08_AxStdDev "Standard deviation of Object acceleration in longitudinal direction. ISO 23150:2023: Acceleration {x, y, z} - error (A.2.27)";
CM_ SG_ 62 VFC_Obj08_AyStdDev "Standard deviation of Object acceleration in lateral direction. ISO 23150:2023: Acceleration {x, y, z} - error (A.2.27)";
CM_ SG_ 62 VFC_Obj08_MovementProbLat "Probability of object moving laterally (current state, not if moved at all in object history). Related to ISO 23150:2023: Movement status (A.2.32)";
CM_ SG_ 62 VFC_Obj08_MovementProbLong "Probability of object moving longitudinally (current state, not if moved at all in object history). Related to ISO 23150:2023: Movement status (A.2.32)";
CM_ SG_ 62 VFC_Obj08_2DAngPosEdgeLeft "Bounding box left edge in sensor coordinate system in ACCS coordinates; corresponds to tan(viewing angle of  object edge). ISO 23150:2023: Angular position {azimuth} (A.2.68)";
CM_ SG_ 62 VFC_Obj08_2DAngPosEdgeRight "Bounding box right edge in sensor coordinate system in ACCS coordinates; corresponds to tan(viewing angle of  object edge). ISO 23150:2023: Angular position {azimuth} (A.2.68)";
CM_ SG_ 62 VFC_Obj08_2DAngPosEdgeFar "Bounding box far edge in sensor coordinate system in ACCS coordinates; corresponds to tan(viewing angle of  object edge). ISO 23150:2023: Angular position {azimuth} (A.2.68)";
CM_ SG_ 62 VFC_Obj08_2DAngPosEdgeBot "Bounding box bottom edge in sensor coordinate system in ACCS coordinates; corresponds to tan(viewing angle of  object edge). Sign: upward direction negative value. ISO 23150:2023: Angular position {azimuth} (A.2.68)";
CM_ SG_ 62 VFC_Obj08_OutsideRoad "2D object is located outside road boundary (if signal is available)";
CM_ SG_ 62 VFC_Obj08_2DAngPosEdgeLeftStdDev "Standard deviation of the bounding box left edge";
CM_ SG_ 62 VFC_Obj08_2DAngPosEdgeRightStdDe "Standard deviation of the bounding box right edge";
CM_ SG_ 62 VFC_Obj08_2DAngPosEdgeFarStdDev "Standard deviation of the bounding box far edge";
CM_ SG_ 62 VFC_Obj08_2DAngPosEdgeBotStdDev "Standard deviation of the bounding box bottom edge";
CM_ SG_ 62 VFC_Obj08_2DNormVx "Normalised Object velocity in longitudinal direction (vx/dx_cam). Related to ISO 23150:2023: Angular velocity {azimuth} (A.2.69)";
CM_ SG_ 62 VFC_Obj08_2DNormVy "Normalised Object velocity in lateral direction (vy/dx_cam)";
CM_ SG_ 62 VFC_Obj08_2DNormAx "Normalised Object acceleration in longitudinal direction (ax/dx_cam)";
CM_ SG_ 62 VFC_Obj08_2DNormVxStdDev "Standard deviation of Normalised Object velocity in longitudinal direction";
CM_ SG_ 62 VFC_Obj08_MeasurementSource "Bitfield for the measurement programs from which this object originates
Bit 0: MOD
Bit 1: PDET
Bit 2: OFT
Bit 3: INVALID";
CM_ SG_ 62 VFC_Obj08_2DNormVyStdDev "Standard deviation of Normalised Object velocity in lateral direction";
CM_ SG_ 62 VFC_Obj08_2DNormAxStdDev "Standard deviation of Normalised Object acceleration in longitudinal direction";
CM_ SG_ 62 VFC_Obj08_2DScaleChange "Change in scale of the object in sensor's projection plane. ISO 23150:2023: Scale change - object level (A.2.70)";
CM_ SG_ 62 VFC_Obj08_2DScaleChangeStdDev "Standard deviation of object scale change";
CM_ SG_ 62 VFC_Obj08_Reliability "The bitfield shows if the signal quality is assumed to be sufficient for functions with safety target -no false positives-
Bit 0: DYNAMIC
Bit 1: SEMSEG_SURFACE
Bit 2: WDD_CRITICAL
Bit 3: GOD_CONFIRMED
Bit 4: RESTRICTED
Bit 5: ISO26262_SAFE";
CM_ SG_ 62 VFC_Obj08_LightStatBrakeLight "The number of detected lights. More confident if more lights are detected. Similar to ISO 23150:2023: Light status (A.2.35)";
CM_ SG_ 62 VFC_Obj08_OutsideRoadMeasStatus "2D object outside road boundary measurement status, indicator if it is measured or predicted (if signal is available)";
CM_ SG_ 62 VFC_Obj08_Oncoming "Object is oncoming (if signal is available)";
CM_ SG_ 62 VFC_Obj08_OncomingMeasStatus "Object oncoming measurement status, indicator if it is measured or predicted (if signal is available)";
CM_ SG_ 62 VFC_Obj08_MovementStanding "Object is standing (if signal is available). Related to ISO 23150:2023: Movement status (A.2.32)";
CM_ SG_ 62 VFC_Obj08_MovementStandingMeasSt "Object standing measurement status, indicator if it is measured or predicted (if signal is available)";
CM_ SG_ 62 VFC_Obj08_MovementObserved "Object has been observed moving over the ground since it was first detected (if signal is available). Related to ISO 23150:2023: Movement status (A.2.32)";
CM_ SG_ 62 VFC_Obj08_MovementObservedMeasSt "Measurement status for object has been observed moving (if signal is available)";
CM_ SG_ 62 VFC_Obj08_TargetObjTypeAcc "2D target object type for ACC (if signal is available)";
CM_ SG_ 62 VFC_Obj08_TargetObjTypeAccConf "Confidence of 2D target object type detection for ACC (if signal is available)";
CM_ SG_ 63 VFC_Obj09_CRC "CRC - Autosar E2E Profile 5";
CM_ SG_ 63 VFC_Obj09_AliveCtr "Alive counter - Autosar E2E Profile 5";
CM_ SG_ 63 VFC_Obj09_ProtBlockCtr "Protocol-Signal: Block-Counter";
CM_ SG_ 63 VFC_Obj09_ExistProb "Object existence probability. ISO 23150:2023: Existence probability - object level (A.2.1)";
CM_ SG_ 63 VFC_Obj09_MeasurementStatus "Indicator if the object detected is measured or predicted. ISO 23150:2023: Measurement status - object level (A.2.9)";
CM_ SG_ 63 VFC_Obj09_ObjId "Unique Object ID. ISO 23150:2023: Object ID (A.2.2)";
CM_ SG_ 63 VFC_Obj09_Type "Classification of the object. ISO 23150:2023: Potentially moving object classification type (A.2.12)";
CM_ SG_ 63 VFC_Obj09_TypeConf "Confidence of the classified object type. ISO 23150:2023: Potentially moving object classification type - confidence (A.2.13)";
CM_ SG_ 63 VFC_Obj09_VisibleView "The visible view of the detected object. Reference point is in the middle of CLASSIC (front/rear) or SIDE (left/right). Related to ISO 23150:2023: Reference point (A.2.14)";
CM_ SG_ 63 VFC_Obj09_ClassifiedView "The classified view of object to be used in connection with VisibleView and Heading angle. Related to ISO 23150:2023: Reference point (A.2.14)";
CM_ SG_ 63 VFC_Obj09_Px "Object distance in longitudinal direction. ISO 23150:2023: Position - object level {x, y, z} (A.2.15)";
CM_ SG_ 63 VFC_Obj09_Py "Object distance in lateral direction. ISO 23150:2023: Position - object level {x, y, z} (A.2.15)";
CM_ SG_ 63 VFC_Obj09_PxStdDev "Standard deviation of Object distance in longitudinal direction. ISO 23150:2023: Position - object level {x, y, z} - error (A.2.16)";
CM_ SG_ 63 VFC_Obj09_PyStdDev "Standard deviation of Object distance in lateral direction. ISO 23150:2023: Position - object level {x, y, z} - error (A.2.16)";
CM_ SG_ 63 VFC_Obj09_OrientationYaw "Heading angle of the object. ISO 23150:2023: Orientation {yaw, pitch, roll} (A.2.17)";
CM_ SG_ 63 VFC_Obj09_OrientationYawStdDev "Standard deviation of object Heading angle. ISO 23150:2023: Orientation {yaw, pitch, roll} - error (A.2.18)";
CM_ SG_ 63 VFC_Obj09_Length "Length of the object. ISO 23150:2023: Bounding box extent {length, width, height} (A.2.20)";
CM_ SG_ 63 VFC_Obj09_Width "Width of the object. ISO 23150:2023: Bounding box extent {length, width, height} (A.2.20)";
CM_ SG_ 63 VFC_Obj09_Height "Height of the object. ISO 23150:2023: Bounding box extent {length, width, height} (A.2.20)";
CM_ SG_ 63 VFC_Obj09_LengthStdDev "Standard deviation of object length. ISO 23150:2023: Bounding box extent {length, width, height} - error (A.2.21)";
CM_ SG_ 63 VFC_Obj09_WidthStdDev "Standard deviation of object width. ISO 23150:2023: Bounding box extent {length, width, height} - error (A.2.21)";
CM_ SG_ 63 VFC_Obj09_HeightStdDev "Standard deviation of object height. ISO 23150:2023: Bounding box extent {length, width, height} - error (A.2.21)";
CM_ SG_ 63 VFC_Obj09_Vx "Object velocity in longitudinal direction. ISO 23150:2023: Velocity {x, y, z} - object level (A.2.24)";
CM_ SG_ 63 VFC_Obj09_Vy "Object velocity in lateral direction. ISO 23150:2023: Velocity {x, y, z} - object level (A.2.24)";
CM_ SG_ 63 VFC_Obj09_VxStdDev "Standard deviation of Object velocity in longitudinal direction. ISO 23150:2023: Velocity {x, y, z} - object level - error (A.2.25)";
CM_ SG_ 63 VFC_Obj09_VyStdDev "Standard deviation of Object velocity in lateral direction. ISO 23150:2023: Velocity {x, y, z} - object level - error (A.2.25)";
CM_ SG_ 63 VFC_Obj09_Ax "Object acceleration in longitudinal direction. ISO 23150:2023: Acceleration {x, y, z} (A.2.26)";
CM_ SG_ 63 VFC_Obj09_LightStatTurnIndicator "The detected direction indicator lights. Similar to ISO 23150:2023: Light status (A.2.35)";
CM_ SG_ 63 VFC_Obj09_Ay "Object acceleration in lateral direction. ISO 23150:2023: Acceleration {x, y, z} (A.2.26)";
CM_ SG_ 63 VFC_Obj09_AxStdDev "Standard deviation of Object acceleration in longitudinal direction. ISO 23150:2023: Acceleration {x, y, z} - error (A.2.27)";
CM_ SG_ 63 VFC_Obj09_AyStdDev "Standard deviation of Object acceleration in lateral direction. ISO 23150:2023: Acceleration {x, y, z} - error (A.2.27)";
CM_ SG_ 63 VFC_Obj09_MovementProbLat "Probability of object moving laterally (current state, not if moved at all in object history). Related to ISO 23150:2023: Movement status (A.2.32)";
CM_ SG_ 63 VFC_Obj09_MovementProbLong "Probability of object moving longitudinally (current state, not if moved at all in object history). Related to ISO 23150:2023: Movement status (A.2.32)";
CM_ SG_ 63 VFC_Obj09_2DAngPosEdgeLeft "Bounding box left edge in sensor coordinate system in ACCS coordinates; corresponds to tan(viewing angle of  object edge). ISO 23150:2023: Angular position {azimuth} (A.2.68)";
CM_ SG_ 63 VFC_Obj09_2DAngPosEdgeRight "Bounding box right edge in sensor coordinate system in ACCS coordinates; corresponds to tan(viewing angle of  object edge). ISO 23150:2023: Angular position {azimuth} (A.2.68)";
CM_ SG_ 63 VFC_Obj09_2DAngPosEdgeFar "Bounding box far edge in sensor coordinate system in ACCS coordinates; corresponds to tan(viewing angle of  object edge). ISO 23150:2023: Angular position {azimuth} (A.2.68)";
CM_ SG_ 63 VFC_Obj09_2DAngPosEdgeBot "Bounding box bottom edge in sensor coordinate system in ACCS coordinates; corresponds to tan(viewing angle of  object edge). Sign: upward direction negative value. ISO 23150:2023: Angular position {azimuth} (A.2.68)";
CM_ SG_ 63 VFC_Obj09_OutsideRoad "2D object is located outside road boundary (if signal is available)";
CM_ SG_ 63 VFC_Obj09_2DAngPosEdgeLeftStdDev "Standard deviation of the bounding box left edge";
CM_ SG_ 63 VFC_Obj09_2DAngPosEdgeRightStdDe "Standard deviation of the bounding box right edge";
CM_ SG_ 63 VFC_Obj09_2DAngPosEdgeFarStdDev "Standard deviation of the bounding box far edge";
CM_ SG_ 63 VFC_Obj09_2DAngPosEdgeBotStdDev "Standard deviation of the bounding box bottom edge";
CM_ SG_ 63 VFC_Obj09_2DNormVx "Normalised Object velocity in longitudinal direction (vx/dx_cam). Related to ISO 23150:2023: Angular velocity {azimuth} (A.2.69)";
CM_ SG_ 63 VFC_Obj09_2DNormVy "Normalised Object velocity in lateral direction (vy/dx_cam)";
CM_ SG_ 63 VFC_Obj09_2DNormAx "Normalised Object acceleration in longitudinal direction (ax/dx_cam)";
CM_ SG_ 63 VFC_Obj09_2DNormVxStdDev "Standard deviation of Normalised Object velocity in longitudinal direction";
CM_ SG_ 63 VFC_Obj09_MeasurementSource "Bitfield for the measurement programs from which this object originates
Bit 0: MOD
Bit 1: PDET
Bit 2: OFT
Bit 3: INVALID";
CM_ SG_ 63 VFC_Obj09_2DNormVyStdDev "Standard deviation of Normalised Object velocity in lateral direction";
CM_ SG_ 63 VFC_Obj09_2DNormAxStdDev "Standard deviation of Normalised Object acceleration in longitudinal direction";
CM_ SG_ 63 VFC_Obj09_2DScaleChange "Change in scale of the object in sensor's projection plane. ISO 23150:2023: Scale change - object level (A.2.70)";
CM_ SG_ 63 VFC_Obj09_2DScaleChangeStdDev "Standard deviation of object scale change";
CM_ SG_ 63 VFC_Obj09_Reliability "The bitfield shows if the signal quality is assumed to be sufficient for functions with safety target -no false positives-
Bit 0: DYNAMIC
Bit 1: SEMSEG_SURFACE
Bit 2: WDD_CRITICAL
Bit 3: GOD_CONFIRMED
Bit 4: RESTRICTED
Bit 5: ISO26262_SAFE";
CM_ SG_ 63 VFC_Obj09_LightStatBrakeLight "The number of detected lights. More confident if more lights are detected. Similar to ISO 23150:2023: Light status (A.2.35)";
CM_ SG_ 63 VFC_Obj09_OutsideRoadMeasStatus "2D object outside road boundary measurement status, indicator if it is measured or predicted (if signal is available)";
CM_ SG_ 63 VFC_Obj09_Oncoming "Object is oncoming (if signal is available)";
CM_ SG_ 63 VFC_Obj09_OncomingMeasStatus "Object oncoming measurement status, indicator if it is measured or predicted (if signal is available)";
CM_ SG_ 63 VFC_Obj09_MovementStanding "Object is standing (if signal is available). Related to ISO 23150:2023: Movement status (A.2.32)";
CM_ SG_ 63 VFC_Obj09_MovementStandingMeasSt "Object standing measurement status, indicator if it is measured or predicted (if signal is available)";
CM_ SG_ 63 VFC_Obj09_MovementObserved "Object has been observed moving over the ground since it was first detected (if signal is available). Related to ISO 23150:2023: Movement status (A.2.32)";
CM_ SG_ 63 VFC_Obj09_MovementObservedMeasSt "Measurement status for object has been observed moving (if signal is available)";
CM_ SG_ 63 VFC_Obj09_TargetObjTypeAcc "2D target object type for ACC (if signal is available)";
CM_ SG_ 63 VFC_Obj09_TargetObjTypeAccConf "Confidence of 2D target object type detection for ACC (if signal is available)";
BA_DEF_ BO_  "CANFD_BRS" ENUM  "0","1";
BA_DEF_ BO_  "GenMsgCycleTime" INT 0 65535;
BA_DEF_ BO_  "GenMsgILSupport" ENUM  "No","Yes";
BA_DEF_ BO_  "GenMsgSendType" ENUM  "Cyclic","Event","reserved","reserved","reserved","reserved","reserved","IfActive","NoMsgSendType","reserved","reserved","reserved";
BA_DEF_ BO_  "VFrameFormat" ENUM  "StandardCAN","ExtendedCAN","reserved","reserved","reserved","reserved","reserved","reserved","reserved","reserved","reserved","reserved","reserved","reserved","StandardCAN_FD","ExtendedCAN_FD";
BA_DEF_ BO_  "E2Eprofile" STRING ;
BA_DEF_ BO_  "DataID" HEX 0 655535;
BA_DEF_ SG_  "GenSigSendType" ENUM  "Cyclic","OnWrite","OnWriteWithRepetition","OnChange","OnChangeWithRepetition","IfActive","IfActiveWithRepetition","NoSigSendType","OnChangeAndIfActive","OnChangeAndIfActiveWithRepetition";
BA_DEF_ SG_  "GenSigStartValue" HEX 0 2147483648;
BA_DEF_  "BusType" STRING ;
BA_DEF_  "DBName" STRING ;
BA_DEF_DEF_  "CANFD_BRS" "1";
BA_DEF_DEF_  "GenMsgCycleTime" 0;
BA_DEF_DEF_  "GenMsgILSupport" "Yes";
BA_DEF_DEF_  "GenMsgSendType" "Cyclic";
BA_DEF_DEF_  "VFrameFormat" "";
BA_DEF_DEF_  "E2Eprofile" "None";
BA_DEF_DEF_  "DataID" 0;
BA_DEF_DEF_  "GenSigSendType" "NoSigSendType";
BA_DEF_DEF_  "GenSigStartValue" 0;
BA_DEF_DEF_  "BusType" "";
BA_DEF_DEF_  "DBName" "ChooseYourNameHere";
BA_ "BusType" "CAN FD";
BA_ "DBName" "OD_5R1V1D_DASy_RFC_VFC";
BA_ "GenMsgSendType" BO_ 16 1;
BA_ "E2Eprofile" BO_ 16 "AUTOSAR Profile 22";
BA_ "DataID" BO_ 16 8208;
BA_ "VFrameFormat" BO_ 16 14;
BA_ "GenMsgSendType" BO_ 32 1;
BA_ "E2Eprofile" BO_ 32 "AUTOSAR Profile 5";
BA_ "DataID" BO_ 32 8224;
BA_ "VFrameFormat" BO_ 32 14;
BA_ "GenMsgCycleTime" BO_ 33 50;
BA_ "E2Eprofile" BO_ 33 "AUTOSAR Profile 22";
BA_ "DataID" BO_ 33 8225;
BA_ "VFrameFormat" BO_ 33 14;
BA_ "GenMsgSendType" BO_ 52 1;
BA_ "E2Eprofile" BO_ 52 "AUTOSAR Profile 5";
BA_ "DataID" BO_ 52 8244;
BA_ "VFrameFormat" BO_ 52 14;
BA_ "GenMsgSendType" BO_ 54 1;
BA_ "E2Eprofile" BO_ 54 "AUTOSAR Profile 5";
BA_ "DataID" BO_ 54 8246;
BA_ "VFrameFormat" BO_ 54 14;
BA_ "GenMsgSendType" BO_ 55 1;
BA_ "E2Eprofile" BO_ 55 "AUTOSAR Profile 5";
BA_ "DataID" BO_ 55 8247;
BA_ "VFrameFormat" BO_ 55 14;
BA_ "GenMsgSendType" BO_ 56 1;
BA_ "E2Eprofile" BO_ 56 "AUTOSAR Profile 5";
BA_ "DataID" BO_ 56 8248;
BA_ "VFrameFormat" BO_ 56 14;
BA_ "GenMsgSendType" BO_ 57 1;
BA_ "E2Eprofile" BO_ 57 "AUTOSAR Profile 5";
BA_ "DataID" BO_ 57 8249;
BA_ "VFrameFormat" BO_ 57 14;
BA_ "GenMsgSendType" BO_ 58 1;
BA_ "E2Eprofile" BO_ 58 "AUTOSAR Profile 5";
BA_ "DataID" BO_ 58 8250;
BA_ "VFrameFormat" BO_ 58 14;
BA_ "GenMsgSendType" BO_ 59 1;
BA_ "E2Eprofile" BO_ 59 "AUTOSAR Profile 5";
BA_ "DataID" BO_ 59 8251;
BA_ "VFrameFormat" BO_ 59 14;
BA_ "GenMsgSendType" BO_ 60 1;
BA_ "E2Eprofile" BO_ 60 "AUTOSAR Profile 5";
BA_ "DataID" BO_ 60 8252;
BA_ "VFrameFormat" BO_ 60 14;
BA_ "GenMsgSendType" BO_ 61 1;
BA_ "E2Eprofile" BO_ 61 "AUTOSAR Profile 5";
BA_ "DataID" BO_ 61 8253;
BA_ "VFrameFormat" BO_ 61 14;
BA_ "GenMsgSendType" BO_ 62 1;
BA_ "E2Eprofile" BO_ 62 "AUTOSAR Profile 5";
BA_ "DataID" BO_ 62 8254;
BA_ "VFrameFormat" BO_ 62 14;
BA_ "GenMsgSendType" BO_ 63 1;
BA_ "E2Eprofile" BO_ 63 "AUTOSAR Profile 5";
BA_ "DataID" BO_ 63 8255;
BA_ "VFrameFormat" BO_ 63 14;
BA_ "GenSigStartValue" SG_ 16 VFC_Ax_CommandValue 834;
BA_ "GenSigStartValue" SG_ 32 VFC_Status_SensorOrientYaw 512;
BA_ "GenSigStartValue" SG_ 32 VFC_Status_SensorOrientPitch 512;
BA_ "GenSigStartValue" SG_ 32 VFC_Status_SensorOrientRoll 512;
BA_ "GenSigStartValue" SG_ 32 VFC_Status_SensorOriginPointX 4096;
BA_ "GenSigStartValue" SG_ 32 VFC_Status_SensorOriginPointY 2048;
BA_ "GenSigStartValue" SG_ 52 VFC_ObjHdr_IfVersionIdMajor 1;
BA_ "GenSigStartValue" SG_ 54 VFC_Obj00_Py 8192;
BA_ "GenSigStartValue" SG_ 54 VFC_Obj00_OrientationYaw 256;
BA_ "GenSigStartValue" SG_ 54 VFC_Obj00_Vx 1540;
BA_ "GenSigStartValue" SG_ 54 VFC_Obj00_Vy 512;
BA_ "GenSigStartValue" SG_ 54 VFC_Obj00_Ax 256;
BA_ "GenSigStartValue" SG_ 54 VFC_Obj00_Ay 128;
BA_ "GenSigStartValue" SG_ 54 VFC_Obj00_2DAngPosEdgeLeft 4096;
BA_ "GenSigStartValue" SG_ 54 VFC_Obj00_2DAngPosEdgeRight 4096;
BA_ "GenSigStartValue" SG_ 54 VFC_Obj00_2DAngPosEdgeFar 4096;
BA_ "GenSigStartValue" SG_ 54 VFC_Obj00_2DAngPosEdgeBot 2048;
BA_ "GenSigStartValue" SG_ 54 VFC_Obj00_2DNormVx 40000;
BA_ "GenSigStartValue" SG_ 54 VFC_Obj00_2DNormVy 4096;
BA_ "GenSigStartValue" SG_ 54 VFC_Obj00_2DNormAx 5000;
BA_ "GenSigStartValue" SG_ 55 VFC_Obj01_Py 8192;
BA_ "GenSigStartValue" SG_ 55 VFC_Obj01_OrientationYaw 256;
BA_ "GenSigStartValue" SG_ 55 VFC_Obj01_Vx 1540;
BA_ "GenSigStartValue" SG_ 55 VFC_Obj01_Vy 512;
BA_ "GenSigStartValue" SG_ 55 VFC_Obj01_Ax 256;
BA_ "GenSigStartValue" SG_ 55 VFC_Obj01_Ay 128;
BA_ "GenSigStartValue" SG_ 55 VFC_Obj01_2DAngPosEdgeLeft 4096;
BA_ "GenSigStartValue" SG_ 55 VFC_Obj01_2DAngPosEdgeRight 4096;
BA_ "GenSigStartValue" SG_ 55 VFC_Obj01_2DAngPosEdgeFar 4096;
BA_ "GenSigStartValue" SG_ 55 VFC_Obj01_2DAngPosEdgeBot 2048;
BA_ "GenSigStartValue" SG_ 55 VFC_Obj01_2DNormVx 40000;
BA_ "GenSigStartValue" SG_ 55 VFC_Obj01_2DNormVy 4096;
BA_ "GenSigStartValue" SG_ 55 VFC_Obj01_2DNormAx 5000;
BA_ "GenSigStartValue" SG_ 56 VFC_Obj02_Py 8192;
BA_ "GenSigStartValue" SG_ 56 VFC_Obj02_OrientationYaw 256;
BA_ "GenSigStartValue" SG_ 56 VFC_Obj02_Vx 1540;
BA_ "GenSigStartValue" SG_ 56 VFC_Obj02_Vy 512;
BA_ "GenSigStartValue" SG_ 56 VFC_Obj02_Ax 256;
BA_ "GenSigStartValue" SG_ 56 VFC_Obj02_Ay 128;
BA_ "GenSigStartValue" SG_ 56 VFC_Obj02_2DAngPosEdgeLeft 4096;
BA_ "GenSigStartValue" SG_ 56 VFC_Obj02_2DAngPosEdgeRight 4096;
BA_ "GenSigStartValue" SG_ 56 VFC_Obj02_2DAngPosEdgeFar 4096;
BA_ "GenSigStartValue" SG_ 56 VFC_Obj02_2DAngPosEdgeBot 2048;
BA_ "GenSigStartValue" SG_ 56 VFC_Obj02_2DNormVx 40000;
BA_ "GenSigStartValue" SG_ 56 VFC_Obj02_2DNormVy 4096;
BA_ "GenSigStartValue" SG_ 56 VFC_Obj02_2DNormAx 5000;
BA_ "GenSigStartValue" SG_ 57 VFC_Obj03_Py 8192;
BA_ "GenSigStartValue" SG_ 57 VFC_Obj03_OrientationYaw 256;
BA_ "GenSigStartValue" SG_ 57 VFC_Obj03_Vx 1540;
BA_ "GenSigStartValue" SG_ 57 VFC_Obj03_Vy 512;
BA_ "GenSigStartValue" SG_ 57 VFC_Obj03_Ax 256;
BA_ "GenSigStartValue" SG_ 57 VFC_Obj03_Ay 128;
BA_ "GenSigStartValue" SG_ 57 VFC_Obj03_2DAngPosEdgeLeft 4096;
BA_ "GenSigStartValue" SG_ 57 VFC_Obj03_2DAngPosEdgeRight 4096;
BA_ "GenSigStartValue" SG_ 57 VFC_Obj03_2DAngPosEdgeFar 4096;
BA_ "GenSigStartValue" SG_ 57 VFC_Obj03_2DAngPosEdgeBot 2048;
BA_ "GenSigStartValue" SG_ 57 VFC_Obj03_2DNormVx 40000;
BA_ "GenSigStartValue" SG_ 57 VFC_Obj03_2DNormVy 4096;
BA_ "GenSigStartValue" SG_ 57 VFC_Obj03_2DNormAx 5000;
BA_ "GenSigStartValue" SG_ 58 VFC_Obj04_Py 8192;
BA_ "GenSigStartValue" SG_ 58 VFC_Obj04_OrientationYaw 256;
BA_ "GenSigStartValue" SG_ 58 VFC_Obj04_Vx 1540;
BA_ "GenSigStartValue" SG_ 58 VFC_Obj04_Vy 512;
BA_ "GenSigStartValue" SG_ 58 VFC_Obj04_Ax 256;
BA_ "GenSigStartValue" SG_ 58 VFC_Obj04_Ay 128;
BA_ "GenSigStartValue" SG_ 58 VFC_Obj04_2DAngPosEdgeLeft 4096;
BA_ "GenSigStartValue" SG_ 58 VFC_Obj04_2DAngPosEdgeRight 4096;
BA_ "GenSigStartValue" SG_ 58 VFC_Obj04_2DAngPosEdgeFar 4096;
BA_ "GenSigStartValue" SG_ 58 VFC_Obj04_2DAngPosEdgeBot 2048;
BA_ "GenSigStartValue" SG_ 58 VFC_Obj04_2DNormVx 40000;
BA_ "GenSigStartValue" SG_ 58 VFC_Obj04_2DNormVy 4096;
BA_ "GenSigStartValue" SG_ 58 VFC_Obj04_2DNormAx 5000;
BA_ "GenSigStartValue" SG_ 59 VFC_Obj05_Py 8192;
BA_ "GenSigStartValue" SG_ 59 VFC_Obj05_OrientationYaw 256;
BA_ "GenSigStartValue" SG_ 59 VFC_Obj05_Vx 1540;
BA_ "GenSigStartValue" SG_ 59 VFC_Obj05_Vy 512;
BA_ "GenSigStartValue" SG_ 59 VFC_Obj05_Ax 256;
BA_ "GenSigStartValue" SG_ 59 VFC_Obj05_Ay 128;
BA_ "GenSigStartValue" SG_ 59 VFC_Obj05_2DAngPosEdgeLeft 4096;
BA_ "GenSigStartValue" SG_ 59 VFC_Obj05_2DAngPosEdgeRight 4096;
BA_ "GenSigStartValue" SG_ 59 VFC_Obj05_2DAngPosEdgeFar 4096;
BA_ "GenSigStartValue" SG_ 59 VFC_Obj05_2DAngPosEdgeBot 2048;
BA_ "GenSigStartValue" SG_ 59 VFC_Obj05_2DNormVx 40000;
BA_ "GenSigStartValue" SG_ 59 VFC_Obj05_2DNormVy 4096;
BA_ "GenSigStartValue" SG_ 59 VFC_Obj05_2DNormAx 5000;
BA_ "GenSigStartValue" SG_ 60 VFC_Obj06_Py 8192;
BA_ "GenSigStartValue" SG_ 60 VFC_Obj06_OrientationYaw 256;
BA_ "GenSigStartValue" SG_ 60 VFC_Obj06_Vx 1540;
BA_ "GenSigStartValue" SG_ 60 VFC_Obj06_Vy 512;
BA_ "GenSigStartValue" SG_ 60 VFC_Obj06_Ax 256;
BA_ "GenSigStartValue" SG_ 60 VFC_Obj06_Ay 128;
BA_ "GenSigStartValue" SG_ 60 VFC_Obj06_2DAngPosEdgeLeft 4096;
BA_ "GenSigStartValue" SG_ 60 VFC_Obj06_2DAngPosEdgeRight 4096;
BA_ "GenSigStartValue" SG_ 60 VFC_Obj06_2DAngPosEdgeFar 4096;
BA_ "GenSigStartValue" SG_ 60 VFC_Obj06_2DAngPosEdgeBot 2048;
BA_ "GenSigStartValue" SG_ 60 VFC_Obj06_2DNormVx 40000;
BA_ "GenSigStartValue" SG_ 60 VFC_Obj06_2DNormVy 4096;
BA_ "GenSigStartValue" SG_ 60 VFC_Obj06_2DNormAx 5000;
BA_ "GenSigStartValue" SG_ 61 VFC_Obj07_Py 8192;
BA_ "GenSigStartValue" SG_ 61 VFC_Obj07_OrientationYaw 256;
BA_ "GenSigStartValue" SG_ 61 VFC_Obj07_Vx 1540;
BA_ "GenSigStartValue" SG_ 61 VFC_Obj07_Vy 512;
BA_ "GenSigStartValue" SG_ 61 VFC_Obj07_Ax 256;
BA_ "GenSigStartValue" SG_ 61 VFC_Obj07_Ay 128;
BA_ "GenSigStartValue" SG_ 61 VFC_Obj07_2DAngPosEdgeLeft 4096;
BA_ "GenSigStartValue" SG_ 61 VFC_Obj07_2DAngPosEdgeRight 4096;
BA_ "GenSigStartValue" SG_ 61 VFC_Obj07_2DAngPosEdgeFar 4096;
BA_ "GenSigStartValue" SG_ 61 VFC_Obj07_2DAngPosEdgeBot 2048;
BA_ "GenSigStartValue" SG_ 61 VFC_Obj07_2DNormVx 40000;
BA_ "GenSigStartValue" SG_ 61 VFC_Obj07_2DNormVy 4096;
BA_ "GenSigStartValue" SG_ 61 VFC_Obj07_2DNormAx 5000;
BA_ "GenSigStartValue" SG_ 62 VFC_Obj08_Py 8192;
BA_ "GenSigStartValue" SG_ 62 VFC_Obj08_OrientationYaw 256;
BA_ "GenSigStartValue" SG_ 62 VFC_Obj08_Vx 1540;
BA_ "GenSigStartValue" SG_ 62 VFC_Obj08_Vy 512;
BA_ "GenSigStartValue" SG_ 62 VFC_Obj08_Ax 256;
BA_ "GenSigStartValue" SG_ 62 VFC_Obj08_Ay 128;
BA_ "GenSigStartValue" SG_ 62 VFC_Obj08_2DAngPosEdgeLeft 4096;
BA_ "GenSigStartValue" SG_ 62 VFC_Obj08_2DAngPosEdgeRight 4096;
BA_ "GenSigStartValue" SG_ 62 VFC_Obj08_2DAngPosEdgeFar 4096;
BA_ "GenSigStartValue" SG_ 62 VFC_Obj08_2DAngPosEdgeBot 2048;
BA_ "GenSigStartValue" SG_ 62 VFC_Obj08_2DNormVx 40000;
BA_ "GenSigStartValue" SG_ 62 VFC_Obj08_2DNormVy 4096;
BA_ "GenSigStartValue" SG_ 62 VFC_Obj08_2DNormAx 5000;
BA_ "GenSigStartValue" SG_ 63 VFC_Obj09_Py 8192;
BA_ "GenSigStartValue" SG_ 63 VFC_Obj09_OrientationYaw 256;
BA_ "GenSigStartValue" SG_ 63 VFC_Obj09_Vx 1540;
BA_ "GenSigStartValue" SG_ 63 VFC_Obj09_Vy 512;
BA_ "GenSigStartValue" SG_ 63 VFC_Obj09_Ax 256;
BA_ "GenSigStartValue" SG_ 63 VFC_Obj09_Ay 128;
BA_ "GenSigStartValue" SG_ 63 VFC_Obj09_2DAngPosEdgeLeft 4096;
BA_ "GenSigStartValue" SG_ 63 VFC_Obj09_2DAngPosEdgeRight 4096;
BA_ "GenSigStartValue" SG_ 63 VFC_Obj09_2DAngPosEdgeFar 4096;
BA_ "GenSigStartValue" SG_ 63 VFC_Obj09_2DAngPosEdgeBot 2048;
BA_ "GenSigStartValue" SG_ 63 VFC_Obj09_2DNormVx 40000;
BA_ "GenSigStartValue" SG_ 63 VFC_Obj09_2DNormVy 4096;
BA_ "GenSigStartValue" SG_ 63 VFC_Obj09_2DNormAx 5000;
VAL_ 32 VFC_Status_RollerBenchState 0 "no_roller_bench_mode" 1 "generic_roller_bench_mode" 2 "full_perf_roller_bench_mode" 3 "Reserved3" ;
VAL_ 32 VFC_Status_SensorState 0 "Camera SysFullOperational" 1 "Camera Initialization" 2 "Camera Limited (reduced Mode)" 3 "Camera TemporaryBlocked" 4 "Camera StableBlocked" 5 "Camera Error" 6 "Camera CalibrationOnGoing" 7 "Camera Decalibrated" 8 "Camera Shutdown" 9 "Reserved9" 10 "Reserved10" 11 "Reserved11" 12 "Reserved12" 13 "Reserved13" 14 "Reserved14" 15 "Reserved15" ;
VAL_ 32 VFC_Status_CalibrationState 0 "OK" 1 "NOK" 2 "INIT" 3 "Undefined" 4 "Reserved4" 5 "Reserved5" 6 "Reserved6" 7 "Reserved7" ;
VAL_ 32 VFC_Status_TrafficFlowType 0 "Right_Hand_Traffic" 1 "Left_Hand_Traffic" ;
VAL_ 33 RFC_Status_ModulationStatus 0 "Normal operation" 1 "Time sync failure" 2 "Modulation failure" 3 "Reserved" ;
VAL_ 52 VFC_ObjHdr_SensorStatus 0 "off" 1 "on" 2 "Reserved2" 3 "Reserved3" 4 "Reserved4" 5 "Reserved5" 6 "Reserved6" 7 "Reserved7" ;
VAL_ 54 VFC_Obj00_MeasurementStatus 0 "Invalid" 1 "Measured" 2 "Predicted" 3 "Reserved3" ;
VAL_ 54 VFC_Obj00_ObjId 0 "INVALID" ;
VAL_ 54 VFC_Obj00_Type 0 "NOTYPE" 1 "CAR" 2 "RESERVED02" 3 "TRUCK" 4 "RESERVED04" 5 "RESERVED05" 6 "MOTORCYCLIST" 7 "PEDESTRIAN" 8 "CYCLIST" 9 "BOLLARD" 10 "ROADPOST" 11 "ARROWPOST" 12 "RESERVED12" 13 "RESERVED13" 14 "RESERVED14" 15 "RESERVED15" ;
VAL_ 54 VFC_Obj00_VisibleView 0 "UNKNOWN" 1 "CLASSIC" 2 "SIDE" 3 "CLASSIC_LSHAPE" 4 "SIDE_LSHAPE" 5 "Reserved5" 6 "Reserved6" 7 "Reserved7" ;
VAL_ 54 VFC_Obj00_ClassifiedView 0 "Unknown" 1 "Front" 2 "Rear" 3 "Left" 4 "Right" 5 "Reserved5" 6 "Reserved6" 7 "Reserved7" ;
VAL_ 54 VFC_Obj00_LightStatTurnIndicator 0 "Unknown" 1 "No direction indicator" 2 "Left indicator" 3 "Right indicator" 4 "Warning Lights" 5 "Reserved5" 6 "Reserved6" 7 "Reserved7" ;
VAL_ 54 VFC_Obj00_LightStatBrakeLight 0 "Unknown" 1 "No light detected" 2 "One light detected" 3 "Two lights detected" 4 "Three lights detected" 5 "Reserved5" 6 "Reserved6" 7 "Reserved7" ;
VAL_ 54 VFC_Obj00_OutsideRoadMeasStatus 0 "Invalid" 1 "Measured" 2 "Predicted" 3 "Reserved3" ;
VAL_ 54 VFC_Obj00_OncomingMeasStatus 0 "Invalid" 1 "Measured" 2 "Predicted" 3 "Reserved3" ;
VAL_ 54 VFC_Obj00_MovementStandingMeasSt 0 "Invalid" 1 "Measured" 2 "Predicted" 3 "Reserved3" ;
VAL_ 54 VFC_Obj00_MovementObservedMeasSt 0 "Invalid" 1 "Valid" ;
VAL_ 54 VFC_Obj00_TargetObjTypeAcc 0 "No_target_object" 1 "Ego_0" 2 "Ego_1" 3 "Left_0" 4 "Left_1" 5 "Right_0" 6 "Right_1" 7 "Reserved7" ;
VAL_ 55 VFC_Obj01_MeasurementStatus 0 "Invalid" 1 "Measured" 2 "Predicted" 3 "Reserved3" ;
VAL_ 55 VFC_Obj01_ObjId 0 "INVALID" ;
VAL_ 55 VFC_Obj01_Type 0 "NOTYPE" 1 "CAR" 2 "RESERVED02" 3 "TRUCK" 4 "RESERVED04" 5 "RESERVED05" 6 "MOTORCYCLIST" 7 "PEDESTRIAN" 8 "CYCLIST" 9 "BOLLARD" 10 "ROADPOST" 11 "ARROWPOST" 12 "RESERVED12" 13 "RESERVED13" 14 "RESERVED14" 15 "RESERVED15" ;
VAL_ 55 VFC_Obj01_VisibleView 0 "UNKNOWN" 1 "CLASSIC" 2 "SIDE" 3 "CLASSIC_LSHAPE" 4 "SIDE_LSHAPE" 5 "Reserved5" 6 "Reserved6" 7 "Reserved7" ;
VAL_ 55 VFC_Obj01_ClassifiedView 0 "Unknown" 1 "Front" 2 "Rear" 3 "Left" 4 "Right" 5 "Reserved5" 6 "Reserved6" 7 "Reserved7" ;
VAL_ 55 VFC_Obj01_LightStatTurnIndicator 0 "Unknown" 1 "No direction indicator" 2 "Left indicator" 3 "Right indicator" 4 "Warning Lights" 5 "Reserved5" 6 "Reserved6" 7 "Reserved7" ;
VAL_ 55 VFC_Obj01_LightStatBrakeLight 0 "Unknown" 1 "No light detected" 2 "One light detected" 3 "Two lights detected" 4 "Three lights detected" 5 "Reserved5" 6 "Reserved6" 7 "Reserved7" ;
VAL_ 55 VFC_Obj01_OutsideRoadMeasStatus 0 "Invalid" 1 "Measured" 2 "Predicted" 3 "Reserved3" ;
VAL_ 55 VFC_Obj01_OncomingMeasStatus 0 "Invalid" 1 "Measured" 2 "Predicted" 3 "Reserved3" ;
VAL_ 55 VFC_Obj01_MovementStandingMeasSt 0 "Invalid" 1 "Measured" 2 "Predicted" 3 "Reserved3" ;
VAL_ 55 VFC_Obj01_MovementObservedMeasSt 0 "Invalid" 1 "Valid" ;
VAL_ 55 VFC_Obj01_TargetObjTypeAcc 0 "No_target_object" 1 "Ego_0" 2 "Ego_1" 3 "Left_0" 4 "Left_1" 5 "Right_0" 6 "Right_1" 7 "Reserved7" ;
VAL_ 56 VFC_Obj02_MeasurementStatus 0 "Invalid" 1 "Measured" 2 "Predicted" 3 "Reserved3" ;
VAL_ 56 VFC_Obj02_ObjId 0 "INVALID" ;
VAL_ 56 VFC_Obj02_Type 0 "NOTYPE" 1 "CAR" 2 "RESERVED02" 3 "TRUCK" 4 "RESERVED04" 5 "RESERVED05" 6 "MOTORCYCLIST" 7 "PEDESTRIAN" 8 "CYCLIST" 9 "BOLLARD" 10 "ROADPOST" 11 "ARROWPOST" 12 "RESERVED12" 13 "RESERVED13" 14 "RESERVED14" 15 "RESERVED15" ;
VAL_ 56 VFC_Obj02_VisibleView 0 "UNKNOWN" 1 "CLASSIC" 2 "SIDE" 3 "CLASSIC_LSHAPE" 4 "SIDE_LSHAPE" 5 "Reserved5" 6 "Reserved6" 7 "Reserved7" ;
VAL_ 56 VFC_Obj02_ClassifiedView 0 "Unknown" 1 "Front" 2 "Rear" 3 "Left" 4 "Right" 5 "Reserved5" 6 "Reserved6" 7 "Reserved7" ;
VAL_ 56 VFC_Obj02_LightStatTurnIndicator 0 "Unknown" 1 "No direction indicator" 2 "Left indicator" 3 "Right indicator" 4 "Warning Lights" 5 "Reserved5" 6 "Reserved6" 7 "Reserved7" ;
VAL_ 56 VFC_Obj02_LightStatBrakeLight 0 "Unknown" 1 "No light detected" 2 "One light detected" 3 "Two lights detected" 4 "Three lights detected" 5 "Reserved5" 6 "Reserved6" 7 "Reserved7" ;
VAL_ 56 VFC_Obj02_OutsideRoadMeasStatus 0 "Invalid" 1 "Measured" 2 "Predicted" 3 "Reserved3" ;
VAL_ 56 VFC_Obj02_OncomingMeasStatus 0 "Invalid" 1 "Measured" 2 "Predicted" 3 "Reserved3" ;
VAL_ 56 VFC_Obj02_MovementStandingMeasSt 0 "Invalid" 1 "Measured" 2 "Predicted" 3 "Reserved3" ;
VAL_ 56 VFC_Obj02_MovementObservedMeasSt 0 "Invalid" 1 "Valid" ;
VAL_ 56 VFC_Obj02_TargetObjTypeAcc 0 "No_target_object" 1 "Ego_0" 2 "Ego_1" 3 "Left_0" 4 "Left_1" 5 "Right_0" 6 "Right_1" 7 "Reserved7" ;
VAL_ 57 VFC_Obj03_MeasurementStatus 0 "Invalid" 1 "Measured" 2 "Predicted" 3 "Reserved3" ;
VAL_ 57 VFC_Obj03_ObjId 0 "INVALID" ;
VAL_ 57 VFC_Obj03_Type 0 "NOTYPE" 1 "CAR" 2 "RESERVED02" 3 "TRUCK" 4 "RESERVED04" 5 "RESERVED05" 6 "MOTORCYCLIST" 7 "PEDESTRIAN" 8 "CYCLIST" 9 "BOLLARD" 10 "ROADPOST" 11 "ARROWPOST" 12 "RESERVED12" 13 "RESERVED13" 14 "RESERVED14" 15 "RESERVED15" ;
VAL_ 57 VFC_Obj03_VisibleView 0 "UNKNOWN" 1 "CLASSIC" 2 "SIDE" 3 "CLASSIC_LSHAPE" 4 "SIDE_LSHAPE" 5 "Reserved5" 6 "Reserved6" 7 "Reserved7" ;
VAL_ 57 VFC_Obj03_ClassifiedView 0 "Unknown" 1 "Front" 2 "Rear" 3 "Left" 4 "Right" 5 "Reserved5" 6 "Reserved6" 7 "Reserved7" ;
VAL_ 57 VFC_Obj03_LightStatTurnIndicator 0 "Unknown" 1 "No direction indicator" 2 "Left indicator" 3 "Right indicator" 4 "Warning Lights" 5 "Reserved5" 6 "Reserved6" 7 "Reserved7" ;
VAL_ 57 VFC_Obj03_LightStatBrakeLight 0 "Unknown" 1 "No light detected" 2 "One light detected" 3 "Two lights detected" 4 "Three lights detected" 5 "Reserved5" 6 "Reserved6" 7 "Reserved7" ;
VAL_ 57 VFC_Obj03_OutsideRoadMeasStatus 0 "Invalid" 1 "Measured" 2 "Predicted" 3 "Reserved3" ;
VAL_ 57 VFC_Obj03_OncomingMeasStatus 0 "Invalid" 1 "Measured" 2 "Predicted" 3 "Reserved3" ;
VAL_ 57 VFC_Obj03_MovementStandingMeasSt 0 "Invalid" 1 "Measured" 2 "Predicted" 3 "Reserved3" ;
VAL_ 57 VFC_Obj03_MovementObservedMeasSt 0 "Invalid" 1 "Valid" ;
VAL_ 57 VFC_Obj03_TargetObjTypeAcc 0 "No_target_object" 1 "Ego_0" 2 "Ego_1" 3 "Left_0" 4 "Left_1" 5 "Right_0" 6 "Right_1" 7 "Reserved7" ;
VAL_ 58 VFC_Obj04_MeasurementStatus 0 "Invalid" 1 "Measured" 2 "Predicted" 3 "Reserved3" ;
VAL_ 58 VFC_Obj04_ObjId 0 "INVALID" ;
VAL_ 58 VFC_Obj04_Type 0 "NOTYPE" 1 "CAR" 2 "RESERVED02" 3 "TRUCK" 4 "RESERVED04" 5 "RESERVED05" 6 "MOTORCYCLIST" 7 "PEDESTRIAN" 8 "CYCLIST" 9 "BOLLARD" 10 "ROADPOST" 11 "ARROWPOST" 12 "RESERVED12" 13 "RESERVED13" 14 "RESERVED14" 15 "RESERVED15" ;
VAL_ 58 VFC_Obj04_VisibleView 0 "UNKNOWN" 1 "CLASSIC" 2 "SIDE" 3 "CLASSIC_LSHAPE" 4 "SIDE_LSHAPE" 5 "Reserved5" 6 "Reserved6" 7 "Reserved7" ;
VAL_ 58 VFC_Obj04_ClassifiedView 0 "Unknown" 1 "Front" 2 "Rear" 3 "Left" 4 "Right" 5 "Reserved5" 6 "Reserved6" 7 "Reserved7" ;
VAL_ 58 VFC_Obj04_LightStatTurnIndicator 0 "Unknown" 1 "No direction indicator" 2 "Left indicator" 3 "Right indicator" 4 "Warning Lights" 5 "Reserved5" 6 "Reserved6" 7 "Reserved7" ;
VAL_ 58 VFC_Obj04_LightStatBrakeLight 0 "Unknown" 1 "No light detected" 2 "One light detected" 3 "Two lights detected" 4 "Three lights detected" 5 "Reserved5" 6 "Reserved6" 7 "Reserved7" ;
VAL_ 58 VFC_Obj04_OutsideRoadMeasStatus 0 "Invalid" 1 "Measured" 2 "Predicted" 3 "Reserved3" ;
VAL_ 58 VFC_Obj04_OncomingMeasStatus 0 "Invalid" 1 "Measured" 2 "Predicted" 3 "Reserved3" ;
VAL_ 58 VFC_Obj04_MovementStandingMeasSt 0 "Invalid" 1 "Measured" 2 "Predicted" 3 "Reserved3" ;
VAL_ 58 VFC_Obj04_MovementObservedMeasSt 0 "Invalid" 1 "Valid" ;
VAL_ 58 VFC_Obj04_TargetObjTypeAcc 0 "No_target_object" 1 "Ego_0" 2 "Ego_1" 3 "Left_0" 4 "Left_1" 5 "Right_0" 6 "Right_1" 7 "Reserved7" ;
VAL_ 59 VFC_Obj05_MeasurementStatus 0 "Invalid" 1 "Measured" 2 "Predicted" 3 "Reserved3" ;
VAL_ 59 VFC_Obj05_ObjId 0 "INVALID" ;
VAL_ 59 VFC_Obj05_Type 0 "NOTYPE" 1 "CAR" 2 "RESERVED02" 3 "TRUCK" 4 "RESERVED04" 5 "RESERVED05" 6 "MOTORCYCLIST" 7 "PEDESTRIAN" 8 "CYCLIST" 9 "BOLLARD" 10 "ROADPOST" 11 "ARROWPOST" 12 "RESERVED12" 13 "RESERVED13" 14 "RESERVED14" 15 "RESERVED15" ;
VAL_ 59 VFC_Obj05_VisibleView 0 "UNKNOWN" 1 "CLASSIC" 2 "SIDE" 3 "CLASSIC_LSHAPE" 4 "SIDE_LSHAPE" 5 "Reserved5" 6 "Reserved6" 7 "Reserved7" ;
VAL_ 59 VFC_Obj05_ClassifiedView 0 "Unknown" 1 "Front" 2 "Rear" 3 "Left" 4 "Right" 5 "Reserved5" 6 "Reserved6" 7 "Reserved7" ;
VAL_ 59 VFC_Obj05_LightStatTurnIndicator 0 "Unknown" 1 "No direction indicator" 2 "Left indicator" 3 "Right indicator" 4 "Warning Lights" 5 "Reserved5" 6 "Reserved6" 7 "Reserved7" ;
VAL_ 59 VFC_Obj05_LightStatBrakeLight 0 "Unknown" 1 "No light detected" 2 "One light detected" 3 "Two lights detected" 4 "Three lights detected" 5 "Reserved5" 6 "Reserved6" 7 "Reserved7" ;
VAL_ 59 VFC_Obj05_OutsideRoadMeasStatus 0 "Invalid" 1 "Measured" 2 "Predicted" 3 "Reserved3" ;
VAL_ 59 VFC_Obj05_OncomingMeasStatus 0 "Invalid" 1 "Measured" 2 "Predicted" 3 "Reserved3" ;
VAL_ 59 VFC_Obj05_MovementStandingMeasSt 0 "Invalid" 1 "Measured" 2 "Predicted" 3 "Reserved3" ;
VAL_ 59 VFC_Obj05_MovementObservedMeasSt 0 "Invalid" 1 "Valid" ;
VAL_ 59 VFC_Obj05_TargetObjTypeAcc 0 "No_target_object" 1 "Ego_0" 2 "Ego_1" 3 "Left_0" 4 "Left_1" 5 "Right_0" 6 "Right_1" 7 "Reserved7" ;
VAL_ 60 VFC_Obj06_MeasurementStatus 0 "Invalid" 1 "Measured" 2 "Predicted" 3 "Reserved3" ;
VAL_ 60 VFC_Obj06_ObjId 0 "INVALID" ;
VAL_ 60 VFC_Obj06_Type 0 "NOTYPE" 1 "CAR" 2 "RESERVED02" 3 "TRUCK" 4 "RESERVED04" 5 "RESERVED05" 6 "MOTORCYCLIST" 7 "PEDESTRIAN" 8 "CYCLIST" 9 "BOLLARD" 10 "ROADPOST" 11 "ARROWPOST" 12 "RESERVED12" 13 "RESERVED13" 14 "RESERVED14" 15 "RESERVED15" ;
VAL_ 60 VFC_Obj06_VisibleView 0 "UNKNOWN" 1 "CLASSIC" 2 "SIDE" 3 "CLASSIC_LSHAPE" 4 "SIDE_LSHAPE" 5 "Reserved5" 6 "Reserved6" 7 "Reserved7" ;
VAL_ 60 VFC_Obj06_ClassifiedView 0 "Unknown" 1 "Front" 2 "Rear" 3 "Left" 4 "Right" 5 "Reserved5" 6 "Reserved6" 7 "Reserved7" ;
VAL_ 60 VFC_Obj06_LightStatTurnIndicator 0 "Unknown" 1 "No direction indicator" 2 "Left indicator" 3 "Right indicator" 4 "Warning Lights" 5 "Reserved5" 6 "Reserved6" 7 "Reserved7" ;
VAL_ 60 VFC_Obj06_LightStatBrakeLight 0 "Unknown" 1 "No light detected" 2 "One light detected" 3 "Two lights detected" 4 "Three lights detected" 5 "Reserved5" 6 "Reserved6" 7 "Reserved7" ;
VAL_ 60 VFC_Obj06_OutsideRoadMeasStatus 0 "Invalid" 1 "Measured" 2 "Predicted" 3 "Reserved3" ;
VAL_ 60 VFC_Obj06_OncomingMeasStatus 0 "Invalid" 1 "Measured" 2 "Predicted" 3 "Reserved3" ;
VAL_ 60 VFC_Obj06_MovementStandingMeasSt 0 "Invalid" 1 "Measured" 2 "Predicted" 3 "Reserved3" ;
VAL_ 60 VFC_Obj06_MovementObservedMeasSt 0 "Invalid" 1 "Valid" ;
VAL_ 60 VFC_Obj06_TargetObjTypeAcc 0 "No_target_object" 1 "Ego_0" 2 "Ego_1" 3 "Left_0" 4 "Left_1" 5 "Right_0" 6 "Right_1" 7 "Reserved7" ;
VAL_ 61 VFC_Obj07_MeasurementStatus 0 "Invalid" 1 "Measured" 2 "Predicted" 3 "Reserved3" ;
VAL_ 61 VFC_Obj07_ObjId 0 "INVALID" ;
VAL_ 61 VFC_Obj07_Type 0 "NOTYPE" 1 "CAR" 2 "RESERVED02" 3 "TRUCK" 4 "RESERVED04" 5 "RESERVED05" 6 "MOTORCYCLIST" 7 "PEDESTRIAN" 8 "CYCLIST" 9 "BOLLARD" 10 "ROADPOST" 11 "ARROWPOST" 12 "RESERVED12" 13 "RESERVED13" 14 "RESERVED14" 15 "RESERVED15" ;
VAL_ 61 VFC_Obj07_VisibleView 0 "UNKNOWN" 1 "CLASSIC" 2 "SIDE" 3 "CLASSIC_LSHAPE" 4 "SIDE_LSHAPE" 5 "Reserved5" 6 "Reserved6" 7 "Reserved7" ;
VAL_ 61 VFC_Obj07_ClassifiedView 0 "Unknown" 1 "Front" 2 "Rear" 3 "Left" 4 "Right" 5 "Reserved5" 6 "Reserved6" 7 "Reserved7" ;
VAL_ 61 VFC_Obj07_LightStatTurnIndicator 0 "Unknown" 1 "No direction indicator" 2 "Left indicator" 3 "Right indicator" 4 "Warning Lights" 5 "Reserved5" 6 "Reserved6" 7 "Reserved7" ;
VAL_ 61 VFC_Obj07_LightStatBrakeLight 0 "Unknown" 1 "No light detected" 2 "One light detected" 3 "Two lights detected" 4 "Three lights detected" 5 "Reserved5" 6 "Reserved6" 7 "Reserved7" ;
VAL_ 61 VFC_Obj07_OutsideRoadMeasStatus 0 "Invalid" 1 "Measured" 2 "Predicted" 3 "Reserved3" ;
VAL_ 61 VFC_Obj07_OncomingMeasStatus 0 "Invalid" 1 "Measured" 2 "Predicted" 3 "Reserved3" ;
VAL_ 61 VFC_Obj07_MovementStandingMeasSt 0 "Invalid" 1 "Measured" 2 "Predicted" 3 "Reserved3" ;
VAL_ 61 VFC_Obj07_MovementObservedMeasSt 0 "Invalid" 1 "Valid" ;
VAL_ 61 VFC_Obj07_TargetObjTypeAcc 0 "No_target_object" 1 "Ego_0" 2 "Ego_1" 3 "Left_0" 4 "Left_1" 5 "Right_0" 6 "Right_1" 7 "Reserved7" ;
VAL_ 62 VFC_Obj08_MeasurementStatus 0 "Invalid" 1 "Measured" 2 "Predicted" 3 "Reserved3" ;
VAL_ 62 VFC_Obj08_ObjId 0 "INVALID" ;
VAL_ 62 VFC_Obj08_Type 0 "NOTYPE" 1 "CAR" 2 "RESERVED02" 3 "TRUCK" 4 "RESERVED04" 5 "RESERVED05" 6 "MOTORCYCLIST" 7 "PEDESTRIAN" 8 "CYCLIST" 9 "BOLLARD" 10 "ROADPOST" 11 "ARROWPOST" 12 "RESERVED12" 13 "RESERVED13" 14 "RESERVED14" 15 "RESERVED15" ;
VAL_ 62 VFC_Obj08_VisibleView 0 "UNKNOWN" 1 "CLASSIC" 2 "SIDE" 3 "CLASSIC_LSHAPE" 4 "SIDE_LSHAPE" 5 "Reserved5" 6 "Reserved6" 7 "Reserved7" ;
VAL_ 62 VFC_Obj08_ClassifiedView 0 "Unknown" 1 "Front" 2 "Rear" 3 "Left" 4 "Right" 5 "Reserved5" 6 "Reserved6" 7 "Reserved7" ;
VAL_ 62 VFC_Obj08_LightStatTurnIndicator 0 "Unknown" 1 "No direction indicator" 2 "Left indicator" 3 "Right indicator" 4 "Warning Lights" 5 "Reserved5" 6 "Reserved6" 7 "Reserved7" ;
VAL_ 62 VFC_Obj08_LightStatBrakeLight 0 "Unknown" 1 "No light detected" 2 "One light detected" 3 "Two lights detected" 4 "Three lights detected" 5 "Reserved5" 6 "Reserved6" 7 "Reserved7" ;
VAL_ 62 VFC_Obj08_OutsideRoadMeasStatus 0 "Invalid" 1 "Measured" 2 "Predicted" 3 "Reserved3" ;
VAL_ 62 VFC_Obj08_OncomingMeasStatus 0 "Invalid" 1 "Measured" 2 "Predicted" 3 "Reserved3" ;
VAL_ 62 VFC_Obj08_MovementStandingMeasSt 0 "Invalid" 1 "Measured" 2 "Predicted" 3 "Reserved3" ;
VAL_ 62 VFC_Obj08_MovementObservedMeasSt 0 "Invalid" 1 "Valid" ;
VAL_ 62 VFC_Obj08_TargetObjTypeAcc 0 "No_target_object" 1 "Ego_0" 2 "Ego_1" 3 "Left_0" 4 "Left_1" 5 "Right_0" 6 "Right_1" 7 "Reserved7" ;
VAL_ 63 VFC_Obj09_MeasurementStatus 0 "Invalid" 1 "Measured" 2 "Predicted" 3 "Reserved3" ;
VAL_ 63 VFC_Obj09_ObjId 0 "INVALID" ;
VAL_ 63 VFC_Obj09_Type 0 "NOTYPE" 1 "CAR" 2 "RESERVED02" 3 "TRUCK" 4 "RESERVED04" 5 "RESERVED05" 6 "MOTORCYCLIST" 7 "PEDESTRIAN" 8 "CYCLIST" 9 "BOLLARD" 10 "ROADPOST" 11 "ARROWPOST" 12 "RESERVED12" 13 "RESERVED13" 14 "RESERVED14" 15 "RESERVED15" ;
VAL_ 63 VFC_Obj09_VisibleView 0 "UNKNOWN" 1 "CLASSIC" 2 "SIDE" 3 "CLASSIC_LSHAPE" 4 "SIDE_LSHAPE" 5 "Reserved5" 6 "Reserved6" 7 "Reserved7" ;
VAL_ 63 VFC_Obj09_ClassifiedView 0 "Unknown" 1 "Front" 2 "Rear" 3 "Left" 4 "Right" 5 "Reserved5" 6 "Reserved6" 7 "Reserved7" ;
VAL_ 63 VFC_Obj09_LightStatTurnIndicator 0 "Unknown" 1 "No direction indicator" 2 "Left indicator" 3 "Right indicator" 4 "Warning Lights" 5 "Reserved5" 6 "Reserved6" 7 "Reserved7" ;
VAL_ 63 VFC_Obj09_LightStatBrakeLight 0 "Unknown" 1 "No light detected" 2 "One light detected" 3 "Two lights detected" 4 "Three lights detected" 5 "Reserved5" 6 "Reserved6" 7 "Reserved7" ;
VAL_ 63 VFC_Obj09_OutsideRoadMeasStatus 0 "Invalid" 1 "Measured" 2 "Predicted" 3 "Reserved3" ;
VAL_ 63 VFC_Obj09_OncomingMeasStatus 0 "Invalid" 1 "Measured" 2 "Predicted" 3 "Reserved3" ;
VAL_ 63 VFC_Obj09_MovementStandingMeasSt 0 "Invalid" 1 "Measured" 2 "Predicted" 3 "Reserved3" ;
VAL_ 63 VFC_Obj09_MovementObservedMeasSt 0 "Invalid" 1 "Valid" ;
VAL_ 63 VFC_Obj09_TargetObjTypeAcc 0 "No_target_object" 1 "Ego_0" 2 "Ego_1" 3 "Left_0" 4 "Left_1" 5 "Right_0" 6 "Right_1" 7 "Reserved7" ;
SIG_GROUP_ 16 SG_VFC_AEB_Request 1 : VFC_AEB_CRC VFC_AEB_AC VFC_AEB_FPC VFC_AEB_CU VFC_AEB_VRU VFC_AEB_VRUTA VFC_AEB_LTA VFC_Ax_CommandValue VFC_AEB_ObjID VFC_AEB_DummyForFuture;
SIG_GROUP_ 32 SG_VFC_Status 1 : VFC_Status_CRC VFC_Status_AliveCtr VFC_Status_SensorOrientYaw VFC_Status_SensorOrientPitch VFC_Status_SensorOrientRoll VFC_Status_TimeStampStatus VFC_Status_TimeStamp VFC_Status_FrameNumber VFC_Status_SensorOriginPointX VFC_Status_SensorOriginPointY VFC_Status_SensorOriginPointZ VFC_Status_RollerBenchState VFC_Status_SensorState VFC_Status_CalibrationState VFC_Status_TrafficFlowType;
SIG_GROUP_ 33 SG_RFC_Status 1 : RFC_Status_CRC RFC_Status_AliveCtr RFC_Status_ModulationStatus RFC_Status_SensorStatus;
SIG_GROUP_ 52 SG_VFC_ObjectHdr 1 : VFC_ObjHdr_CRC VFC_ObjHdr_AliveCtr VFC_ObjHdr_ProtBlockCtr VFC_ObjHdr_IfVersionIdMajor VFC_ObjHdr_IfVersionIdMinor VFC_ObjHdr_NumValidObjects VFC_ObjHdr_TimeStampStatus VFC_ObjHdr_TimeStamp VFC_ObjHdr_SensorStatus VFC_ObjHdr_FocalLengthX VFC_ObjHdr_FocalLengthY VFC_ObjHdr_PrincipalPointU VFC_ObjHdr_PrincipalPointV;
SIG_GROUP_ 54 SG_VFC_Object00 1 : VFC_Obj00_CRC VFC_Obj00_AliveCtr VFC_Obj00_ProtBlockCtr VFC_Obj00_ExistProb VFC_Obj00_MeasurementStatus VFC_Obj00_ObjId VFC_Obj00_Type VFC_Obj00_TypeConf VFC_Obj00_VisibleView VFC_Obj00_ClassifiedView VFC_Obj00_Px VFC_Obj00_Py VFC_Obj00_PxStdDev VFC_Obj00_PyStdDev VFC_Obj00_OrientationYaw VFC_Obj00_OrientationYawStdDev VFC_Obj00_Length VFC_Obj00_Width VFC_Obj00_Height VFC_Obj00_LengthStdDev VFC_Obj00_WidthStdDev VFC_Obj00_HeightStdDev VFC_Obj00_Vx VFC_Obj00_Vy VFC_Obj00_VxStdDev VFC_Obj00_VyStdDev VFC_Obj00_Ax VFC_Obj00_LightStatTurnIndicator VFC_Obj00_Ay VFC_Obj00_AxStdDev VFC_Obj00_AyStdDev VFC_Obj00_MovementProbLat VFC_Obj00_MovementProbLong VFC_Obj00_2DAngPosEdgeLeft VFC_Obj00_2DAngPosEdgeRight VFC_Obj00_2DAngPosEdgeFar VFC_Obj00_2DAngPosEdgeBot VFC_Obj00_OutsideRoad VFC_Obj00_2DAngPosEdgeLeftStdDev VFC_Obj00_2DAngPosEdgeRightStdDe VFC_Obj00_2DAngPosEdgeFarStdDev VFC_Obj00_2DAngPosEdgeBotStdDev VFC_Obj00_2DNormVx VFC_Obj00_2DNormVy VFC_Obj00_2DNormAx VFC_Obj00_2DNormVxStdDev VFC_Obj00_MeasurementSource VFC_Obj00_2DNormVyStdDev VFC_Obj00_2DNormAxStdDev VFC_Obj00_2DScaleChange VFC_Obj00_2DScaleChangeStdDev VFC_Obj00_Reliability VFC_Obj00_LightStatBrakeLight VFC_Obj00_OutsideRoadMeasStatus VFC_Obj00_Oncoming VFC_Obj00_OncomingMeasStatus VFC_Obj00_MovementStanding VFC_Obj00_MovementStandingMeasSt VFC_Obj00_MovementObserved VFC_Obj00_MovementObservedMeasSt VFC_Obj00_TargetObjTypeAcc VFC_Obj00_TargetObjTypeAccConf;
SIG_GROUP_ 55 SG_VFC_Object01 1 : VFC_Obj01_CRC VFC_Obj01_AliveCtr VFC_Obj01_ProtBlockCtr VFC_Obj01_ExistProb VFC_Obj01_MeasurementStatus VFC_Obj01_ObjId VFC_Obj01_Type VFC_Obj01_TypeConf VFC_Obj01_VisibleView VFC_Obj01_ClassifiedView VFC_Obj01_Px VFC_Obj01_Py VFC_Obj01_PxStdDev VFC_Obj01_PyStdDev VFC_Obj01_OrientationYaw VFC_Obj01_OrientationYawStdDev VFC_Obj01_Length VFC_Obj01_Width VFC_Obj01_Height VFC_Obj01_LengthStdDev VFC_Obj01_WidthStdDev VFC_Obj01_HeightStdDev VFC_Obj01_Vx VFC_Obj01_Vy VFC_Obj01_VxStdDev VFC_Obj01_VyStdDev VFC_Obj01_Ax VFC_Obj01_LightStatTurnIndicator VFC_Obj01_Ay VFC_Obj01_AxStdDev VFC_Obj01_AyStdDev VFC_Obj01_MovementProbLat VFC_Obj01_MovementProbLong VFC_Obj01_2DAngPosEdgeLeft VFC_Obj01_2DAngPosEdgeRight VFC_Obj01_2DAngPosEdgeFar VFC_Obj01_2DAngPosEdgeBot VFC_Obj01_OutsideRoad VFC_Obj01_2DAngPosEdgeLeftStdDev VFC_Obj01_2DAngPosEdgeRightStdDe VFC_Obj01_2DAngPosEdgeFarStdDev VFC_Obj01_2DAngPosEdgeBotStdDev VFC_Obj01_2DNormVx VFC_Obj01_2DNormVy VFC_Obj01_2DNormAx VFC_Obj01_2DNormVxStdDev VFC_Obj01_MeasurementSource VFC_Obj01_2DNormVyStdDev VFC_Obj01_2DNormAxStdDev VFC_Obj01_2DScaleChange VFC_Obj01_2DScaleChangeStdDev VFC_Obj01_Reliability VFC_Obj01_LightStatBrakeLight VFC_Obj01_OutsideRoadMeasStatus VFC_Obj01_Oncoming VFC_Obj01_OncomingMeasStatus VFC_Obj01_MovementStanding VFC_Obj01_MovementStandingMeasSt VFC_Obj01_MovementObserved VFC_Obj01_MovementObservedMeasSt VFC_Obj01_TargetObjTypeAcc VFC_Obj01_TargetObjTypeAccConf;
SIG_GROUP_ 56 SG_VFC_Object02 1 : VFC_Obj02_CRC VFC_Obj02_AliveCtr VFC_Obj02_ProtBlockCtr VFC_Obj02_ExistProb VFC_Obj02_MeasurementStatus VFC_Obj02_ObjId VFC_Obj02_Type VFC_Obj02_TypeConf VFC_Obj02_VisibleView VFC_Obj02_ClassifiedView VFC_Obj02_Px VFC_Obj02_Py VFC_Obj02_PxStdDev VFC_Obj02_PyStdDev VFC_Obj02_OrientationYaw VFC_Obj02_OrientationYawStdDev VFC_Obj02_Length VFC_Obj02_Width VFC_Obj02_Height VFC_Obj02_LengthStdDev VFC_Obj02_WidthStdDev VFC_Obj02_HeightStdDev VFC_Obj02_Vx VFC_Obj02_Vy VFC_Obj02_VxStdDev VFC_Obj02_VyStdDev VFC_Obj02_Ax VFC_Obj02_LightStatTurnIndicator VFC_Obj02_Ay VFC_Obj02_AxStdDev VFC_Obj02_AyStdDev VFC_Obj02_MovementProbLat VFC_Obj02_MovementProbLong VFC_Obj02_2DAngPosEdgeLeft VFC_Obj02_2DAngPosEdgeRight VFC_Obj02_2DAngPosEdgeFar VFC_Obj02_2DAngPosEdgeBot VFC_Obj02_OutsideRoad VFC_Obj02_2DAngPosEdgeLeftStdDev VFC_Obj02_2DAngPosEdgeRightStdDe VFC_Obj02_2DAngPosEdgeFarStdDev VFC_Obj02_2DAngPosEdgeBotStdDev VFC_Obj02_2DNormVx VFC_Obj02_2DNormVy VFC_Obj02_2DNormAx VFC_Obj02_2DNormVxStdDev VFC_Obj02_MeasurementSource VFC_Obj02_2DNormVyStdDev VFC_Obj02_2DNormAxStdDev VFC_Obj02_2DScaleChange VFC_Obj02_2DScaleChangeStdDev VFC_Obj02_Reliability VFC_Obj02_LightStatBrakeLight VFC_Obj02_OutsideRoadMeasStatus VFC_Obj02_Oncoming VFC_Obj02_OncomingMeasStatus VFC_Obj02_MovementStanding VFC_Obj02_MovementStandingMeasSt VFC_Obj02_MovementObserved VFC_Obj02_MovementObservedMeasSt VFC_Obj02_TargetObjTypeAcc VFC_Obj02_TargetObjTypeAccConf;
SIG_GROUP_ 57 SG_VFC_Object03 1 : VFC_Obj03_CRC VFC_Obj03_AliveCtr VFC_Obj03_ProtBlockCtr VFC_Obj03_ExistProb VFC_Obj03_MeasurementStatus VFC_Obj03_ObjId VFC_Obj03_Type VFC_Obj03_TypeConf VFC_Obj03_VisibleView VFC_Obj03_ClassifiedView VFC_Obj03_Px VFC_Obj03_Py VFC_Obj03_PxStdDev VFC_Obj03_PyStdDev VFC_Obj03_OrientationYaw VFC_Obj03_OrientationYawStdDev VFC_Obj03_Length VFC_Obj03_Width VFC_Obj03_Height VFC_Obj03_LengthStdDev VFC_Obj03_WidthStdDev VFC_Obj03_HeightStdDev VFC_Obj03_Vx VFC_Obj03_Vy VFC_Obj03_VxStdDev VFC_Obj03_VyStdDev VFC_Obj03_Ax VFC_Obj03_LightStatTurnIndicator VFC_Obj03_Ay VFC_Obj03_AxStdDev VFC_Obj03_AyStdDev VFC_Obj03_MovementProbLat VFC_Obj03_MovementProbLong VFC_Obj03_2DAngPosEdgeLeft VFC_Obj03_2DAngPosEdgeRight VFC_Obj03_2DAngPosEdgeFar VFC_Obj03_2DAngPosEdgeBot VFC_Obj03_OutsideRoad VFC_Obj03_2DAngPosEdgeLeftStdDev VFC_Obj03_2DAngPosEdgeRightStdDe VFC_Obj03_2DAngPosEdgeFarStdDev VFC_Obj03_2DAngPosEdgeBotStdDev VFC_Obj03_2DNormVx VFC_Obj03_2DNormVy VFC_Obj03_2DNormAx VFC_Obj03_2DNormVxStdDev VFC_Obj03_MeasurementSource VFC_Obj03_2DNormVyStdDev VFC_Obj03_2DNormAxStdDev VFC_Obj03_2DScaleChange VFC_Obj03_2DScaleChangeStdDev VFC_Obj03_Reliability VFC_Obj03_LightStatBrakeLight VFC_Obj03_OutsideRoadMeasStatus VFC_Obj03_Oncoming VFC_Obj03_OncomingMeasStatus VFC_Obj03_MovementStanding VFC_Obj03_MovementStandingMeasSt VFC_Obj03_MovementObserved VFC_Obj03_MovementObservedMeasSt VFC_Obj03_TargetObjTypeAcc VFC_Obj03_TargetObjTypeAccConf;
SIG_GROUP_ 58 SG_VFC_Object04 1 : VFC_Obj04_CRC VFC_Obj04_AliveCtr VFC_Obj04_ProtBlockCtr VFC_Obj04_ExistProb VFC_Obj04_MeasurementStatus VFC_Obj04_ObjId VFC_Obj04_Type VFC_Obj04_TypeConf VFC_Obj04_VisibleView VFC_Obj04_ClassifiedView VFC_Obj04_Px VFC_Obj04_Py VFC_Obj04_PxStdDev VFC_Obj04_PyStdDev VFC_Obj04_OrientationYaw VFC_Obj04_OrientationYawStdDev VFC_Obj04_Length VFC_Obj04_Width VFC_Obj04_Height VFC_Obj04_LengthStdDev VFC_Obj04_WidthStdDev VFC_Obj04_HeightStdDev VFC_Obj04_Vx VFC_Obj04_Vy VFC_Obj04_VxStdDev VFC_Obj04_VyStdDev VFC_Obj04_Ax VFC_Obj04_LightStatTurnIndicator VFC_Obj04_Ay VFC_Obj04_AxStdDev VFC_Obj04_AyStdDev VFC_Obj04_MovementProbLat VFC_Obj04_MovementProbLong VFC_Obj04_2DAngPosEdgeLeft VFC_Obj04_2DAngPosEdgeRight VFC_Obj04_2DAngPosEdgeFar VFC_Obj04_2DAngPosEdgeBot VFC_Obj04_OutsideRoad VFC_Obj04_2DAngPosEdgeLeftStdDev VFC_Obj04_2DAngPosEdgeRightStdDe VFC_Obj04_2DAngPosEdgeFarStdDev VFC_Obj04_2DAngPosEdgeBotStdDev VFC_Obj04_2DNormVx VFC_Obj04_2DNormVy VFC_Obj04_2DNormAx VFC_Obj04_2DNormVxStdDev VFC_Obj04_MeasurementSource VFC_Obj04_2DNormVyStdDev VFC_Obj04_2DNormAxStdDev VFC_Obj04_2DScaleChange VFC_Obj04_2DScaleChangeStdDev VFC_Obj04_Reliability VFC_Obj04_LightStatBrakeLight VFC_Obj04_OutsideRoadMeasStatus VFC_Obj04_Oncoming VFC_Obj04_OncomingMeasStatus VFC_Obj04_MovementStanding VFC_Obj04_MovementStandingMeasSt VFC_Obj04_MovementObserved VFC_Obj04_MovementObservedMeasSt VFC_Obj04_TargetObjTypeAcc VFC_Obj04_TargetObjTypeAccConf;
SIG_GROUP_ 59 SG_VFC_Object05 1 : VFC_Obj05_CRC VFC_Obj05_AliveCtr VFC_Obj05_ProtBlockCtr VFC_Obj05_ExistProb VFC_Obj05_MeasurementStatus VFC_Obj05_ObjId VFC_Obj05_Type VFC_Obj05_TypeConf VFC_Obj05_VisibleView VFC_Obj05_ClassifiedView VFC_Obj05_Px VFC_Obj05_Py VFC_Obj05_PxStdDev VFC_Obj05_PyStdDev VFC_Obj05_OrientationYaw VFC_Obj05_OrientationYawStdDev VFC_Obj05_Length VFC_Obj05_Width VFC_Obj05_Height VFC_Obj05_LengthStdDev VFC_Obj05_WidthStdDev VFC_Obj05_HeightStdDev VFC_Obj05_Vx VFC_Obj05_Vy VFC_Obj05_VxStdDev VFC_Obj05_VyStdDev VFC_Obj05_Ax VFC_Obj05_LightStatTurnIndicator VFC_Obj05_Ay VFC_Obj05_AxStdDev VFC_Obj05_AyStdDev VFC_Obj05_MovementProbLat VFC_Obj05_MovementProbLong VFC_Obj05_2DAngPosEdgeLeft VFC_Obj05_2DAngPosEdgeRight VFC_Obj05_2DAngPosEdgeFar VFC_Obj05_2DAngPosEdgeBot VFC_Obj05_OutsideRoad VFC_Obj05_2DAngPosEdgeLeftStdDev VFC_Obj05_2DAngPosEdgeRightStdDe VFC_Obj05_2DAngPosEdgeFarStdDev VFC_Obj05_2DAngPosEdgeBotStdDev VFC_Obj05_2DNormVx VFC_Obj05_2DNormVy VFC_Obj05_2DNormAx VFC_Obj05_2DNormVxStdDev VFC_Obj05_MeasurementSource VFC_Obj05_2DNormVyStdDev VFC_Obj05_2DNormAxStdDev VFC_Obj05_2DScaleChange VFC_Obj05_2DScaleChangeStdDev VFC_Obj05_Reliability VFC_Obj05_LightStatBrakeLight VFC_Obj05_OutsideRoadMeasStatus VFC_Obj05_Oncoming VFC_Obj05_OncomingMeasStatus VFC_Obj05_MovementStanding VFC_Obj05_MovementStandingMeasSt VFC_Obj05_MovementObserved VFC_Obj05_MovementObservedMeasSt VFC_Obj05_TargetObjTypeAcc VFC_Obj05_TargetObjTypeAccConf;
SIG_GROUP_ 60 SG_VFC_Object06 1 : VFC_Obj06_CRC VFC_Obj06_AliveCtr VFC_Obj06_ProtBlockCtr VFC_Obj06_ExistProb VFC_Obj06_MeasurementStatus VFC_Obj06_ObjId VFC_Obj06_Type VFC_Obj06_TypeConf VFC_Obj06_VisibleView VFC_Obj06_ClassifiedView VFC_Obj06_Px VFC_Obj06_Py VFC_Obj06_PxStdDev VFC_Obj06_PyStdDev VFC_Obj06_OrientationYaw VFC_Obj06_OrientationYawStdDev VFC_Obj06_Length VFC_Obj06_Width VFC_Obj06_Height VFC_Obj06_LengthStdDev VFC_Obj06_WidthStdDev VFC_Obj06_HeightStdDev VFC_Obj06_Vx VFC_Obj06_Vy VFC_Obj06_VxStdDev VFC_Obj06_VyStdDev VFC_Obj06_Ax VFC_Obj06_LightStatTurnIndicator VFC_Obj06_Ay VFC_Obj06_AxStdDev VFC_Obj06_AyStdDev VFC_Obj06_MovementProbLat VFC_Obj06_MovementProbLong VFC_Obj06_2DAngPosEdgeLeft VFC_Obj06_2DAngPosEdgeRight VFC_Obj06_2DAngPosEdgeFar VFC_Obj06_2DAngPosEdgeBot VFC_Obj06_OutsideRoad VFC_Obj06_2DAngPosEdgeLeftStdDev VFC_Obj06_2DAngPosEdgeRightStdDe VFC_Obj06_2DAngPosEdgeFarStdDev VFC_Obj06_2DAngPosEdgeBotStdDev VFC_Obj06_2DNormVx VFC_Obj06_2DNormVy VFC_Obj06_2DNormAx VFC_Obj06_2DNormVxStdDev VFC_Obj06_MeasurementSource VFC_Obj06_2DNormVyStdDev VFC_Obj06_2DNormAxStdDev VFC_Obj06_2DScaleChange VFC_Obj06_2DScaleChangeStdDev VFC_Obj06_Reliability VFC_Obj06_LightStatBrakeLight VFC_Obj06_OutsideRoadMeasStatus VFC_Obj06_Oncoming VFC_Obj06_OncomingMeasStatus VFC_Obj06_MovementStanding VFC_Obj06_MovementStandingMeasSt VFC_Obj06_MovementObserved VFC_Obj06_MovementObservedMeasSt VFC_Obj06_TargetObjTypeAcc VFC_Obj06_TargetObjTypeAccConf;
SIG_GROUP_ 61 SG_VFC_Object07 1 : VFC_Obj07_CRC VFC_Obj07_AliveCtr VFC_Obj07_ProtBlockCtr VFC_Obj07_ExistProb VFC_Obj07_MeasurementStatus VFC_Obj07_ObjId VFC_Obj07_Type VFC_Obj07_TypeConf VFC_Obj07_VisibleView VFC_Obj07_ClassifiedView VFC_Obj07_Px VFC_Obj07_Py VFC_Obj07_PxStdDev VFC_Obj07_PyStdDev VFC_Obj07_OrientationYaw VFC_Obj07_OrientationYawStdDev VFC_Obj07_Length VFC_Obj07_Width VFC_Obj07_Height VFC_Obj07_LengthStdDev VFC_Obj07_WidthStdDev VFC_Obj07_HeightStdDev VFC_Obj07_Vx VFC_Obj07_Vy VFC_Obj07_VxStdDev VFC_Obj07_VyStdDev VFC_Obj07_Ax VFC_Obj07_LightStatTurnIndicator VFC_Obj07_Ay VFC_Obj07_AxStdDev VFC_Obj07_AyStdDev VFC_Obj07_MovementProbLat VFC_Obj07_MovementProbLong VFC_Obj07_2DAngPosEdgeLeft VFC_Obj07_2DAngPosEdgeRight VFC_Obj07_2DAngPosEdgeFar VFC_Obj07_2DAngPosEdgeBot VFC_Obj07_OutsideRoad VFC_Obj07_2DAngPosEdgeLeftStdDev VFC_Obj07_2DAngPosEdgeRightStdDe VFC_Obj07_2DAngPosEdgeFarStdDev VFC_Obj07_2DAngPosEdgeBotStdDev VFC_Obj07_2DNormVx VFC_Obj07_2DNormVy VFC_Obj07_2DNormAx VFC_Obj07_2DNormVxStdDev VFC_Obj07_MeasurementSource VFC_Obj07_2DNormVyStdDev VFC_Obj07_2DNormAxStdDev VFC_Obj07_2DScaleChange VFC_Obj07_2DScaleChangeStdDev VFC_Obj07_Reliability VFC_Obj07_LightStatBrakeLight VFC_Obj07_OutsideRoadMeasStatus VFC_Obj07_Oncoming VFC_Obj07_OncomingMeasStatus VFC_Obj07_MovementStanding VFC_Obj07_MovementStandingMeasSt VFC_Obj07_MovementObserved VFC_Obj07_MovementObservedMeasSt VFC_Obj07_TargetObjTypeAcc VFC_Obj07_TargetObjTypeAccConf;
SIG_GROUP_ 62 SG_VFC_Object08 1 : VFC_Obj08_CRC VFC_Obj08_AliveCtr VFC_Obj08_ProtBlockCtr VFC_Obj08_ExistProb VFC_Obj08_MeasurementStatus VFC_Obj08_ObjId VFC_Obj08_Type VFC_Obj08_TypeConf VFC_Obj08_VisibleView VFC_Obj08_ClassifiedView VFC_Obj08_Px VFC_Obj08_Py VFC_Obj08_PxStdDev VFC_Obj08_PyStdDev VFC_Obj08_OrientationYaw VFC_Obj08_OrientationYawStdDev VFC_Obj08_Length VFC_Obj08_Width VFC_Obj08_Height VFC_Obj08_LengthStdDev VFC_Obj08_WidthStdDev VFC_Obj08_HeightStdDev VFC_Obj08_Vx VFC_Obj08_Vy VFC_Obj08_VxStdDev VFC_Obj08_VyStdDev VFC_Obj08_Ax VFC_Obj08_LightStatTurnIndicator VFC_Obj08_Ay VFC_Obj08_AxStdDev VFC_Obj08_AyStdDev VFC_Obj08_MovementProbLat VFC_Obj08_MovementProbLong VFC_Obj08_2DAngPosEdgeLeft VFC_Obj08_2DAngPosEdgeRight VFC_Obj08_2DAngPosEdgeFar VFC_Obj08_2DAngPosEdgeBot VFC_Obj08_OutsideRoad VFC_Obj08_2DAngPosEdgeLeftStdDev VFC_Obj08_2DAngPosEdgeRightStdDe VFC_Obj08_2DAngPosEdgeFarStdDev VFC_Obj08_2DAngPosEdgeBotStdDev VFC_Obj08_2DNormVx VFC_Obj08_2DNormVy VFC_Obj08_2DNormAx VFC_Obj08_2DNormVxStdDev VFC_Obj08_MeasurementSource VFC_Obj08_2DNormVyStdDev VFC_Obj08_2DNormAxStdDev VFC_Obj08_2DScaleChange VFC_Obj08_2DScaleChangeStdDev VFC_Obj08_Reliability VFC_Obj08_LightStatBrakeLight VFC_Obj08_OutsideRoadMeasStatus VFC_Obj08_Oncoming VFC_Obj08_OncomingMeasStatus VFC_Obj08_MovementStanding VFC_Obj08_MovementStandingMeasSt VFC_Obj08_MovementObserved VFC_Obj08_MovementObservedMeasSt VFC_Obj08_TargetObjTypeAcc VFC_Obj08_TargetObjTypeAccConf;
SIG_GROUP_ 63 SG_VFC_Object09 1 : VFC_Obj09_CRC VFC_Obj09_AliveCtr VFC_Obj09_ProtBlockCtr VFC_Obj09_ExistProb VFC_Obj09_MeasurementStatus VFC_Obj09_ObjId VFC_Obj09_Type VFC_Obj09_TypeConf VFC_Obj09_VisibleView VFC_Obj09_ClassifiedView VFC_Obj09_Px VFC_Obj09_Py VFC_Obj09_PxStdDev VFC_Obj09_PyStdDev VFC_Obj09_OrientationYaw VFC_Obj09_OrientationYawStdDev VFC_Obj09_Length VFC_Obj09_Width VFC_Obj09_Height VFC_Obj09_LengthStdDev VFC_Obj09_WidthStdDev VFC_Obj09_HeightStdDev VFC_Obj09_Vx VFC_Obj09_Vy VFC_Obj09_VxStdDev VFC_Obj09_VyStdDev VFC_Obj09_Ax VFC_Obj09_LightStatTurnIndicator VFC_Obj09_Ay VFC_Obj09_AxStdDev VFC_Obj09_AyStdDev VFC_Obj09_MovementProbLat VFC_Obj09_MovementProbLong VFC_Obj09_2DAngPosEdgeLeft VFC_Obj09_2DAngPosEdgeRight VFC_Obj09_2DAngPosEdgeFar VFC_Obj09_2DAngPosEdgeBot VFC_Obj09_OutsideRoad VFC_Obj09_2DAngPosEdgeLeftStdDev VFC_Obj09_2DAngPosEdgeRightStdDe VFC_Obj09_2DAngPosEdgeFarStdDev VFC_Obj09_2DAngPosEdgeBotStdDev VFC_Obj09_2DNormVx VFC_Obj09_2DNormVy VFC_Obj09_2DNormAx VFC_Obj09_2DNormVxStdDev VFC_Obj09_MeasurementSource VFC_Obj09_2DNormVyStdDev VFC_Obj09_2DNormAxStdDev VFC_Obj09_2DScaleChange VFC_Obj09_2DScaleChangeStdDev VFC_Obj09_Reliability VFC_Obj09_LightStatBrakeLight VFC_Obj09_OutsideRoadMeasStatus VFC_Obj09_Oncoming VFC_Obj09_OncomingMeasStatus VFC_Obj09_MovementStanding VFC_Obj09_MovementStandingMeasSt VFC_Obj09_MovementObserved VFC_Obj09_MovementObservedMeasSt VFC_Obj09_TargetObjTypeAcc VFC_Obj09_TargetObjTypeAccConf;
